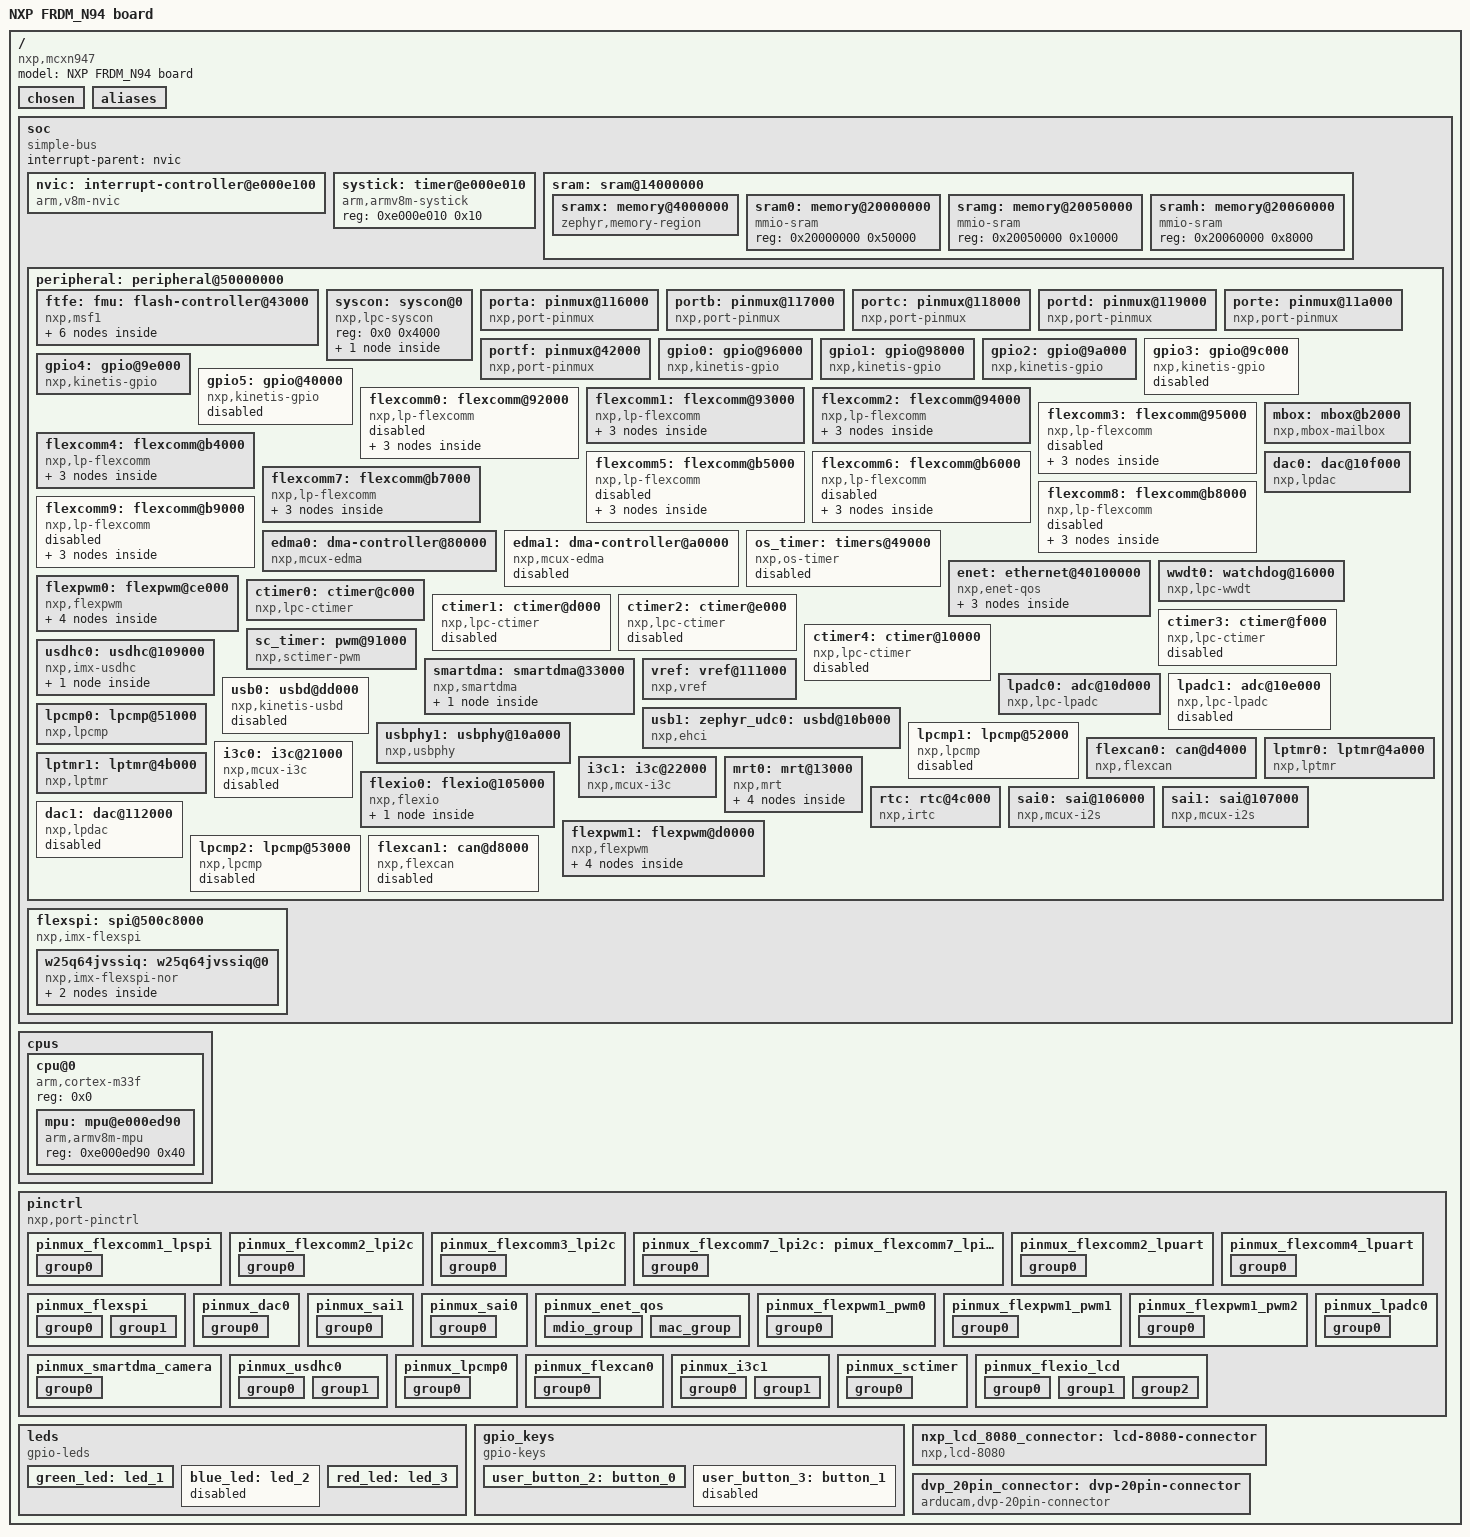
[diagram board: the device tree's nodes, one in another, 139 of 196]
/dts-v1/;

/* node '/' defined in zephyr/dts/common/skeleton.dtsi:9 */
/ {
	#address-cells = < 0x1 >;     /* in zephyr/dts/common/skeleton.dtsi:10 */
	#size-cells = < 0x1 >;        /* in zephyr/dts/common/skeleton.dtsi:11 */
	model = "NXP FRDM_N94 board"; /* in zephyr/boards/nxp/frdm_mcxn947/frdm_mcxn947_mcxn947_cpu0.dts:12 */
	compatible = "nxp,mcxn947",
	             "nxp,mcx";       /* in zephyr/boards/nxp/frdm_mcxn947/frdm_mcxn947_mcxn947_cpu0.dts:13 */

	/* node '/chosen' defined in zephyr/dts/common/skeleton.dtsi:12 */
	chosen {
		zephyr,sram = &sram0;                          /* in zephyr/boards/nxp/frdm_mcxn947/frdm_mcxn947_mcxn947_cpu0.dtsi:22 */
		zephyr,flash = &flash;                         /* in zephyr/boards/nxp/frdm_mcxn947/frdm_mcxn947_mcxn947_cpu0.dtsi:23 */
		zephyr,flash-controller = &fmu;                /* in zephyr/boards/nxp/frdm_mcxn947/frdm_mcxn947_mcxn947_cpu0.dtsi:24 */
		zephyr,code-partition = &slot0_partition;      /* in zephyr/boards/nxp/frdm_mcxn947/frdm_mcxn947_mcxn947_cpu0.dtsi:25 */
		zephyr,uart-mcumgr = &flexcomm4_lpuart4;       /* in zephyr/boards/nxp/frdm_mcxn947/frdm_mcxn947_mcxn947_cpu0.dtsi:26 */
		zephyr,console = &flexcomm4_lpuart4;           /* in zephyr/boards/nxp/frdm_mcxn947/frdm_mcxn947_mcxn947_cpu0.dtsi:27 */
		zephyr,shell-uart = &flexcomm4_lpuart4;        /* in zephyr/boards/nxp/frdm_mcxn947/frdm_mcxn947_mcxn947_cpu0.dtsi:28 */
		zephyr,canbus = &flexcan0;                     /* in zephyr/boards/nxp/frdm_mcxn947/frdm_mcxn947_mcxn947_cpu0.dtsi:29 */
		zephyr,code-cpu1-partition = &slot1_partition; /* in zephyr/boards/nxp/frdm_mcxn947/frdm_mcxn947_mcxn947_cpu0.dtsi:30 */
	};

	/* node '/aliases' defined in zephyr/dts/common/skeleton.dtsi:13 */
	aliases {
		led0 = &red_led;                  /* in zephyr/boards/nxp/frdm_mcxn947/frdm_mcxn947.dtsi:14 */
		led1 = &green_led;                /* in zephyr/boards/nxp/frdm_mcxn947/frdm_mcxn947.dtsi:15 */
		led2 = &blue_led;                 /* in zephyr/boards/nxp/frdm_mcxn947/frdm_mcxn947.dtsi:16 */
		sw0 = &user_button_2;             /* in zephyr/boards/nxp/frdm_mcxn947/frdm_mcxn947.dtsi:17 */
		sw1 = &user_button_3;             /* in zephyr/boards/nxp/frdm_mcxn947/frdm_mcxn947.dtsi:18 */
		sdhc0 = &usdhc0;                  /* in zephyr/boards/nxp/frdm_mcxn947/frdm_mcxn947.dtsi:19 */
		mcuboot-button0 = &user_button_2; /* in zephyr/boards/nxp/frdm_mcxn947/frdm_mcxn947.dtsi:20 */
		watchdog0 = &wwdt0;               /* in zephyr/boards/nxp/frdm_mcxn947/frdm_mcxn947_mcxn947_cpu0.dtsi:34 */
		pwm-0 = &flexpwm1_pwm0;           /* in zephyr/boards/nxp/frdm_mcxn947/frdm_mcxn947_mcxn947_cpu0.dtsi:35 */
		pwm-1 = &sc_timer;                /* in zephyr/boards/nxp/frdm_mcxn947/frdm_mcxn947_mcxn947_cpu0.dtsi:36 */
		rtc = &rtc;                       /* in zephyr/boards/nxp/frdm_mcxn947/frdm_mcxn947_mcxn947_cpu0.dtsi:37 */
	};

	/* node '/soc' defined in zephyr/dts/arm/armv8-m.dtsi:6 */
	soc {
		#address-cells = < 0x1 >;     /* in zephyr/dts/arm/armv8-m.dtsi:7 */
		#size-cells = < 0x1 >;        /* in zephyr/dts/arm/armv8-m.dtsi:8 */
		compatible = "simple-bus";    /* in zephyr/dts/arm/armv8-m.dtsi:9 */
		interrupt-parent = < &nvic >; /* in zephyr/dts/arm/armv8-m.dtsi:10 */
		ranges;                       /* in zephyr/dts/arm/armv8-m.dtsi:11 */

		/* node '/soc/interrupt-controller@e000e100' defined in zephyr/dts/arm/armv8-m.dtsi:13 */
		nvic: interrupt-controller@e000e100 {
			#address-cells = < 0x1 >;            /* in zephyr/dts/arm/armv8-m.dtsi:14 */
			compatible = "arm,v8m-nvic";         /* in zephyr/dts/arm/armv8-m.dtsi:15 */
			reg = < 0xe000e100 0xc00 >;          /* in zephyr/dts/arm/armv8-m.dtsi:16 */
			interrupt-controller;                /* in zephyr/dts/arm/armv8-m.dtsi:17 */
			#interrupt-cells = < 0x2 >;          /* in zephyr/dts/arm/armv8-m.dtsi:18 */
			arm,num-irq-priority-bits = < 0x3 >; /* in zephyr/dts/arm/nxp/nxp_mcxnx4x_common.dtsi:1074 */
			phandle = < 0x1 >;                   /* in zephyr/dts/arm/armv8-m.dtsi:10 */
		};

		/* node '/soc/timer@e000e010' defined in zephyr/dts/arm/armv8-m.dtsi:21 */
		systick: timer@e000e010 {
			compatible = "arm,armv8m-systick"; /* in zephyr/dts/arm/armv8-m.dtsi:22 */
			reg = < 0xe000e010 0x10 >;         /* in zephyr/dts/arm/armv8-m.dtsi:23 */
			status = "okay";                   /* in zephyr/boards/nxp/frdm_mcxn947/frdm_mcxn947.dtsi:128 */
		};

		/* node '/soc/sram@14000000' defined in zephyr/dts/arm/nxp/nxp_mcxn94x.dtsi:12 */
		sram: sram@14000000 {
			ranges = < 0x4000000 0x14000000 0x20000000 >; /* in zephyr/dts/arm/nxp/nxp_mcxn94x.dtsi:13 */
			#address-cells = < 0x1 >;                     /* in zephyr/dts/arm/nxp/nxp_mcxnx4x_common.dtsi:45 */
			#size-cells = < 0x1 >;                        /* in zephyr/dts/arm/nxp/nxp_mcxnx4x_common.dtsi:46 */

			/* node '/soc/sram@14000000/memory@4000000' defined in zephyr/dts/arm/nxp/nxp_mcxnx4x_common.dtsi:48 */
			sramx: memory@4000000 {
				compatible = "zephyr,memory-region",
				             "mmio-sram";            /* in zephyr/dts/arm/nxp/nxp_mcxnx4x_common.dtsi:49 */
				reg = < 0x4000000 0x18000 >;         /* in zephyr/dts/arm/nxp/nxp_mcxnx4x_common.dtsi:50 */
				zephyr,memory-region = "SRAMX";      /* in zephyr/dts/arm/nxp/nxp_mcxnx4x_common.dtsi:51 */
				zephyr,memory-attr = < 0x100000 >;   /* in zephyr/dts/arm/nxp/nxp_mcxnx4x_common.dtsi:52 */
			};

			/* node '/soc/sram@14000000/memory@20000000' defined in zephyr/dts/arm/nxp/nxp_mcxnx4x_common.dtsi:63 */
			sram0: memory@20000000 {
				compatible = "mmio-sram";     /* in zephyr/boards/nxp/frdm_mcxn947/frdm_mcxn947_mcxn947_cpu0.dtsi:51 */
				reg = < 0x20000000 0x50000 >; /* in zephyr/boards/nxp/frdm_mcxn947/frdm_mcxn947_mcxn947_cpu0.dtsi:52 */
			};

			/* node '/soc/sram@14000000/memory@20050000' defined in zephyr/boards/nxp/frdm_mcxn947/frdm_mcxn947.dtsi:132 */
			sramg: memory@20050000 {
				compatible = "mmio-sram";     /* in zephyr/boards/nxp/frdm_mcxn947/frdm_mcxn947.dtsi:133 */
				reg = < 0x20050000 0x10000 >; /* in zephyr/boards/nxp/frdm_mcxn947/frdm_mcxn947.dtsi:134 */
			};

			/* node '/soc/sram@14000000/memory@20060000' defined in zephyr/boards/nxp/frdm_mcxn947/frdm_mcxn947.dtsi:136 */
			sramh: memory@20060000 {
				compatible = "mmio-sram";    /* in zephyr/boards/nxp/frdm_mcxn947/frdm_mcxn947.dtsi:137 */
				reg = < 0x20060000 0x8000 >; /* in zephyr/boards/nxp/frdm_mcxn947/frdm_mcxn947.dtsi:138 */
			};
		};

		/* node '/soc/peripheral@50000000' defined in zephyr/dts/arm/nxp/nxp_mcxn94x.dtsi:16 */
		peripheral: peripheral@50000000 {
			ranges = < 0x0 0x50000000 0x10000000 >; /* in zephyr/dts/arm/nxp/nxp_mcxn94x.dtsi:17 */
			#address-cells = < 0x1 >;               /* in zephyr/dts/arm/nxp/nxp_mcxnx4x_common.dtsi:70 */
			#size-cells = < 0x1 >;                  /* in zephyr/dts/arm/nxp/nxp_mcxnx4x_common.dtsi:71 */

			/* node '/soc/peripheral@50000000/flash-controller@43000' defined in zephyr/dts/arm/nxp/nxp_mcxn94x.dtsi:19 */
			ftfe: fmu: flash-controller@43000 {
				ranges = < 0x0 0x10000000 0x4000000 >; /* in zephyr/dts/arm/nxp/nxp_mcxn94x.dtsi:20 */
				compatible = "nxp,msf1";               /* in zephyr/dts/arm/nxp/nxp_mcxnx4x_common.dtsi:620 */
				reg = < 0x43000 0x1000 >;              /* in zephyr/dts/arm/nxp/nxp_mcxnx4x_common.dtsi:621 */
				interrupts = < 0x8a 0x0 >;             /* in zephyr/dts/arm/nxp/nxp_mcxnx4x_common.dtsi:622 */
				#address-cells = < 0x1 >;              /* in zephyr/dts/arm/nxp/nxp_mcxnx4x_common.dtsi:625 */
				#size-cells = < 0x1 >;                 /* in zephyr/dts/arm/nxp/nxp_mcxnx4x_common.dtsi:626 */
				status = "okay";                       /* in zephyr/dts/arm/nxp/nxp_mcxn94x.dtsi:37 */

				/* node '/soc/peripheral@50000000/flash-controller@43000/flash@0' defined in zephyr/dts/arm/nxp/nxp_mcxnx4x_common.dtsi:628 */
				flash: flash@0 {
					compatible = "soc-nv-flash";   /* in zephyr/dts/arm/nxp/nxp_mcxnx4x_common.dtsi:629 */
					reg = < 0x0 0x200000 >;        /* in zephyr/dts/arm/nxp/nxp_mcxnx4x_common.dtsi:630 */
					erase-block-size = < 0x2000 >; /* in zephyr/dts/arm/nxp/nxp_mcxnx4x_common.dtsi:631 */
					write-block-size = < 0x10 >;   /* in zephyr/dts/arm/nxp/nxp_mcxnx4x_common.dtsi:632 */

					/* node '/soc/peripheral@50000000/flash-controller@43000/flash@0/partitions' defined in zephyr/boards/nxp/frdm_mcxn947/frdm_mcxn947.dtsi:143 */
					partitions {
						compatible = "fixed-partitions"; /* in zephyr/boards/nxp/frdm_mcxn947/frdm_mcxn947.dtsi:144 */
						#address-cells = < 0x1 >;        /* in zephyr/boards/nxp/frdm_mcxn947/frdm_mcxn947.dtsi:145 */
						#size-cells = < 0x1 >;           /* in zephyr/boards/nxp/frdm_mcxn947/frdm_mcxn947.dtsi:146 */

						/* node '/soc/peripheral@50000000/flash-controller@43000/flash@0/partitions/partition@0' defined in zephyr/boards/nxp/frdm_mcxn947/frdm_mcxn947.dtsi:152 */
						boot_partition: partition@0 {
							label = "mcuboot";     /* in zephyr/boards/nxp/frdm_mcxn947/frdm_mcxn947.dtsi:153 */
							reg = < 0x0 0x14000 >; /* in zephyr/boards/nxp/frdm_mcxn947/frdm_mcxn947.dtsi:154 */
						};

						/* node '/soc/peripheral@50000000/flash-controller@43000/flash@0/partitions/partition@14000' defined in zephyr/boards/nxp/frdm_mcxn947/frdm_mcxn947.dtsi:156 */
						slot0_partition: partition@14000 {
							label = "image-0";         /* in zephyr/boards/nxp/frdm_mcxn947/frdm_mcxn947.dtsi:157 */
							reg = < 0x14000 0xf6000 >; /* in zephyr/boards/nxp/frdm_mcxn947/frdm_mcxn947.dtsi:158 */
						};

						/* node '/soc/peripheral@50000000/flash-controller@43000/flash@0/partitions/partition@10A000' defined in zephyr/boards/nxp/frdm_mcxn947/frdm_mcxn947.dtsi:160 */
						slot1_partition: partition@10A000 {
							label = "image-1";          /* in zephyr/boards/nxp/frdm_mcxn947/frdm_mcxn947.dtsi:161 */
							reg = < 0x10a000 0xf6000 >; /* in zephyr/boards/nxp/frdm_mcxn947/frdm_mcxn947.dtsi:162 */
						};
					};
				};

				/* node '/soc/peripheral@50000000/flash-controller@43000/uuid@1100000' defined in zephyr/dts/arm/nxp/nxp_mcxnx4x_common.dtsi:635 */
				uuid: uuid@1100000 {
					compatible = "nxp,lpc-uid"; /* in zephyr/dts/arm/nxp/nxp_mcxnx4x_common.dtsi:636 */
					reg = < 0x1100000 0x10 >;   /* in zephyr/dts/arm/nxp/nxp_mcxnx4x_common.dtsi:637 */
				};
			};

			/* node '/soc/peripheral@50000000/syscon@0' defined in zephyr/dts/arm/nxp/nxp_mcxnx4x_common.dtsi:73 */
			syscon: syscon@0 {
				compatible = "nxp,lpc-syscon"; /* in zephyr/dts/arm/nxp/nxp_mcxnx4x_common.dtsi:74 */
				reg = < 0x0 0x4000 >;          /* in zephyr/dts/arm/nxp/nxp_mcxnx4x_common.dtsi:75 */
				#clock-cells = < 0x1 >;        /* in zephyr/dts/arm/nxp/nxp_mcxnx4x_common.dtsi:76 */
				phandle = < 0x2 >;             /* in zephyr/dts/arm/nxp/nxp_mcxnx4x_common.dtsi:86 */

				/* node '/soc/peripheral@50000000/syscon@0/reset' defined in zephyr/dts/arm/nxp/nxp_mcxnx4x_common.dtsi:77 */
				reset: reset {
					compatible = "nxp,lpc-syscon-reset"; /* in zephyr/dts/arm/nxp/nxp_mcxnx4x_common.dtsi:78 */
					#reset-cells = < 0x1 >;              /* in zephyr/dts/arm/nxp/nxp_mcxnx4x_common.dtsi:79 */
					phandle = < 0x1f >;                  /* in zephyr/dts/arm/nxp/nxp_mcxnx4x_common.dtsi:981 */
				};
			};

			/* node '/soc/peripheral@50000000/pinmux@116000' defined in zephyr/dts/arm/nxp/nxp_mcxnx4x_common.dtsi:83 */
			porta: pinmux@116000 {
				compatible = "nxp,port-pinmux"; /* in zephyr/dts/arm/nxp/nxp_mcxnx4x_common.dtsi:84 */
				reg = < 0x116000 0x1000 >;      /* in zephyr/dts/arm/nxp/nxp_mcxnx4x_common.dtsi:85 */
				clocks = < &syscon 0xc00 >;     /* in zephyr/dts/arm/nxp/nxp_mcxnx4x_common.dtsi:86 */
				phandle = < 0x3 >;              /* in zephyr/dts/arm/nxp/nxp_mcxnx4x_common.dtsi:126 */
			};

			/* node '/soc/peripheral@50000000/pinmux@117000' defined in zephyr/dts/arm/nxp/nxp_mcxnx4x_common.dtsi:89 */
			portb: pinmux@117000 {
				compatible = "nxp,port-pinmux"; /* in zephyr/dts/arm/nxp/nxp_mcxnx4x_common.dtsi:90 */
				reg = < 0x117000 0x1000 >;      /* in zephyr/dts/arm/nxp/nxp_mcxnx4x_common.dtsi:91 */
				clocks = < &syscon 0xc01 >;     /* in zephyr/dts/arm/nxp/nxp_mcxnx4x_common.dtsi:92 */
				phandle = < 0x4 >;              /* in zephyr/dts/arm/nxp/nxp_mcxnx4x_common.dtsi:136 */
			};

			/* node '/soc/peripheral@50000000/pinmux@118000' defined in zephyr/dts/arm/nxp/nxp_mcxnx4x_common.dtsi:95 */
			portc: pinmux@118000 {
				compatible = "nxp,port-pinmux"; /* in zephyr/dts/arm/nxp/nxp_mcxnx4x_common.dtsi:96 */
				reg = < 0x118000 0x1000 >;      /* in zephyr/dts/arm/nxp/nxp_mcxnx4x_common.dtsi:97 */
				clocks = < &syscon 0xc02 >;     /* in zephyr/dts/arm/nxp/nxp_mcxnx4x_common.dtsi:98 */
				phandle = < 0x5 >;              /* in zephyr/dts/arm/nxp/nxp_mcxnx4x_common.dtsi:146 */
			};

			/* node '/soc/peripheral@50000000/pinmux@119000' defined in zephyr/dts/arm/nxp/nxp_mcxnx4x_common.dtsi:101 */
			portd: pinmux@119000 {
				compatible = "nxp,port-pinmux"; /* in zephyr/dts/arm/nxp/nxp_mcxnx4x_common.dtsi:102 */
				reg = < 0x119000 0x1000 >;      /* in zephyr/dts/arm/nxp/nxp_mcxnx4x_common.dtsi:103 */
				clocks = < &syscon 0xc03 >;     /* in zephyr/dts/arm/nxp/nxp_mcxnx4x_common.dtsi:104 */
				phandle = < 0x6 >;              /* in zephyr/dts/arm/nxp/nxp_mcxnx4x_common.dtsi:156 */
			};

			/* node '/soc/peripheral@50000000/pinmux@11a000' defined in zephyr/dts/arm/nxp/nxp_mcxnx4x_common.dtsi:107 */
			porte: pinmux@11a000 {
				compatible = "nxp,port-pinmux"; /* in zephyr/dts/arm/nxp/nxp_mcxnx4x_common.dtsi:108 */
				reg = < 0x11a000 0x1000 >;      /* in zephyr/dts/arm/nxp/nxp_mcxnx4x_common.dtsi:109 */
				clocks = < &syscon 0xc04 >;     /* in zephyr/dts/arm/nxp/nxp_mcxnx4x_common.dtsi:110 */
				phandle = < 0x7 >;              /* in zephyr/dts/arm/nxp/nxp_mcxnx4x_common.dtsi:166 */
			};

			/* node '/soc/peripheral@50000000/pinmux@42000' defined in zephyr/dts/arm/nxp/nxp_mcxnx4x_common.dtsi:113 */
			portf: pinmux@42000 {
				compatible = "nxp,port-pinmux"; /* in zephyr/dts/arm/nxp/nxp_mcxnx4x_common.dtsi:114 */
				reg = < 0x42000 0x1000 >;       /* in zephyr/dts/arm/nxp/nxp_mcxnx4x_common.dtsi:115 */
				clocks = < &syscon 0xc05 >;     /* in zephyr/dts/arm/nxp/nxp_mcxnx4x_common.dtsi:116 */
				phandle = < 0x8 >;              /* in zephyr/dts/arm/nxp/nxp_mcxnx4x_common.dtsi:176 */
			};

			/* node '/soc/peripheral@50000000/gpio@96000' defined in zephyr/dts/arm/nxp/nxp_mcxnx4x_common.dtsi:119 */
			gpio0: gpio@96000 {
				compatible = "nxp,kinetis-gpio"; /* in zephyr/dts/arm/nxp/nxp_mcxnx4x_common.dtsi:120 */
				reg = < 0x96000 0x1000 >;        /* in zephyr/dts/arm/nxp/nxp_mcxnx4x_common.dtsi:122 */
				interrupts = < 0x11 0x0 >,
				             < 0x12 0x0 >;       /* in zephyr/dts/arm/nxp/nxp_mcxnx4x_common.dtsi:123 */
				gpio-controller;                 /* in zephyr/dts/arm/nxp/nxp_mcxnx4x_common.dtsi:124 */
				#gpio-cells = < 0x2 >;           /* in zephyr/dts/arm/nxp/nxp_mcxnx4x_common.dtsi:125 */
				nxp,kinetis-port = < &porta >;   /* in zephyr/dts/arm/nxp/nxp_mcxnx4x_common.dtsi:126 */
				status = "okay";                 /* in zephyr/boards/nxp/frdm_mcxn947/frdm_mcxn947_mcxn947_cpu0.dtsi:68 */
				phandle = < 0x1d >;              /* in zephyr/boards/nxp/frdm_mcxn947/frdm_mcxn947.dtsi:260 */
			};

			/* node '/soc/peripheral@50000000/gpio@98000' defined in zephyr/dts/arm/nxp/nxp_mcxnx4x_common.dtsi:129 */
			gpio1: gpio@98000 {
				compatible = "nxp,kinetis-gpio"; /* in zephyr/dts/arm/nxp/nxp_mcxnx4x_common.dtsi:130 */
				reg = < 0x98000 0x1000 >;        /* in zephyr/dts/arm/nxp/nxp_mcxnx4x_common.dtsi:132 */
				interrupts = < 0x13 0x0 >,
				             < 0x14 0x0 >;       /* in zephyr/dts/arm/nxp/nxp_mcxnx4x_common.dtsi:133 */
				gpio-controller;                 /* in zephyr/dts/arm/nxp/nxp_mcxnx4x_common.dtsi:134 */
				#gpio-cells = < 0x2 >;           /* in zephyr/dts/arm/nxp/nxp_mcxnx4x_common.dtsi:135 */
				nxp,kinetis-port = < &portb >;   /* in zephyr/dts/arm/nxp/nxp_mcxnx4x_common.dtsi:136 */
				status = "okay";                 /* in zephyr/boards/nxp/frdm_mcxn947/frdm_mcxn947_mcxn947_cpu0.dtsi:64 */
				phandle = < 0x26 >;              /* in zephyr/boards/nxp/frdm_mcxn947/frdm_mcxn947.dtsi:31 */
			};

			/* node '/soc/peripheral@50000000/gpio@9a000' defined in zephyr/dts/arm/nxp/nxp_mcxnx4x_common.dtsi:139 */
			gpio2: gpio@9a000 {
				compatible = "nxp,kinetis-gpio"; /* in zephyr/dts/arm/nxp/nxp_mcxnx4x_common.dtsi:140 */
				reg = < 0x9a000 0x1000 >;        /* in zephyr/dts/arm/nxp/nxp_mcxnx4x_common.dtsi:142 */
				interrupts = < 0x15 0x0 >,
				             < 0x16 0x0 >;       /* in zephyr/dts/arm/nxp/nxp_mcxnx4x_common.dtsi:143 */
				gpio-controller;                 /* in zephyr/dts/arm/nxp/nxp_mcxnx4x_common.dtsi:144 */
				#gpio-cells = < 0x2 >;           /* in zephyr/dts/arm/nxp/nxp_mcxnx4x_common.dtsi:145 */
				nxp,kinetis-port = < &portc >;   /* in zephyr/dts/arm/nxp/nxp_mcxnx4x_common.dtsi:146 */
				status = "okay";                 /* in zephyr/boards/nxp/frdm_mcxn947/frdm_mcxn947_mcxn947_cpu0.dtsi:72 */
				phandle = < 0x15 >;              /* in zephyr/boards/nxp/frdm_mcxn947/frdm_mcxn947.dtsi:240 */
			};

			/* node '/soc/peripheral@50000000/gpio@9c000' defined in zephyr/dts/arm/nxp/nxp_mcxnx4x_common.dtsi:149 */
			gpio3: gpio@9c000 {
				compatible = "nxp,kinetis-gpio"; /* in zephyr/dts/arm/nxp/nxp_mcxnx4x_common.dtsi:150 */
				status = "disabled";             /* in zephyr/dts/arm/nxp/nxp_mcxnx4x_common.dtsi:151 */
				reg = < 0x9c000 0x1000 >;        /* in zephyr/dts/arm/nxp/nxp_mcxnx4x_common.dtsi:152 */
				interrupts = < 0x17 0x0 >,
				             < 0x18 0x0 >;       /* in zephyr/dts/arm/nxp/nxp_mcxnx4x_common.dtsi:153 */
				gpio-controller;                 /* in zephyr/dts/arm/nxp/nxp_mcxnx4x_common.dtsi:154 */
				#gpio-cells = < 0x2 >;           /* in zephyr/dts/arm/nxp/nxp_mcxnx4x_common.dtsi:155 */
				nxp,kinetis-port = < &portd >;   /* in zephyr/dts/arm/nxp/nxp_mcxnx4x_common.dtsi:156 */
			};

			/* node '/soc/peripheral@50000000/gpio@9e000' defined in zephyr/dts/arm/nxp/nxp_mcxnx4x_common.dtsi:159 */
			gpio4: gpio@9e000 {
				compatible = "nxp,kinetis-gpio"; /* in zephyr/dts/arm/nxp/nxp_mcxnx4x_common.dtsi:160 */
				reg = < 0x9e000 0x1000 >;        /* in zephyr/dts/arm/nxp/nxp_mcxnx4x_common.dtsi:162 */
				interrupts = < 0x19 0x0 >,
				             < 0x1a 0x0 >;       /* in zephyr/dts/arm/nxp/nxp_mcxnx4x_common.dtsi:163 */
				gpio-controller;                 /* in zephyr/dts/arm/nxp/nxp_mcxnx4x_common.dtsi:164 */
				#gpio-cells = < 0x2 >;           /* in zephyr/dts/arm/nxp/nxp_mcxnx4x_common.dtsi:165 */
				nxp,kinetis-port = < &porte >;   /* in zephyr/dts/arm/nxp/nxp_mcxnx4x_common.dtsi:166 */
				status = "okay";                 /* in zephyr/boards/nxp/frdm_mcxn947/frdm_mcxn947_mcxn947_cpu0.dtsi:60 */
				phandle = < 0x1c >;              /* in zephyr/boards/nxp/frdm_mcxn947/frdm_mcxn947.dtsi:259 */
			};

			/* node '/soc/peripheral@50000000/gpio@40000' defined in zephyr/dts/arm/nxp/nxp_mcxnx4x_common.dtsi:169 */
			gpio5: gpio@40000 {
				compatible = "nxp,kinetis-gpio"; /* in zephyr/dts/arm/nxp/nxp_mcxnx4x_common.dtsi:170 */
				status = "disabled";             /* in zephyr/dts/arm/nxp/nxp_mcxnx4x_common.dtsi:171 */
				reg = < 0x40000 0x1000 >;        /* in zephyr/dts/arm/nxp/nxp_mcxnx4x_common.dtsi:172 */
				interrupts = < 0x1b 0x0 >,
				             < 0x1c 0x0 >;       /* in zephyr/dts/arm/nxp/nxp_mcxnx4x_common.dtsi:173 */
				gpio-controller;                 /* in zephyr/dts/arm/nxp/nxp_mcxnx4x_common.dtsi:174 */
				#gpio-cells = < 0x2 >;           /* in zephyr/dts/arm/nxp/nxp_mcxnx4x_common.dtsi:175 */
				nxp,kinetis-port = < &portf >;   /* in zephyr/dts/arm/nxp/nxp_mcxnx4x_common.dtsi:176 */
			};

			/* node '/soc/peripheral@50000000/flexcomm@92000' defined in zephyr/dts/arm/nxp/nxp_mcxnx4x_common.dtsi:179 */
			flexcomm0: flexcomm@92000 {
				compatible = "nxp,lp-flexcomm"; /* in zephyr/dts/arm/nxp/nxp_mcxnx4x_common.dtsi:180 */
				reg = < 0x92000 0x1000 >;       /* in zephyr/dts/arm/nxp/nxp_mcxnx4x_common.dtsi:181 */
				interrupts = < 0x23 0x0 >;      /* in zephyr/dts/arm/nxp/nxp_mcxnx4x_common.dtsi:182 */
				status = "disabled";            /* in zephyr/dts/arm/nxp/nxp_mcxnx4x_common.dtsi:183 */
				ranges;                         /* in zephyr/dts/arm/nxp/nxp_mcxnx4x_common.dtsi:186 */
				#address-cells = < 0x1 >;       /* in zephyr/dts/arm/nxp/nxp_mcxnx4x_common.dtsi:187 */
				#size-cells = < 0x1 >;          /* in zephyr/dts/arm/nxp/nxp_mcxnx4x_common.dtsi:188 */

				/* node '/soc/peripheral@50000000/flexcomm@92000/lpuart@92000' defined in zephyr/dts/arm/nxp/nxp_mcxnx4x_common.dtsi:190 */
				flexcomm0_lpuart0: lpuart@92000 {
					compatible = "nxp,lpuart";  /* in zephyr/dts/arm/nxp/nxp_mcxnx4x_common.dtsi:191 */
					reg = < 0x92000 0x1000 >;   /* in zephyr/dts/arm/nxp/nxp_mcxnx4x_common.dtsi:192 */
					clocks = < &syscon 0x100 >; /* in zephyr/dts/arm/nxp/nxp_mcxnx4x_common.dtsi:193 */
					status = "disabled";        /* in zephyr/dts/arm/nxp/nxp_mcxnx4x_common.dtsi:194 */
				};

				/* node '/soc/peripheral@50000000/flexcomm@92000/spi@92000' defined in zephyr/dts/arm/nxp/nxp_mcxnx4x_common.dtsi:197 */
				flexcomm0_lpspi0: spi@92000 {
					compatible = "nxp,lpspi";   /* in zephyr/dts/arm/nxp/nxp_mcxnx4x_common.dtsi:198 */
					reg = < 0x92000 0x1000 >;   /* in zephyr/dts/arm/nxp/nxp_mcxnx4x_common.dtsi:199 */
					clocks = < &syscon 0x100 >; /* in zephyr/dts/arm/nxp/nxp_mcxnx4x_common.dtsi:200 */
					#address-cells = < 0x1 >;   /* in zephyr/dts/arm/nxp/nxp_mcxnx4x_common.dtsi:201 */
					#size-cells = < 0x0 >;      /* in zephyr/dts/arm/nxp/nxp_mcxnx4x_common.dtsi:202 */
					tx-fifo-size = < 0x8 >;     /* in zephyr/dts/arm/nxp/nxp_mcxnx4x_common.dtsi:203 */
					rx-fifo-size = < 0x8 >;     /* in zephyr/dts/arm/nxp/nxp_mcxnx4x_common.dtsi:204 */
					status = "disabled";        /* in zephyr/dts/arm/nxp/nxp_mcxnx4x_common.dtsi:205 */
				};

				/* node '/soc/peripheral@50000000/flexcomm@92000/lpi2c@92800' defined in zephyr/dts/arm/nxp/nxp_mcxnx4x_common.dtsi:208 */
				flexcomm0_lpi2c0: lpi2c@92800 {
					compatible = "nxp,lpi2c";   /* in zephyr/dts/arm/nxp/nxp_mcxnx4x_common.dtsi:209 */
					reg = < 0x92800 0x1000 >;   /* in zephyr/dts/arm/nxp/nxp_mcxnx4x_common.dtsi:210 */
					clocks = < &syscon 0x100 >; /* in zephyr/dts/arm/nxp/nxp_mcxnx4x_common.dtsi:211 */
					#address-cells = < 0x1 >;   /* in zephyr/dts/arm/nxp/nxp_mcxnx4x_common.dtsi:212 */
					#size-cells = < 0x0 >;      /* in zephyr/dts/arm/nxp/nxp_mcxnx4x_common.dtsi:213 */
					status = "disabled";        /* in zephyr/dts/arm/nxp/nxp_mcxnx4x_common.dtsi:214 */
				};
			};

			/* node '/soc/peripheral@50000000/flexcomm@93000' defined in zephyr/dts/arm/nxp/nxp_mcxnx4x_common.dtsi:218 */
			flexcomm1: flexcomm@93000 {
				compatible = "nxp,lp-flexcomm"; /* in zephyr/dts/arm/nxp/nxp_mcxnx4x_common.dtsi:219 */
				reg = < 0x93000 0x1000 >;       /* in zephyr/dts/arm/nxp/nxp_mcxnx4x_common.dtsi:220 */
				interrupts = < 0x24 0x0 >;      /* in zephyr/dts/arm/nxp/nxp_mcxnx4x_common.dtsi:221 */
				ranges;                         /* in zephyr/dts/arm/nxp/nxp_mcxnx4x_common.dtsi:224 */
				#address-cells = < 0x1 >;       /* in zephyr/dts/arm/nxp/nxp_mcxnx4x_common.dtsi:225 */
				#size-cells = < 0x1 >;          /* in zephyr/dts/arm/nxp/nxp_mcxnx4x_common.dtsi:226 */
				status = "okay";                /* in zephyr/boards/nxp/frdm_mcxn947/frdm_mcxn947_mcxn947_cpu0.dtsi:92 */

				/* node '/soc/peripheral@50000000/flexcomm@93000/lpuart@93000' defined in zephyr/dts/arm/nxp/nxp_mcxnx4x_common.dtsi:228 */
				flexcomm1_lpuart1: lpuart@93000 {
					compatible = "nxp,lpuart";  /* in zephyr/dts/arm/nxp/nxp_mcxnx4x_common.dtsi:229 */
					reg = < 0x93000 0x1000 >;   /* in zephyr/dts/arm/nxp/nxp_mcxnx4x_common.dtsi:230 */
					clocks = < &syscon 0x101 >; /* in zephyr/dts/arm/nxp/nxp_mcxnx4x_common.dtsi:231 */
					dmas = < &edma0 0x0 0x47 >,
					       < &edma0 0x1 0x48 >; /* in zephyr/dts/arm/nxp/nxp_mcxnx4x_common.dtsi:233 */
					dma-names = "rx",
					            "tx";           /* in zephyr/dts/arm/nxp/nxp_mcxnx4x_common.dtsi:234 */
					status = "disabled";        /* in zephyr/dts/arm/nxp/nxp_mcxnx4x_common.dtsi:235 */
				};

				/* node '/soc/peripheral@50000000/flexcomm@93000/spi@93000' defined in zephyr/dts/arm/nxp/nxp_mcxnx4x_common.dtsi:238 */
				flexcomm1_lpspi1: spi@93000 {
					compatible = "nxp,lpspi";                /* in zephyr/dts/arm/nxp/nxp_mcxnx4x_common.dtsi:239 */
					reg = < 0x93000 0x1000 >;                /* in zephyr/dts/arm/nxp/nxp_mcxnx4x_common.dtsi:240 */
					clocks = < &syscon 0x101 >;              /* in zephyr/dts/arm/nxp/nxp_mcxnx4x_common.dtsi:241 */
					#address-cells = < 0x1 >;                /* in zephyr/dts/arm/nxp/nxp_mcxnx4x_common.dtsi:242 */
					#size-cells = < 0x0 >;                   /* in zephyr/dts/arm/nxp/nxp_mcxnx4x_common.dtsi:243 */
					dmas = < &edma0 0x0 0x47 >,
					       < &edma0 0x1 0x48 >;              /* in zephyr/dts/arm/nxp/nxp_mcxnx4x_common.dtsi:245 */
					dma-names = "rx",
					            "tx";                        /* in zephyr/dts/arm/nxp/nxp_mcxnx4x_common.dtsi:246 */
					tx-fifo-size = < 0x8 >;                  /* in zephyr/dts/arm/nxp/nxp_mcxnx4x_common.dtsi:247 */
					rx-fifo-size = < 0x8 >;                  /* in zephyr/dts/arm/nxp/nxp_mcxnx4x_common.dtsi:248 */
					pinctrl-0 = < &pinmux_flexcomm1_lpspi >; /* in zephyr/boards/nxp/frdm_mcxn947/frdm_mcxn947.dtsi:73 */
					pinctrl-names = "default";               /* in zephyr/boards/nxp/frdm_mcxn947/frdm_mcxn947.dtsi:74 */
					status = "okay";                         /* in zephyr/boards/nxp/frdm_mcxn947/frdm_mcxn947_mcxn947_cpu0.dtsi:96 */
				};

				/* node '/soc/peripheral@50000000/flexcomm@93000/lpi2c@93800' defined in zephyr/dts/arm/nxp/nxp_mcxnx4x_common.dtsi:252 */
				flexcomm1_lpi2c1: lpi2c@93800 {
					compatible = "nxp,lpi2c";   /* in zephyr/dts/arm/nxp/nxp_mcxnx4x_common.dtsi:253 */
					reg = < 0x93800 0x1000 >;   /* in zephyr/dts/arm/nxp/nxp_mcxnx4x_common.dtsi:254 */
					clocks = < &syscon 0x101 >; /* in zephyr/dts/arm/nxp/nxp_mcxnx4x_common.dtsi:255 */
					#address-cells = < 0x1 >;   /* in zephyr/dts/arm/nxp/nxp_mcxnx4x_common.dtsi:256 */
					#size-cells = < 0x0 >;      /* in zephyr/dts/arm/nxp/nxp_mcxnx4x_common.dtsi:257 */
					status = "disabled";        /* in zephyr/dts/arm/nxp/nxp_mcxnx4x_common.dtsi:258 */
				};
			};

			/* node '/soc/peripheral@50000000/flexcomm@94000' defined in zephyr/dts/arm/nxp/nxp_mcxnx4x_common.dtsi:262 */
			flexcomm2: flexcomm@94000 {
				compatible = "nxp,lp-flexcomm"; /* in zephyr/dts/arm/nxp/nxp_mcxnx4x_common.dtsi:263 */
				reg = < 0x94000 0x1000 >;       /* in zephyr/dts/arm/nxp/nxp_mcxnx4x_common.dtsi:264 */
				interrupts = < 0x25 0x0 >;      /* in zephyr/dts/arm/nxp/nxp_mcxnx4x_common.dtsi:265 */
				ranges;                         /* in zephyr/dts/arm/nxp/nxp_mcxnx4x_common.dtsi:268 */
				#address-cells = < 0x1 >;       /* in zephyr/dts/arm/nxp/nxp_mcxnx4x_common.dtsi:269 */
				#size-cells = < 0x1 >;          /* in zephyr/dts/arm/nxp/nxp_mcxnx4x_common.dtsi:270 */
				status = "okay";                /* in zephyr/boards/nxp/frdm_mcxn947/frdm_mcxn947_mcxn947_cpu0.dtsi:100 */

				/* node '/soc/peripheral@50000000/flexcomm@94000/lpuart@94000' defined in zephyr/dts/arm/nxp/nxp_mcxnx4x_common.dtsi:272 */
				flexcomm2_lpuart2: lpuart@94000 {
					compatible = "nxp,lpuart";                /* in zephyr/dts/arm/nxp/nxp_mcxnx4x_common.dtsi:273 */
					reg = < 0x94000 0x1000 >;                 /* in zephyr/dts/arm/nxp/nxp_mcxnx4x_common.dtsi:274 */
					clocks = < &syscon 0x102 >;               /* in zephyr/dts/arm/nxp/nxp_mcxnx4x_common.dtsi:275 */
					dmas = < &edma0 0x4 0x49 >,
					       < &edma0 0x5 0x4a >;               /* in zephyr/dts/arm/nxp/nxp_mcxnx4x_common.dtsi:277 */
					dma-names = "rx",
					            "tx";                         /* in zephyr/dts/arm/nxp/nxp_mcxnx4x_common.dtsi:278 */
					current-speed = < 0x1c200 >;              /* in zephyr/boards/nxp/frdm_mcxn947/frdm_mcxn947.dtsi:84 */
					pinctrl-0 = < &pinmux_flexcomm2_lpuart >; /* in zephyr/boards/nxp/frdm_mcxn947/frdm_mcxn947.dtsi:85 */
					pinctrl-names = "default";                /* in zephyr/boards/nxp/frdm_mcxn947/frdm_mcxn947.dtsi:86 */
					status = "okay";                          /* in zephyr/boards/nxp/frdm_mcxn947/frdm_mcxn947_mcxn947_cpu0.dtsi:112 */
				};

				/* node '/soc/peripheral@50000000/flexcomm@94000/spi@94000' defined in zephyr/dts/arm/nxp/nxp_mcxnx4x_common.dtsi:282 */
				flexcomm2_lpspi2: spi@94000 {
					compatible = "nxp,lpspi";   /* in zephyr/dts/arm/nxp/nxp_mcxnx4x_common.dtsi:283 */
					reg = < 0x94000 0x1000 >;   /* in zephyr/dts/arm/nxp/nxp_mcxnx4x_common.dtsi:284 */
					clocks = < &syscon 0x102 >; /* in zephyr/dts/arm/nxp/nxp_mcxnx4x_common.dtsi:285 */
					#address-cells = < 0x1 >;   /* in zephyr/dts/arm/nxp/nxp_mcxnx4x_common.dtsi:286 */
					#size-cells = < 0x0 >;      /* in zephyr/dts/arm/nxp/nxp_mcxnx4x_common.dtsi:287 */
					dmas = < &edma0 0x4 0x49 >,
					       < &edma0 0x5 0x4a >; /* in zephyr/dts/arm/nxp/nxp_mcxnx4x_common.dtsi:289 */
					dma-names = "rx",
					            "tx";           /* in zephyr/dts/arm/nxp/nxp_mcxnx4x_common.dtsi:290 */
					tx-fifo-size = < 0x8 >;     /* in zephyr/dts/arm/nxp/nxp_mcxnx4x_common.dtsi:291 */
					rx-fifo-size = < 0x8 >;     /* in zephyr/dts/arm/nxp/nxp_mcxnx4x_common.dtsi:292 */
					status = "disabled";        /* in zephyr/dts/arm/nxp/nxp_mcxnx4x_common.dtsi:293 */
				};

				/* node '/soc/peripheral@50000000/flexcomm@94000/lpi2c@94800' defined in zephyr/dts/arm/nxp/nxp_mcxnx4x_common.dtsi:296 */
				flexcomm2_lpi2c2: nxp_8080_touch_panel_i2c: lpi2c@94800 {
					compatible = "nxp,lpi2c";                /* in zephyr/dts/arm/nxp/nxp_mcxnx4x_common.dtsi:297 */
					reg = < 0x94800 0x1000 >;                /* in zephyr/dts/arm/nxp/nxp_mcxnx4x_common.dtsi:298 */
					clocks = < &syscon 0x102 >;              /* in zephyr/dts/arm/nxp/nxp_mcxnx4x_common.dtsi:299 */
					#address-cells = < 0x1 >;                /* in zephyr/dts/arm/nxp/nxp_mcxnx4x_common.dtsi:300 */
					#size-cells = < 0x0 >;                   /* in zephyr/dts/arm/nxp/nxp_mcxnx4x_common.dtsi:301 */
					pinctrl-0 = < &pinmux_flexcomm2_lpi2c >; /* in zephyr/boards/nxp/frdm_mcxn947/frdm_mcxn947.dtsi:78 */
					pinctrl-names = "default";               /* in zephyr/boards/nxp/frdm_mcxn947/frdm_mcxn947.dtsi:79 */
					clock-frequency = < 0x186a0 >;           /* in zephyr/boards/nxp/frdm_mcxn947/frdm_mcxn947.dtsi:80 */
					status = "okay";                         /* in zephyr/boards/nxp/frdm_mcxn947/frdm_mcxn947_mcxn947_cpu0.dtsi:104 */
				};
			};

			/* node '/soc/peripheral@50000000/flexcomm@95000' defined in zephyr/dts/arm/nxp/nxp_mcxnx4x_common.dtsi:306 */
			flexcomm3: flexcomm@95000 {
				compatible = "nxp,lp-flexcomm"; /* in zephyr/dts/arm/nxp/nxp_mcxnx4x_common.dtsi:307 */
				reg = < 0x95000 0x1000 >;       /* in zephyr/dts/arm/nxp/nxp_mcxnx4x_common.dtsi:308 */
				interrupts = < 0x26 0x0 >;      /* in zephyr/dts/arm/nxp/nxp_mcxnx4x_common.dtsi:309 */
				status = "disabled";            /* in zephyr/dts/arm/nxp/nxp_mcxnx4x_common.dtsi:310 */
				ranges;                         /* in zephyr/dts/arm/nxp/nxp_mcxnx4x_common.dtsi:312 */
				#address-cells = < 0x1 >;       /* in zephyr/dts/arm/nxp/nxp_mcxnx4x_common.dtsi:313 */
				#size-cells = < 0x1 >;          /* in zephyr/dts/arm/nxp/nxp_mcxnx4x_common.dtsi:314 */

				/* node '/soc/peripheral@50000000/flexcomm@95000/lpuart@95000' defined in zephyr/dts/arm/nxp/nxp_mcxnx4x_common.dtsi:316 */
				flexcomm3_lpuart3: lpuart@95000 {
					compatible = "nxp,lpuart";  /* in zephyr/dts/arm/nxp/nxp_mcxnx4x_common.dtsi:317 */
					reg = < 0x95000 0x1000 >;   /* in zephyr/dts/arm/nxp/nxp_mcxnx4x_common.dtsi:318 */
					clocks = < &syscon 0x103 >; /* in zephyr/dts/arm/nxp/nxp_mcxnx4x_common.dtsi:319 */
					status = "disabled";        /* in zephyr/dts/arm/nxp/nxp_mcxnx4x_common.dtsi:320 */
				};

				/* node '/soc/peripheral@50000000/flexcomm@95000/spi@95000' defined in zephyr/dts/arm/nxp/nxp_mcxnx4x_common.dtsi:323 */
				flexcomm3_lpspi3: spi@95000 {
					compatible = "nxp,lpspi";   /* in zephyr/dts/arm/nxp/nxp_mcxnx4x_common.dtsi:324 */
					reg = < 0x95000 0x1000 >;   /* in zephyr/dts/arm/nxp/nxp_mcxnx4x_common.dtsi:325 */
					clocks = < &syscon 0x103 >; /* in zephyr/dts/arm/nxp/nxp_mcxnx4x_common.dtsi:326 */
					#address-cells = < 0x1 >;   /* in zephyr/dts/arm/nxp/nxp_mcxnx4x_common.dtsi:327 */
					#size-cells = < 0x0 >;      /* in zephyr/dts/arm/nxp/nxp_mcxnx4x_common.dtsi:328 */
					tx-fifo-size = < 0x8 >;     /* in zephyr/dts/arm/nxp/nxp_mcxnx4x_common.dtsi:329 */
					rx-fifo-size = < 0x8 >;     /* in zephyr/dts/arm/nxp/nxp_mcxnx4x_common.dtsi:330 */
					status = "disabled";        /* in zephyr/dts/arm/nxp/nxp_mcxnx4x_common.dtsi:331 */
				};

				/* node '/soc/peripheral@50000000/flexcomm@95000/lpi2c@95800' defined in zephyr/dts/arm/nxp/nxp_mcxnx4x_common.dtsi:334 */
				flexcomm3_lpi2c3: lpi2c@95800 {
					compatible = "nxp,lpi2c";   /* in zephyr/dts/arm/nxp/nxp_mcxnx4x_common.dtsi:335 */
					reg = < 0x95800 0x1000 >;   /* in zephyr/dts/arm/nxp/nxp_mcxnx4x_common.dtsi:336 */
					clocks = < &syscon 0x103 >; /* in zephyr/dts/arm/nxp/nxp_mcxnx4x_common.dtsi:337 */
					#address-cells = < 0x1 >;   /* in zephyr/dts/arm/nxp/nxp_mcxnx4x_common.dtsi:338 */
					#size-cells = < 0x0 >;      /* in zephyr/dts/arm/nxp/nxp_mcxnx4x_common.dtsi:339 */
					status = "disabled";        /* in zephyr/dts/arm/nxp/nxp_mcxnx4x_common.dtsi:340 */
				};
			};

			/* node '/soc/peripheral@50000000/flexcomm@b4000' defined in zephyr/dts/arm/nxp/nxp_mcxnx4x_common.dtsi:344 */
			flexcomm4: flexcomm@b4000 {
				compatible = "nxp,lp-flexcomm"; /* in zephyr/dts/arm/nxp/nxp_mcxnx4x_common.dtsi:345 */
				reg = < 0xb4000 0x1000 >;       /* in zephyr/dts/arm/nxp/nxp_mcxnx4x_common.dtsi:346 */
				interrupts = < 0x27 0x0 >;      /* in zephyr/dts/arm/nxp/nxp_mcxnx4x_common.dtsi:347 */
				ranges;                         /* in zephyr/dts/arm/nxp/nxp_mcxnx4x_common.dtsi:350 */
				#address-cells = < 0x1 >;       /* in zephyr/dts/arm/nxp/nxp_mcxnx4x_common.dtsi:351 */
				#size-cells = < 0x1 >;          /* in zephyr/dts/arm/nxp/nxp_mcxnx4x_common.dtsi:352 */
				status = "okay";                /* in zephyr/boards/nxp/frdm_mcxn947/frdm_mcxn947_mcxn947_cpu0.dtsi:116 */

				/* node '/soc/peripheral@50000000/flexcomm@b4000/lpuart@b4000' defined in zephyr/dts/arm/nxp/nxp_mcxnx4x_common.dtsi:354 */
				flexcomm4_lpuart4: lpuart@b4000 {
					compatible = "nxp,lpuart";                /* in zephyr/dts/arm/nxp/nxp_mcxnx4x_common.dtsi:355 */
					reg = < 0xb4000 0x1000 >;                 /* in zephyr/dts/arm/nxp/nxp_mcxnx4x_common.dtsi:356 */
					clocks = < &syscon 0x104 >;               /* in zephyr/dts/arm/nxp/nxp_mcxnx4x_common.dtsi:357 */
					dmas = < &edma0 0x2 0x4d >,
					       < &edma0 0x3 0x4e >;               /* in zephyr/dts/arm/nxp/nxp_mcxnx4x_common.dtsi:359 */
					dma-names = "rx",
					            "tx";                         /* in zephyr/dts/arm/nxp/nxp_mcxnx4x_common.dtsi:360 */
					current-speed = < 0x1c200 >;              /* in zephyr/boards/nxp/frdm_mcxn947/frdm_mcxn947.dtsi:90 */
					pinctrl-0 = < &pinmux_flexcomm4_lpuart >; /* in zephyr/boards/nxp/frdm_mcxn947/frdm_mcxn947.dtsi:91 */
					pinctrl-names = "default";                /* in zephyr/boards/nxp/frdm_mcxn947/frdm_mcxn947.dtsi:92 */
					status = "okay";                          /* in zephyr/boards/nxp/frdm_mcxn947/frdm_mcxn947_mcxn947_cpu0.dtsi:120 */
				};

				/* node '/soc/peripheral@50000000/flexcomm@b4000/spi@b4000' defined in zephyr/dts/arm/nxp/nxp_mcxnx4x_common.dtsi:364 */
				flexcomm4_lpspi4: spi@b4000 {
					compatible = "nxp,lpspi";   /* in zephyr/dts/arm/nxp/nxp_mcxnx4x_common.dtsi:365 */
					reg = < 0xb4000 0x1000 >;   /* in zephyr/dts/arm/nxp/nxp_mcxnx4x_common.dtsi:366 */
					clocks = < &syscon 0x104 >; /* in zephyr/dts/arm/nxp/nxp_mcxnx4x_common.dtsi:367 */
					#address-cells = < 0x1 >;   /* in zephyr/dts/arm/nxp/nxp_mcxnx4x_common.dtsi:368 */
					#size-cells = < 0x0 >;      /* in zephyr/dts/arm/nxp/nxp_mcxnx4x_common.dtsi:369 */
					dmas = < &edma0 0x2 0x4d >,
					       < &edma0 0x3 0x4e >; /* in zephyr/dts/arm/nxp/nxp_mcxnx4x_common.dtsi:371 */
					dma-names = "rx",
					            "tx";           /* in zephyr/dts/arm/nxp/nxp_mcxnx4x_common.dtsi:372 */
					tx-fifo-size = < 0x8 >;     /* in zephyr/dts/arm/nxp/nxp_mcxnx4x_common.dtsi:373 */
					rx-fifo-size = < 0x8 >;     /* in zephyr/dts/arm/nxp/nxp_mcxnx4x_common.dtsi:374 */
					status = "disabled";        /* in zephyr/dts/arm/nxp/nxp_mcxnx4x_common.dtsi:375 */
				};

				/* node '/soc/peripheral@50000000/flexcomm@b4000/lpi2c@b4800' defined in zephyr/dts/arm/nxp/nxp_mcxnx4x_common.dtsi:378 */
				flexcomm4_lpi2c4: lpi2c@b4800 {
					compatible = "nxp,lpi2c";   /* in zephyr/dts/arm/nxp/nxp_mcxnx4x_common.dtsi:379 */
					reg = < 0xb4800 0x1000 >;   /* in zephyr/dts/arm/nxp/nxp_mcxnx4x_common.dtsi:380 */
					clocks = < &syscon 0x104 >; /* in zephyr/dts/arm/nxp/nxp_mcxnx4x_common.dtsi:381 */
					#address-cells = < 0x1 >;   /* in zephyr/dts/arm/nxp/nxp_mcxnx4x_common.dtsi:382 */
					#size-cells = < 0x0 >;      /* in zephyr/dts/arm/nxp/nxp_mcxnx4x_common.dtsi:383 */
					status = "disabled";        /* in zephyr/dts/arm/nxp/nxp_mcxnx4x_common.dtsi:384 */
				};
			};

			/* node '/soc/peripheral@50000000/flexcomm@b5000' defined in zephyr/dts/arm/nxp/nxp_mcxnx4x_common.dtsi:388 */
			flexcomm5: flexcomm@b5000 {
				compatible = "nxp,lp-flexcomm"; /* in zephyr/dts/arm/nxp/nxp_mcxnx4x_common.dtsi:389 */
				reg = < 0xb5000 0x1000 >;       /* in zephyr/dts/arm/nxp/nxp_mcxnx4x_common.dtsi:390 */
				interrupts = < 0x28 0x0 >;      /* in zephyr/dts/arm/nxp/nxp_mcxnx4x_common.dtsi:391 */
				status = "disabled";            /* in zephyr/dts/arm/nxp/nxp_mcxnx4x_common.dtsi:392 */
				ranges;                         /* in zephyr/dts/arm/nxp/nxp_mcxnx4x_common.dtsi:394 */
				#address-cells = < 0x1 >;       /* in zephyr/dts/arm/nxp/nxp_mcxnx4x_common.dtsi:395 */
				#size-cells = < 0x1 >;          /* in zephyr/dts/arm/nxp/nxp_mcxnx4x_common.dtsi:396 */

				/* node '/soc/peripheral@50000000/flexcomm@b5000/lpuart@b5000' defined in zephyr/dts/arm/nxp/nxp_mcxnx4x_common.dtsi:398 */
				flexcomm5_lpuart5: lpuart@b5000 {
					compatible = "nxp,lpuart";  /* in zephyr/dts/arm/nxp/nxp_mcxnx4x_common.dtsi:399 */
					reg = < 0xb5000 0x1000 >;   /* in zephyr/dts/arm/nxp/nxp_mcxnx4x_common.dtsi:400 */
					clocks = < &syscon 0x105 >; /* in zephyr/dts/arm/nxp/nxp_mcxnx4x_common.dtsi:401 */
					status = "disabled";        /* in zephyr/dts/arm/nxp/nxp_mcxnx4x_common.dtsi:402 */
				};

				/* node '/soc/peripheral@50000000/flexcomm@b5000/spi@b5000' defined in zephyr/dts/arm/nxp/nxp_mcxnx4x_common.dtsi:405 */
				flexcomm5_lpspi5: spi@b5000 {
					compatible = "nxp,lpspi";   /* in zephyr/dts/arm/nxp/nxp_mcxnx4x_common.dtsi:406 */
					reg = < 0xb5000 0x1000 >;   /* in zephyr/dts/arm/nxp/nxp_mcxnx4x_common.dtsi:407 */
					clocks = < &syscon 0x105 >; /* in zephyr/dts/arm/nxp/nxp_mcxnx4x_common.dtsi:408 */
					#address-cells = < 0x1 >;   /* in zephyr/dts/arm/nxp/nxp_mcxnx4x_common.dtsi:409 */
					#size-cells = < 0x0 >;      /* in zephyr/dts/arm/nxp/nxp_mcxnx4x_common.dtsi:410 */
					tx-fifo-size = < 0x8 >;     /* in zephyr/dts/arm/nxp/nxp_mcxnx4x_common.dtsi:411 */
					rx-fifo-size = < 0x8 >;     /* in zephyr/dts/arm/nxp/nxp_mcxnx4x_common.dtsi:412 */
					status = "disabled";        /* in zephyr/dts/arm/nxp/nxp_mcxnx4x_common.dtsi:413 */
				};

				/* node '/soc/peripheral@50000000/flexcomm@b5000/lpi2c@b5800' defined in zephyr/dts/arm/nxp/nxp_mcxnx4x_common.dtsi:416 */
				flexcomm5_lpi2c5: lpi2c@b5800 {
					compatible = "nxp,lpi2c";   /* in zephyr/dts/arm/nxp/nxp_mcxnx4x_common.dtsi:417 */
					reg = < 0xb5800 0x1000 >;   /* in zephyr/dts/arm/nxp/nxp_mcxnx4x_common.dtsi:418 */
					clocks = < &syscon 0x105 >; /* in zephyr/dts/arm/nxp/nxp_mcxnx4x_common.dtsi:419 */
					#address-cells = < 0x1 >;   /* in zephyr/dts/arm/nxp/nxp_mcxnx4x_common.dtsi:420 */
					#size-cells = < 0x0 >;      /* in zephyr/dts/arm/nxp/nxp_mcxnx4x_common.dtsi:421 */
					status = "disabled";        /* in zephyr/dts/arm/nxp/nxp_mcxnx4x_common.dtsi:422 */
				};
			};

			/* node '/soc/peripheral@50000000/flexcomm@b6000' defined in zephyr/dts/arm/nxp/nxp_mcxnx4x_common.dtsi:426 */
			flexcomm6: flexcomm@b6000 {
				compatible = "nxp,lp-flexcomm"; /* in zephyr/dts/arm/nxp/nxp_mcxnx4x_common.dtsi:427 */
				reg = < 0xb6000 0x1000 >;       /* in zephyr/dts/arm/nxp/nxp_mcxnx4x_common.dtsi:428 */
				interrupts = < 0x29 0x0 >;      /* in zephyr/dts/arm/nxp/nxp_mcxnx4x_common.dtsi:429 */
				status = "disabled";            /* in zephyr/dts/arm/nxp/nxp_mcxnx4x_common.dtsi:430 */
				ranges;                         /* in zephyr/dts/arm/nxp/nxp_mcxnx4x_common.dtsi:432 */
				#address-cells = < 0x1 >;       /* in zephyr/dts/arm/nxp/nxp_mcxnx4x_common.dtsi:433 */
				#size-cells = < 0x1 >;          /* in zephyr/dts/arm/nxp/nxp_mcxnx4x_common.dtsi:434 */

				/* node '/soc/peripheral@50000000/flexcomm@b6000/lpuart@b6000' defined in zephyr/dts/arm/nxp/nxp_mcxnx4x_common.dtsi:436 */
				flexcomm6_lpuart6: lpuart@b6000 {
					compatible = "nxp,lpuart";  /* in zephyr/dts/arm/nxp/nxp_mcxnx4x_common.dtsi:437 */
					reg = < 0xb6000 0x1000 >;   /* in zephyr/dts/arm/nxp/nxp_mcxnx4x_common.dtsi:438 */
					clocks = < &syscon 0x106 >; /* in zephyr/dts/arm/nxp/nxp_mcxnx4x_common.dtsi:439 */
					status = "disabled";        /* in zephyr/dts/arm/nxp/nxp_mcxnx4x_common.dtsi:440 */
				};

				/* node '/soc/peripheral@50000000/flexcomm@b6000/spi@b6000' defined in zephyr/dts/arm/nxp/nxp_mcxnx4x_common.dtsi:443 */
				flexcomm6_lpspi6: spi@b6000 {
					compatible = "nxp,lpspi";   /* in zephyr/dts/arm/nxp/nxp_mcxnx4x_common.dtsi:444 */
					reg = < 0xb6000 0x1000 >;   /* in zephyr/dts/arm/nxp/nxp_mcxnx4x_common.dtsi:445 */
					clocks = < &syscon 0x106 >; /* in zephyr/dts/arm/nxp/nxp_mcxnx4x_common.dtsi:446 */
					#address-cells = < 0x1 >;   /* in zephyr/dts/arm/nxp/nxp_mcxnx4x_common.dtsi:447 */
					#size-cells = < 0x0 >;      /* in zephyr/dts/arm/nxp/nxp_mcxnx4x_common.dtsi:448 */
					tx-fifo-size = < 0x8 >;     /* in zephyr/dts/arm/nxp/nxp_mcxnx4x_common.dtsi:449 */
					rx-fifo-size = < 0x8 >;     /* in zephyr/dts/arm/nxp/nxp_mcxnx4x_common.dtsi:450 */
					status = "disabled";        /* in zephyr/dts/arm/nxp/nxp_mcxnx4x_common.dtsi:451 */
				};

				/* node '/soc/peripheral@50000000/flexcomm@b6000/lpi2c@b6800' defined in zephyr/dts/arm/nxp/nxp_mcxnx4x_common.dtsi:454 */
				flexcomm6_lpi2c6: lpi2c@b6800 {
					compatible = "nxp,lpi2c";   /* in zephyr/dts/arm/nxp/nxp_mcxnx4x_common.dtsi:455 */
					reg = < 0xb6800 0x1000 >;   /* in zephyr/dts/arm/nxp/nxp_mcxnx4x_common.dtsi:456 */
					clocks = < &syscon 0x106 >; /* in zephyr/dts/arm/nxp/nxp_mcxnx4x_common.dtsi:457 */
					#address-cells = < 0x1 >;   /* in zephyr/dts/arm/nxp/nxp_mcxnx4x_common.dtsi:458 */
					#size-cells = < 0x0 >;      /* in zephyr/dts/arm/nxp/nxp_mcxnx4x_common.dtsi:459 */
					status = "disabled";        /* in zephyr/dts/arm/nxp/nxp_mcxnx4x_common.dtsi:460 */
				};
			};

			/* node '/soc/peripheral@50000000/flexcomm@b7000' defined in zephyr/dts/arm/nxp/nxp_mcxnx4x_common.dtsi:464 */
			flexcomm7: flexcomm@b7000 {
				compatible = "nxp,lp-flexcomm"; /* in zephyr/dts/arm/nxp/nxp_mcxnx4x_common.dtsi:465 */
				reg = < 0xb7000 0x1000 >;       /* in zephyr/dts/arm/nxp/nxp_mcxnx4x_common.dtsi:466 */
				interrupts = < 0x2a 0x0 >;      /* in zephyr/dts/arm/nxp/nxp_mcxnx4x_common.dtsi:467 */
				ranges;                         /* in zephyr/dts/arm/nxp/nxp_mcxnx4x_common.dtsi:470 */
				#address-cells = < 0x1 >;       /* in zephyr/dts/arm/nxp/nxp_mcxnx4x_common.dtsi:471 */
				#size-cells = < 0x1 >;          /* in zephyr/dts/arm/nxp/nxp_mcxnx4x_common.dtsi:472 */
				status = "okay";                /* in zephyr/boards/nxp/frdm_mcxn947/frdm_mcxn947_mcxn947_cpu0.dtsi:124 */

				/* node '/soc/peripheral@50000000/flexcomm@b7000/lpuart@b7000' defined in zephyr/dts/arm/nxp/nxp_mcxnx4x_common.dtsi:474 */
				flexcomm7_lpuart7: lpuart@b7000 {
					compatible = "nxp,lpuart";  /* in zephyr/dts/arm/nxp/nxp_mcxnx4x_common.dtsi:475 */
					reg = < 0xb7000 0x1000 >;   /* in zephyr/dts/arm/nxp/nxp_mcxnx4x_common.dtsi:476 */
					clocks = < &syscon 0x107 >; /* in zephyr/dts/arm/nxp/nxp_mcxnx4x_common.dtsi:477 */
					status = "disabled";        /* in zephyr/dts/arm/nxp/nxp_mcxnx4x_common.dtsi:478 */
				};

				/* node '/soc/peripheral@50000000/flexcomm@b7000/spi@b7000' defined in zephyr/dts/arm/nxp/nxp_mcxnx4x_common.dtsi:481 */
				flexcomm7_lpspi7: spi@b7000 {
					compatible = "nxp,lpspi";   /* in zephyr/dts/arm/nxp/nxp_mcxnx4x_common.dtsi:482 */
					reg = < 0xb7000 0x1000 >;   /* in zephyr/dts/arm/nxp/nxp_mcxnx4x_common.dtsi:483 */
					clocks = < &syscon 0x107 >; /* in zephyr/dts/arm/nxp/nxp_mcxnx4x_common.dtsi:484 */
					#address-cells = < 0x1 >;   /* in zephyr/dts/arm/nxp/nxp_mcxnx4x_common.dtsi:485 */
					#size-cells = < 0x0 >;      /* in zephyr/dts/arm/nxp/nxp_mcxnx4x_common.dtsi:486 */
					tx-fifo-size = < 0x8 >;     /* in zephyr/dts/arm/nxp/nxp_mcxnx4x_common.dtsi:487 */
					rx-fifo-size = < 0x8 >;     /* in zephyr/dts/arm/nxp/nxp_mcxnx4x_common.dtsi:488 */
					status = "disabled";        /* in zephyr/dts/arm/nxp/nxp_mcxnx4x_common.dtsi:489 */
				};

				/* node '/soc/peripheral@50000000/flexcomm@b7000/lpi2c@b7800' defined in zephyr/dts/arm/nxp/nxp_mcxnx4x_common.dtsi:492 */
				flexcomm7_lpi2c7: dvp_20pin_i2c: lpi2c@b7800 {
					compatible = "nxp,lpi2c";                /* in zephyr/dts/arm/nxp/nxp_mcxnx4x_common.dtsi:493 */
					reg = < 0xb7800 0x1000 >;                /* in zephyr/dts/arm/nxp/nxp_mcxnx4x_common.dtsi:494 */
					clocks = < &syscon 0x107 >;              /* in zephyr/dts/arm/nxp/nxp_mcxnx4x_common.dtsi:495 */
					#address-cells = < 0x1 >;                /* in zephyr/dts/arm/nxp/nxp_mcxnx4x_common.dtsi:496 */
					#size-cells = < 0x0 >;                   /* in zephyr/dts/arm/nxp/nxp_mcxnx4x_common.dtsi:497 */
					pinctrl-0 = < &pinmux_flexcomm7_lpi2c >; /* in zephyr/boards/nxp/frdm_mcxn947/frdm_mcxn947.dtsi:96 */
					pinctrl-names = "default";               /* in zephyr/boards/nxp/frdm_mcxn947/frdm_mcxn947.dtsi:97 */
					clock-frequency = < 0x186a0 >;           /* in zephyr/boards/nxp/frdm_mcxn947/frdm_mcxn947.dtsi:98 */
					status = "okay";                         /* in zephyr/boards/nxp/frdm_mcxn947/frdm_mcxn947_mcxn947_cpu0.dtsi:128 */
				};
			};

			/* node '/soc/peripheral@50000000/flexcomm@b8000' defined in zephyr/dts/arm/nxp/nxp_mcxnx4x_common.dtsi:502 */
			flexcomm8: flexcomm@b8000 {
				compatible = "nxp,lp-flexcomm"; /* in zephyr/dts/arm/nxp/nxp_mcxnx4x_common.dtsi:503 */
				reg = < 0xb8000 0x1000 >;       /* in zephyr/dts/arm/nxp/nxp_mcxnx4x_common.dtsi:504 */
				interrupts = < 0x2b 0x0 >;      /* in zephyr/dts/arm/nxp/nxp_mcxnx4x_common.dtsi:505 */
				status = "disabled";            /* in zephyr/dts/arm/nxp/nxp_mcxnx4x_common.dtsi:506 */
				ranges;                         /* in zephyr/dts/arm/nxp/nxp_mcxnx4x_common.dtsi:508 */
				#address-cells = < 0x1 >;       /* in zephyr/dts/arm/nxp/nxp_mcxnx4x_common.dtsi:509 */
				#size-cells = < 0x1 >;          /* in zephyr/dts/arm/nxp/nxp_mcxnx4x_common.dtsi:510 */

				/* node '/soc/peripheral@50000000/flexcomm@b8000/lpuart@b8000' defined in zephyr/dts/arm/nxp/nxp_mcxnx4x_common.dtsi:512 */
				flexcomm8_lpuart8: lpuart@b8000 {
					compatible = "nxp,lpuart";  /* in zephyr/dts/arm/nxp/nxp_mcxnx4x_common.dtsi:513 */
					reg = < 0xb8000 0x1000 >;   /* in zephyr/dts/arm/nxp/nxp_mcxnx4x_common.dtsi:514 */
					clocks = < &syscon 0x108 >; /* in zephyr/dts/arm/nxp/nxp_mcxnx4x_common.dtsi:515 */
					status = "disabled";        /* in zephyr/dts/arm/nxp/nxp_mcxnx4x_common.dtsi:516 */
				};

				/* node '/soc/peripheral@50000000/flexcomm@b8000/spi@b8000' defined in zephyr/dts/arm/nxp/nxp_mcxnx4x_common.dtsi:519 */
				flexcomm8_lpspi8: spi@b8000 {
					compatible = "nxp,lpspi";   /* in zephyr/dts/arm/nxp/nxp_mcxnx4x_common.dtsi:520 */
					reg = < 0xb8000 0x1000 >;   /* in zephyr/dts/arm/nxp/nxp_mcxnx4x_common.dtsi:521 */
					clocks = < &syscon 0x108 >; /* in zephyr/dts/arm/nxp/nxp_mcxnx4x_common.dtsi:522 */
					#address-cells = < 0x1 >;   /* in zephyr/dts/arm/nxp/nxp_mcxnx4x_common.dtsi:523 */
					#size-cells = < 0x0 >;      /* in zephyr/dts/arm/nxp/nxp_mcxnx4x_common.dtsi:524 */
					tx-fifo-size = < 0x8 >;     /* in zephyr/dts/arm/nxp/nxp_mcxnx4x_common.dtsi:525 */
					rx-fifo-size = < 0x8 >;     /* in zephyr/dts/arm/nxp/nxp_mcxnx4x_common.dtsi:526 */
					status = "disabled";        /* in zephyr/dts/arm/nxp/nxp_mcxnx4x_common.dtsi:527 */
				};

				/* node '/soc/peripheral@50000000/flexcomm@b8000/lpi2c@b8800' defined in zephyr/dts/arm/nxp/nxp_mcxnx4x_common.dtsi:530 */
				flexcomm8_lpi2c8: lpi2c@b8800 {
					compatible = "nxp,lpi2c";   /* in zephyr/dts/arm/nxp/nxp_mcxnx4x_common.dtsi:531 */
					reg = < 0xb8800 0x1000 >;   /* in zephyr/dts/arm/nxp/nxp_mcxnx4x_common.dtsi:532 */
					clocks = < &syscon 0x108 >; /* in zephyr/dts/arm/nxp/nxp_mcxnx4x_common.dtsi:533 */
					#address-cells = < 0x1 >;   /* in zephyr/dts/arm/nxp/nxp_mcxnx4x_common.dtsi:534 */
					#size-cells = < 0x0 >;      /* in zephyr/dts/arm/nxp/nxp_mcxnx4x_common.dtsi:535 */
					status = "disabled";        /* in zephyr/dts/arm/nxp/nxp_mcxnx4x_common.dtsi:536 */
				};
			};

			/* node '/soc/peripheral@50000000/flexcomm@b9000' defined in zephyr/dts/arm/nxp/nxp_mcxnx4x_common.dtsi:540 */
			flexcomm9: flexcomm@b9000 {
				compatible = "nxp,lp-flexcomm"; /* in zephyr/dts/arm/nxp/nxp_mcxnx4x_common.dtsi:541 */
				reg = < 0xb9000 0x1000 >;       /* in zephyr/dts/arm/nxp/nxp_mcxnx4x_common.dtsi:542 */
				interrupts = < 0x2c 0x0 >;      /* in zephyr/dts/arm/nxp/nxp_mcxnx4x_common.dtsi:543 */
				status = "disabled";            /* in zephyr/dts/arm/nxp/nxp_mcxnx4x_common.dtsi:544 */
				ranges;                         /* in zephyr/dts/arm/nxp/nxp_mcxnx4x_common.dtsi:546 */
				#address-cells = < 0x1 >;       /* in zephyr/dts/arm/nxp/nxp_mcxnx4x_common.dtsi:547 */
				#size-cells = < 0x1 >;          /* in zephyr/dts/arm/nxp/nxp_mcxnx4x_common.dtsi:548 */

				/* node '/soc/peripheral@50000000/flexcomm@b9000/lpuart@b9000' defined in zephyr/dts/arm/nxp/nxp_mcxnx4x_common.dtsi:550 */
				flexcomm9_lpuart9: lpuart@b9000 {
					compatible = "nxp,lpuart";  /* in zephyr/dts/arm/nxp/nxp_mcxnx4x_common.dtsi:551 */
					reg = < 0xb9000 0x1000 >;   /* in zephyr/dts/arm/nxp/nxp_mcxnx4x_common.dtsi:552 */
					clocks = < &syscon 0x109 >; /* in zephyr/dts/arm/nxp/nxp_mcxnx4x_common.dtsi:553 */
					status = "disabled";        /* in zephyr/dts/arm/nxp/nxp_mcxnx4x_common.dtsi:554 */
				};

				/* node '/soc/peripheral@50000000/flexcomm@b9000/spi@b9000' defined in zephyr/dts/arm/nxp/nxp_mcxnx4x_common.dtsi:557 */
				flexcomm9_lpspi9: spi@b9000 {
					compatible = "nxp,lpspi";   /* in zephyr/dts/arm/nxp/nxp_mcxnx4x_common.dtsi:558 */
					reg = < 0xb9000 0x1000 >;   /* in zephyr/dts/arm/nxp/nxp_mcxnx4x_common.dtsi:559 */
					clocks = < &syscon 0x109 >; /* in zephyr/dts/arm/nxp/nxp_mcxnx4x_common.dtsi:560 */
					#address-cells = < 0x1 >;   /* in zephyr/dts/arm/nxp/nxp_mcxnx4x_common.dtsi:561 */
					#size-cells = < 0x0 >;      /* in zephyr/dts/arm/nxp/nxp_mcxnx4x_common.dtsi:562 */
					tx-fifo-size = < 0x8 >;     /* in zephyr/dts/arm/nxp/nxp_mcxnx4x_common.dtsi:563 */
					rx-fifo-size = < 0x8 >;     /* in zephyr/dts/arm/nxp/nxp_mcxnx4x_common.dtsi:564 */
					status = "disabled";        /* in zephyr/dts/arm/nxp/nxp_mcxnx4x_common.dtsi:565 */
				};

				/* node '/soc/peripheral@50000000/flexcomm@b9000/lpi2c@b9800' defined in zephyr/dts/arm/nxp/nxp_mcxnx4x_common.dtsi:568 */
				flexcomm9_lpi2c9: lpi2c@b9800 {
					compatible = "nxp,lpi2c";   /* in zephyr/dts/arm/nxp/nxp_mcxnx4x_common.dtsi:569 */
					reg = < 0xb9800 0x1000 >;   /* in zephyr/dts/arm/nxp/nxp_mcxnx4x_common.dtsi:570 */
					clocks = < &syscon 0x109 >; /* in zephyr/dts/arm/nxp/nxp_mcxnx4x_common.dtsi:571 */
					#address-cells = < 0x1 >;   /* in zephyr/dts/arm/nxp/nxp_mcxnx4x_common.dtsi:572 */
					#size-cells = < 0x0 >;      /* in zephyr/dts/arm/nxp/nxp_mcxnx4x_common.dtsi:573 */
					status = "disabled";        /* in zephyr/dts/arm/nxp/nxp_mcxnx4x_common.dtsi:574 */
				};
			};

			/* node '/soc/peripheral@50000000/mbox@b2000' defined in zephyr/dts/arm/nxp/nxp_mcxnx4x_common.dtsi:578 */
			mbox: mbox@b2000 {
				compatible = "nxp,mbox-mailbox"; /* in zephyr/dts/arm/nxp/nxp_mcxnx4x_common.dtsi:579 */
				reg = < 0xb2000 0xec >;          /* in zephyr/dts/arm/nxp/nxp_mcxnx4x_common.dtsi:580 */
				interrupts = < 0x36 0x0 >;       /* in zephyr/dts/arm/nxp/nxp_mcxnx4x_common.dtsi:581 */
				rx-channels = < 0x4 >;           /* in zephyr/dts/arm/nxp/nxp_mcxnx4x_common.dtsi:582 */
				#mbox-cells = < 0x1 >;           /* in zephyr/dts/arm/nxp/nxp_mcxnx4x_common.dtsi:583 */
				status = "okay";                 /* in zephyr/boards/nxp/frdm_mcxn947/frdm_mcxn947_mcxn947_cpu0.dtsi:56 */
			};

			/* node '/soc/peripheral@50000000/dma-controller@80000' defined in zephyr/dts/arm/nxp/nxp_mcxnx4x_common.dtsi:587 */
			edma0: dma-controller@80000 {
				#dma-cells = < 0x2 >;         /* in zephyr/dts/arm/nxp/nxp_mcxnx4x_common.dtsi:588 */
				compatible = "nxp,mcux-edma"; /* in zephyr/dts/arm/nxp/nxp_mcxnx4x_common.dtsi:589 */
				nxp,version = < 0x4 >;        /* in zephyr/dts/arm/nxp/nxp_mcxnx4x_common.dtsi:590 */
				dma-channels = < 0x10 >;      /* in zephyr/dts/arm/nxp/nxp_mcxnx4x_common.dtsi:591 */
				dma-requests = < 0x78 >;      /* in zephyr/dts/arm/nxp/nxp_mcxnx4x_common.dtsi:592 */
				reg = < 0x80000 0x1000 >;     /* in zephyr/dts/arm/nxp/nxp_mcxnx4x_common.dtsi:594 */
				interrupts = < 0x1 0x0 >,
				             < 0x2 0x0 >,
				             < 0x3 0x0 >,
				             < 0x4 0x0 >,
				             < 0x5 0x0 >,
				             < 0x6 0x0 >,
				             < 0x7 0x0 >,
				             < 0x8 0x0 >,
				             < 0x9 0x0 >,
				             < 0xa 0x0 >,
				             < 0xb 0x0 >,
				             < 0xc 0x0 >,
				             < 0xd 0x0 >,
				             < 0xe 0x0 >,
				             < 0xf 0x0 >,
				             < 0x10 0x0 >;    /* in zephyr/dts/arm/nxp/nxp_mcxnx4x_common.dtsi:595 */
				no-error-irq;                 /* in zephyr/dts/arm/nxp/nxp_mcxnx4x_common.dtsi:599 */
				status = "okay";              /* in zephyr/boards/nxp/frdm_mcxn947/frdm_mcxn947_mcxn947_cpu0.dtsi:88 */
				phandle = < 0x9 >;            /* in zephyr/dts/arm/nxp/nxp_mcxnx4x_common.dtsi:233 */
			};

			/* node '/soc/peripheral@50000000/dma-controller@a0000' defined in zephyr/dts/arm/nxp/nxp_mcxnx4x_common.dtsi:603 */
			edma1: dma-controller@a0000 {
				#dma-cells = < 0x2 >;         /* in zephyr/dts/arm/nxp/nxp_mcxnx4x_common.dtsi:604 */
				compatible = "nxp,mcux-edma"; /* in zephyr/dts/arm/nxp/nxp_mcxnx4x_common.dtsi:605 */
				nxp,version = < 0x4 >;        /* in zephyr/dts/arm/nxp/nxp_mcxnx4x_common.dtsi:606 */
				dma-channels = < 0x10 >;      /* in zephyr/dts/arm/nxp/nxp_mcxnx4x_common.dtsi:607 */
				dma-requests = < 0x78 >;      /* in zephyr/dts/arm/nxp/nxp_mcxnx4x_common.dtsi:608 */
				reg = < 0xa0000 0x1000 >;     /* in zephyr/dts/arm/nxp/nxp_mcxnx4x_common.dtsi:610 */
				interrupts = < 0x4d 0x0 >,
				             < 0x4e 0x0 >,
				             < 0x4f 0x0 >,
				             < 0x50 0x0 >,
				             < 0x51 0x0 >,
				             < 0x52 0x0 >,
				             < 0x53 0x0 >,
				             < 0x54 0x0 >,
				             < 0x55 0x0 >,
				             < 0x56 0x0 >,
				             < 0x57 0x0 >,
				             < 0x58 0x0 >,
				             < 0x59 0x0 >,
				             < 0x5a 0x0 >,
				             < 0x5b 0x0 >,
				             < 0x5c 0x0 >;    /* in zephyr/dts/arm/nxp/nxp_mcxnx4x_common.dtsi:611 */
				no-error-irq;                 /* in zephyr/dts/arm/nxp/nxp_mcxnx4x_common.dtsi:615 */
				status = "disabled";          /* in zephyr/dts/arm/nxp/nxp_mcxnx4x_common.dtsi:616 */
			};

			/* node '/soc/peripheral@50000000/timers@49000' defined in zephyr/dts/arm/nxp/nxp_mcxnx4x_common.dtsi:641 */
			os_timer: timers@49000 {
				compatible = "nxp,os-timer"; /* in zephyr/dts/arm/nxp/nxp_mcxnx4x_common.dtsi:642 */
				reg = < 0x49000 0x1000 >;    /* in zephyr/dts/arm/nxp/nxp_mcxnx4x_common.dtsi:643 */
				interrupts = < 0x39 0x0 >;   /* in zephyr/dts/arm/nxp/nxp_mcxnx4x_common.dtsi:644 */
				status = "disabled";         /* in zephyr/boards/nxp/frdm_mcxn947/frdm_mcxn947.dtsi:124 */
			};

			/* node '/soc/peripheral@50000000/dac@10f000' defined in zephyr/dts/arm/nxp/nxp_mcxnx4x_common.dtsi:648 */
			dac0: dac@10f000 {
				compatible = "nxp,lpdac";     /* in zephyr/dts/arm/nxp/nxp_mcxnx4x_common.dtsi:649 */
				reg = < 0x10f000 0x1000 >;    /* in zephyr/dts/arm/nxp/nxp_mcxnx4x_common.dtsi:650 */
				interrupts = < 0x6a 0x0 >;    /* in zephyr/dts/arm/nxp/nxp_mcxnx4x_common.dtsi:651 */
				voltage-reference = < 0x0 >;  /* in zephyr/dts/arm/nxp/nxp_mcxnx4x_common.dtsi:653 */
				#io-channel-cells = < 0x1 >;  /* in zephyr/dts/arm/nxp/nxp_mcxnx4x_common.dtsi:654 */
				pinctrl-0 = < &pinmux_dac0 >; /* in zephyr/boards/nxp/frdm_mcxn947/frdm_mcxn947.dtsi:198 */
				pinctrl-names = "default";    /* in zephyr/boards/nxp/frdm_mcxn947/frdm_mcxn947.dtsi:199 */
				status = "okay";              /* in zephyr/boards/nxp/frdm_mcxn947/frdm_mcxn947_mcxn947_cpu0.dtsi:149 */
			};

			/* node '/soc/peripheral@50000000/ethernet@40100000' defined in zephyr/dts/arm/nxp/nxp_mcxnx4x_common.dtsi:657 */
			enet: ethernet@40100000 {
				compatible = "nxp,enet-qos";      /* in zephyr/dts/arm/nxp/nxp_mcxnx4x_common.dtsi:658 */
				reg = < 0x40100000 0x1200 >;      /* in zephyr/dts/arm/nxp/nxp_mcxnx4x_common.dtsi:659 */
				clocks = < &syscon 0xd00 >;       /* in zephyr/dts/arm/nxp/nxp_mcxnx4x_common.dtsi:660 */
				pinctrl-0 = < &pinmux_enet_qos >; /* in zephyr/boards/nxp/frdm_mcxn947/frdm_mcxn947.dtsi:213 */
				pinctrl-names = "default";        /* in zephyr/boards/nxp/frdm_mcxn947/frdm_mcxn947.dtsi:214 */
				status = "okay";                  /* in zephyr/boards/nxp/frdm_mcxn947/frdm_mcxn947_mcxn947_cpu0.dtsi:153 */

				/* node '/soc/peripheral@50000000/ethernet@40100000/ethernet' defined in zephyr/dts/arm/nxp/nxp_mcxnx4x_common.dtsi:661 */
				enet_mac: ethernet {
					compatible = "nxp,enet-qos-mac"; /* in zephyr/dts/arm/nxp/nxp_mcxnx4x_common.dtsi:662 */
					interrupts = < 0x8b 0x0 >,
					             < 0x8c 0x0 >,
					             < 0x8d 0x0 >;       /* in zephyr/dts/arm/nxp/nxp_mcxnx4x_common.dtsi:664 */
					interrupt-names = "mac",
					                  "power",
					                  "lpi";         /* in zephyr/dts/arm/nxp/nxp_mcxnx4x_common.dtsi:665 */
					phy-connection-type = "rmii";    /* in zephyr/boards/nxp/frdm_mcxn947/frdm_mcxn947.dtsi:218 */
					zephyr,random-mac-address;       /* in zephyr/boards/nxp/frdm_mcxn947/frdm_mcxn947.dtsi:219 */
					phy-handle = < &phy >;           /* in zephyr/boards/nxp/frdm_mcxn947/frdm_mcxn947.dtsi:220 */
					status = "okay";                 /* in zephyr/boards/nxp/frdm_mcxn947/frdm_mcxn947_mcxn947_cpu0.dtsi:157 */
				};

				/* node '/soc/peripheral@50000000/ethernet@40100000/mdio' defined in zephyr/dts/arm/nxp/nxp_mcxnx4x_common.dtsi:668 */
				enet_mdio: mdio {
					#address-cells = < 0x1 >;         /* in zephyr/dts/arm/nxp/nxp_mcxnx4x_common.dtsi:669 */
					#size-cells = < 0x0 >;            /* in zephyr/dts/arm/nxp/nxp_mcxnx4x_common.dtsi:670 */
					compatible = "nxp,enet-qos-mdio"; /* in zephyr/dts/arm/nxp/nxp_mcxnx4x_common.dtsi:671 */
					status = "okay";                  /* in zephyr/boards/nxp/frdm_mcxn947/frdm_mcxn947_mcxn947_cpu0.dtsi:161 */

					/* node '/soc/peripheral@50000000/ethernet@40100000/mdio/ethernet-phy@0' defined in zephyr/boards/nxp/frdm_mcxn947/frdm_mcxn947.dtsi:224 */
					phy: ethernet-phy@0 {
						compatible = "ethernet-phy"; /* in zephyr/boards/nxp/frdm_mcxn947/frdm_mcxn947.dtsi:225 */
						reg = < 0x0 >;               /* in zephyr/boards/nxp/frdm_mcxn947/frdm_mcxn947.dtsi:226 */
						status = "okay";             /* in zephyr/boards/nxp/frdm_mcxn947/frdm_mcxn947.dtsi:227 */
						phandle = < 0x11 >;          /* in zephyr/boards/nxp/frdm_mcxn947/frdm_mcxn947.dtsi:220 */
					};
				};
			};

			/* node '/soc/peripheral@50000000/watchdog@16000' defined in zephyr/dts/arm/nxp/nxp_mcxnx4x_common.dtsi:676 */
			wwdt0: watchdog@16000 {
				compatible = "nxp,lpc-wwdt"; /* in zephyr/dts/arm/nxp/nxp_mcxnx4x_common.dtsi:677 */
				reg = < 0x16000 0x1000 >;    /* in zephyr/dts/arm/nxp/nxp_mcxnx4x_common.dtsi:678 */
				interrupts = < 0x98 0x0 >;   /* in zephyr/dts/arm/nxp/nxp_mcxnx4x_common.dtsi:679 */
				clk-divider = < 0x1 >;       /* in zephyr/dts/arm/nxp/nxp_mcxnx4x_common.dtsi:681 */
				status = "okay";             /* in zephyr/boards/nxp/frdm_mcxn947/frdm_mcxn947_mcxn947_cpu0.dtsi:165 */
			};

			/* node '/soc/peripheral@50000000/flexpwm@ce000' defined in zephyr/dts/arm/nxp/nxp_mcxnx4x_common.dtsi:684 */
			flexpwm0: flexpwm@ce000 {
				compatible = "nxp,flexpwm";       /* in zephyr/dts/arm/nxp/nxp_mcxnx4x_common.dtsi:685 */
				reg = < 0xce000 0x1000 >;         /* in zephyr/dts/arm/nxp/nxp_mcxnx4x_common.dtsi:686 */
				interrupt-names = "RELOAD-ERROR",
				                  "FAULT";        /* in zephyr/dts/arm/nxp/nxp_mcxnx4x_common.dtsi:687 */
				interrupts = < 0x70 0x0 >,
				             < 0x71 0x0 >;        /* in zephyr/dts/arm/nxp/nxp_mcxnx4x_common.dtsi:688 */

				/* node '/soc/peripheral@50000000/flexpwm@ce000/pwm0' defined in zephyr/dts/arm/nxp/nxp_mcxnx4x_common.dtsi:689 */
				flexpwm0_pwm0: pwm0 {
					compatible = "nxp,imx-pwm"; /* in zephyr/dts/arm/nxp/nxp_mcxnx4x_common.dtsi:690 */
					index = < 0x0 >;            /* in zephyr/dts/arm/nxp/nxp_mcxnx4x_common.dtsi:691 */
					interrupts = < 0x72 0x0 >;  /* in zephyr/dts/arm/nxp/nxp_mcxnx4x_common.dtsi:692 */
					#pwm-cells = < 0x3 >;       /* in zephyr/dts/arm/nxp/nxp_mcxnx4x_common.dtsi:693 */
					clocks = < &syscon 0x400 >; /* in zephyr/dts/arm/nxp/nxp_mcxnx4x_common.dtsi:694 */
					nxp,prescaler = < 0x80 >;   /* in zephyr/dts/arm/nxp/nxp_mcxnx4x_common.dtsi:695 */
					status = "disabled";        /* in zephyr/dts/arm/nxp/nxp_mcxnx4x_common.dtsi:696 */
					run-in-wait;                /* in zephyr/dts/arm/nxp/nxp_mcxnx4x_common.dtsi:697 */
				};

				/* node '/soc/peripheral@50000000/flexpwm@ce000/pwm1' defined in zephyr/dts/arm/nxp/nxp_mcxnx4x_common.dtsi:700 */
				flexpwm0_pwm1: pwm1 {
					compatible = "nxp,imx-pwm"; /* in zephyr/dts/arm/nxp/nxp_mcxnx4x_common.dtsi:701 */
					index = < 0x1 >;            /* in zephyr/dts/arm/nxp/nxp_mcxnx4x_common.dtsi:702 */
					interrupts = < 0x73 0x0 >;  /* in zephyr/dts/arm/nxp/nxp_mcxnx4x_common.dtsi:703 */
					#pwm-cells = < 0x3 >;       /* in zephyr/dts/arm/nxp/nxp_mcxnx4x_common.dtsi:704 */
					clocks = < &syscon 0x400 >; /* in zephyr/dts/arm/nxp/nxp_mcxnx4x_common.dtsi:705 */
					nxp,prescaler = < 0x80 >;   /* in zephyr/dts/arm/nxp/nxp_mcxnx4x_common.dtsi:706 */
					status = "disabled";        /* in zephyr/dts/arm/nxp/nxp_mcxnx4x_common.dtsi:707 */
					run-in-wait;                /* in zephyr/dts/arm/nxp/nxp_mcxnx4x_common.dtsi:708 */
				};

				/* node '/soc/peripheral@50000000/flexpwm@ce000/pwm2' defined in zephyr/dts/arm/nxp/nxp_mcxnx4x_common.dtsi:711 */
				flexpwm0_pwm2: pwm2 {
					compatible = "nxp,imx-pwm"; /* in zephyr/dts/arm/nxp/nxp_mcxnx4x_common.dtsi:712 */
					index = < 0x2 >;            /* in zephyr/dts/arm/nxp/nxp_mcxnx4x_common.dtsi:713 */
					interrupts = < 0x74 0x0 >;  /* in zephyr/dts/arm/nxp/nxp_mcxnx4x_common.dtsi:714 */
					#pwm-cells = < 0x3 >;       /* in zephyr/dts/arm/nxp/nxp_mcxnx4x_common.dtsi:715 */
					clocks = < &syscon 0x400 >; /* in zephyr/dts/arm/nxp/nxp_mcxnx4x_common.dtsi:716 */
					nxp,prescaler = < 0x80 >;   /* in zephyr/dts/arm/nxp/nxp_mcxnx4x_common.dtsi:717 */
					status = "disabled";        /* in zephyr/dts/arm/nxp/nxp_mcxnx4x_common.dtsi:718 */
					run-in-wait;                /* in zephyr/dts/arm/nxp/nxp_mcxnx4x_common.dtsi:719 */
				};

				/* node '/soc/peripheral@50000000/flexpwm@ce000/pwm3' defined in zephyr/dts/arm/nxp/nxp_mcxnx4x_common.dtsi:722 */
				flexpwm0_pwm3: pwm3 {
					compatible = "nxp,imx-pwm"; /* in zephyr/dts/arm/nxp/nxp_mcxnx4x_common.dtsi:723 */
					index = < 0x3 >;            /* in zephyr/dts/arm/nxp/nxp_mcxnx4x_common.dtsi:724 */
					interrupts = < 0x75 0x0 >;  /* in zephyr/dts/arm/nxp/nxp_mcxnx4x_common.dtsi:725 */
					#pwm-cells = < 0x3 >;       /* in zephyr/dts/arm/nxp/nxp_mcxnx4x_common.dtsi:726 */
					clocks = < &syscon 0x400 >; /* in zephyr/dts/arm/nxp/nxp_mcxnx4x_common.dtsi:727 */
					nxp,prescaler = < 0x80 >;   /* in zephyr/dts/arm/nxp/nxp_mcxnx4x_common.dtsi:728 */
					status = "disabled";        /* in zephyr/dts/arm/nxp/nxp_mcxnx4x_common.dtsi:729 */
					run-in-wait;                /* in zephyr/dts/arm/nxp/nxp_mcxnx4x_common.dtsi:730 */
				};
			};

			/* node '/soc/peripheral@50000000/ctimer@c000' defined in zephyr/dts/arm/nxp/nxp_mcxnx4x_common.dtsi:734 */
			ctimer0: ctimer@c000 {
				compatible = "nxp,lpc-ctimer"; /* in zephyr/dts/arm/nxp/nxp_mcxnx4x_common.dtsi:735 */
				reg = < 0xc000 0x1000 >;       /* in zephyr/dts/arm/nxp/nxp_mcxnx4x_common.dtsi:736 */
				interrupts = < 0x1f 0x0 >;     /* in zephyr/dts/arm/nxp/nxp_mcxnx4x_common.dtsi:737 */
				clk-source = < 0x1 >;          /* in zephyr/dts/arm/nxp/nxp_mcxnx4x_common.dtsi:739 */
				clocks = < &syscon 0x0 >;      /* in zephyr/dts/arm/nxp/nxp_mcxnx4x_common.dtsi:740 */
				mode = < 0x0 >;                /* in zephyr/dts/arm/nxp/nxp_mcxnx4x_common.dtsi:741 */
				input = < 0x0 >;               /* in zephyr/dts/arm/nxp/nxp_mcxnx4x_common.dtsi:742 */
				prescale = < 0x0 >;            /* in zephyr/dts/arm/nxp/nxp_mcxnx4x_common.dtsi:743 */
				status = "okay";               /* in zephyr/boards/nxp/frdm_mcxn947/frdm_mcxn947_mcxn947_cpu0.dtsi:177 */
			};

			/* node '/soc/peripheral@50000000/ctimer@d000' defined in zephyr/dts/arm/nxp/nxp_mcxnx4x_common.dtsi:746 */
			ctimer1: ctimer@d000 {
				compatible = "nxp,lpc-ctimer"; /* in zephyr/dts/arm/nxp/nxp_mcxnx4x_common.dtsi:747 */
				reg = < 0xd000 0x1000 >;       /* in zephyr/dts/arm/nxp/nxp_mcxnx4x_common.dtsi:748 */
				interrupts = < 0x20 0x0 >;     /* in zephyr/dts/arm/nxp/nxp_mcxnx4x_common.dtsi:749 */
				status = "disabled";           /* in zephyr/dts/arm/nxp/nxp_mcxnx4x_common.dtsi:750 */
				clk-source = < 0x1 >;          /* in zephyr/dts/arm/nxp/nxp_mcxnx4x_common.dtsi:751 */
				clocks = < &syscon 0x1 >;      /* in zephyr/dts/arm/nxp/nxp_mcxnx4x_common.dtsi:752 */
				mode = < 0x0 >;                /* in zephyr/dts/arm/nxp/nxp_mcxnx4x_common.dtsi:753 */
				input = < 0x0 >;               /* in zephyr/dts/arm/nxp/nxp_mcxnx4x_common.dtsi:754 */
				prescale = < 0x0 >;            /* in zephyr/dts/arm/nxp/nxp_mcxnx4x_common.dtsi:755 */
			};

			/* node '/soc/peripheral@50000000/ctimer@e000' defined in zephyr/dts/arm/nxp/nxp_mcxnx4x_common.dtsi:758 */
			ctimer2: ctimer@e000 {
				compatible = "nxp,lpc-ctimer"; /* in zephyr/dts/arm/nxp/nxp_mcxnx4x_common.dtsi:759 */
				reg = < 0xe000 0x1000 >;       /* in zephyr/dts/arm/nxp/nxp_mcxnx4x_common.dtsi:760 */
				interrupts = < 0x22 0x0 >;     /* in zephyr/dts/arm/nxp/nxp_mcxnx4x_common.dtsi:761 */
				status = "disabled";           /* in zephyr/dts/arm/nxp/nxp_mcxnx4x_common.dtsi:762 */
				clk-source = < 0x1 >;          /* in zephyr/dts/arm/nxp/nxp_mcxnx4x_common.dtsi:763 */
				clocks = < &syscon 0x2 >;      /* in zephyr/dts/arm/nxp/nxp_mcxnx4x_common.dtsi:764 */
				mode = < 0x0 >;                /* in zephyr/dts/arm/nxp/nxp_mcxnx4x_common.dtsi:765 */
				input = < 0x0 >;               /* in zephyr/dts/arm/nxp/nxp_mcxnx4x_common.dtsi:766 */
				prescale = < 0x0 >;            /* in zephyr/dts/arm/nxp/nxp_mcxnx4x_common.dtsi:767 */
			};

			/* node '/soc/peripheral@50000000/ctimer@f000' defined in zephyr/dts/arm/nxp/nxp_mcxnx4x_common.dtsi:770 */
			ctimer3: ctimer@f000 {
				compatible = "nxp,lpc-ctimer"; /* in zephyr/dts/arm/nxp/nxp_mcxnx4x_common.dtsi:771 */
				reg = < 0xf000 0x1000 >;       /* in zephyr/dts/arm/nxp/nxp_mcxnx4x_common.dtsi:772 */
				interrupts = < 0x37 0x0 >;     /* in zephyr/dts/arm/nxp/nxp_mcxnx4x_common.dtsi:773 */
				status = "disabled";           /* in zephyr/dts/arm/nxp/nxp_mcxnx4x_common.dtsi:774 */
				clk-source = < 0x1 >;          /* in zephyr/dts/arm/nxp/nxp_mcxnx4x_common.dtsi:775 */
				clocks = < &syscon 0x3 >;      /* in zephyr/dts/arm/nxp/nxp_mcxnx4x_common.dtsi:776 */
				mode = < 0x0 >;                /* in zephyr/dts/arm/nxp/nxp_mcxnx4x_common.dtsi:777 */
				input = < 0x0 >;               /* in zephyr/dts/arm/nxp/nxp_mcxnx4x_common.dtsi:778 */
				prescale = < 0x0 >;            /* in zephyr/dts/arm/nxp/nxp_mcxnx4x_common.dtsi:779 */
			};

			/* node '/soc/peripheral@50000000/ctimer@10000' defined in zephyr/dts/arm/nxp/nxp_mcxnx4x_common.dtsi:782 */
			ctimer4: ctimer@10000 {
				compatible = "nxp,lpc-ctimer"; /* in zephyr/dts/arm/nxp/nxp_mcxnx4x_common.dtsi:783 */
				reg = < 0x10000 0x1000 >;      /* in zephyr/dts/arm/nxp/nxp_mcxnx4x_common.dtsi:784 */
				interrupts = < 0x38 0x0 >;     /* in zephyr/dts/arm/nxp/nxp_mcxnx4x_common.dtsi:785 */
				status = "disabled";           /* in zephyr/dts/arm/nxp/nxp_mcxnx4x_common.dtsi:786 */
				clk-source = < 0x1 >;          /* in zephyr/dts/arm/nxp/nxp_mcxnx4x_common.dtsi:787 */
				clocks = < &syscon 0x4 >;      /* in zephyr/dts/arm/nxp/nxp_mcxnx4x_common.dtsi:788 */
				mode = < 0x0 >;                /* in zephyr/dts/arm/nxp/nxp_mcxnx4x_common.dtsi:789 */
				input = < 0x0 >;               /* in zephyr/dts/arm/nxp/nxp_mcxnx4x_common.dtsi:790 */
				prescale = < 0x0 >;            /* in zephyr/dts/arm/nxp/nxp_mcxnx4x_common.dtsi:791 */
			};

			/* node '/soc/peripheral@50000000/pwm@91000' defined in zephyr/dts/arm/nxp/nxp_mcxnx4x_common.dtsi:794 */
			sc_timer: pwm@91000 {
				compatible = "nxp,sctimer-pwm";  /* in zephyr/dts/arm/nxp/nxp_mcxnx4x_common.dtsi:795 */
				reg = < 0x91000 0x1000 >;        /* in zephyr/dts/arm/nxp/nxp_mcxnx4x_common.dtsi:796 */
				interrupts = < 0x21 0x0 >;       /* in zephyr/dts/arm/nxp/nxp_mcxnx4x_common.dtsi:797 */
				clocks = < &syscon 0x900 >;      /* in zephyr/dts/arm/nxp/nxp_mcxnx4x_common.dtsi:798 */
				prescaler = < 0x1 >;             /* in zephyr/dts/arm/nxp/nxp_mcxnx4x_common.dtsi:800 */
				#pwm-cells = < 0x3 >;            /* in zephyr/dts/arm/nxp/nxp_mcxnx4x_common.dtsi:801 */
				pinctrl-0 = < &pinmux_sctimer >; /* in zephyr/boards/nxp/frdm_mcxn947/frdm_mcxn947.dtsi:282 */
				pinctrl-names = "default";       /* in zephyr/boards/nxp/frdm_mcxn947/frdm_mcxn947.dtsi:283 */
				status = "okay";                 /* in zephyr/boards/nxp/frdm_mcxn947/frdm_mcxn947_mcxn947_cpu0.dtsi:234 */
			};

			/* node '/soc/peripheral@50000000/smartdma@33000' defined in zephyr/dts/arm/nxp/nxp_mcxnx4x_common.dtsi:804 */
			smartdma: smartdma@33000 {
				compatible = "nxp,smartdma"; /* in zephyr/dts/arm/nxp/nxp_mcxnx4x_common.dtsi:805 */
				reg = < 0x33000 0x1000 >;    /* in zephyr/dts/arm/nxp/nxp_mcxnx4x_common.dtsi:806 */
				interrupts = < 0x35 0x0 >;   /* in zephyr/dts/arm/nxp/nxp_mcxnx4x_common.dtsi:808 */
				#dma-cells = < 0x0 >;        /* in zephyr/dts/arm/nxp/nxp_mcxnx4x_common.dtsi:810 */
				status = "okay";             /* in zephyr/boards/nxp/frdm_mcxn947/frdm_mcxn947.dtsi:104 */
				program-mem = < 0x4000000 >; /* in zephyr/boards/nxp/frdm_mcxn947/frdm_mcxn947.dtsi:105 */

				/* node '/soc/peripheral@50000000/smartdma@33000/video-sdma' defined in zephyr/boards/nxp/frdm_mcxn947/frdm_mcxn947.dtsi:107 */
				video_sdma: dvp_20pin_interface: video-sdma {
					status = "disabled";                     /* in zephyr/boards/nxp/frdm_mcxn947/frdm_mcxn947.dtsi:108 */
					compatible = "nxp,video-smartdma";       /* in zephyr/boards/nxp/frdm_mcxn947/frdm_mcxn947.dtsi:109 */
					pinctrl-0 = < &pinmux_smartdma_camera >; /* in zephyr/boards/nxp/frdm_mcxn947/frdm_mcxn947.dtsi:110 */
					pinctrl-names = "default";               /* in zephyr/boards/nxp/frdm_mcxn947/frdm_mcxn947.dtsi:111 */
					vsync-pin = < 0x4 >;                     /* in zephyr/boards/nxp/frdm_mcxn947/frdm_mcxn947.dtsi:112 */
					hsync-pin = < 0xb >;                     /* in zephyr/boards/nxp/frdm_mcxn947/frdm_mcxn947.dtsi:113 */
					pclk-pin = < 0x5 >;                      /* in zephyr/boards/nxp/frdm_mcxn947/frdm_mcxn947.dtsi:114 */
				};
			};

			/* node '/soc/peripheral@50000000/usdhc@109000' defined in zephyr/dts/arm/nxp/nxp_mcxnx4x_common.dtsi:813 */
			usdhc0: usdhc@109000 {
				compatible = "nxp,imx-usdhc";   /* in zephyr/dts/arm/nxp/nxp_mcxnx4x_common.dtsi:814 */
				reg = < 0x109000 0x1000 >;      /* in zephyr/dts/arm/nxp/nxp_mcxnx4x_common.dtsi:815 */
				interrupts = < 0x3d 0x0 >;      /* in zephyr/dts/arm/nxp/nxp_mcxnx4x_common.dtsi:816 */
				clocks = < &syscon 0x200 >;     /* in zephyr/dts/arm/nxp/nxp_mcxnx4x_common.dtsi:818 */
				max-bus-freq = < 0x3197500 >;   /* in zephyr/dts/arm/nxp/nxp_mcxnx4x_common.dtsi:819 */
				min-bus-freq = < 0x61a80 >;     /* in zephyr/dts/arm/nxp/nxp_mcxnx4x_common.dtsi:820 */
				pinctrl-0 = < &pinmux_usdhc0 >; /* in zephyr/boards/nxp/frdm_mcxn947/frdm_mcxn947.dtsi:237 */
				pinctrl-1 = < &pinmux_usdhc0 >; /* in zephyr/boards/nxp/frdm_mcxn947/frdm_mcxn947.dtsi:238 */
				pinctrl-2 = < &pinmux_usdhc0 >; /* in zephyr/boards/nxp/frdm_mcxn947/frdm_mcxn947.dtsi:239 */
				cd-gpios = < &gpio2 0x1 0x1 >;  /* in zephyr/boards/nxp/frdm_mcxn947/frdm_mcxn947.dtsi:240 */
				pinctrl-names = "default",
				                "slow",
				                "med";          /* in zephyr/boards/nxp/frdm_mcxn947/frdm_mcxn947.dtsi:241 */
				no-1-8-v;                       /* in zephyr/boards/nxp/frdm_mcxn947/frdm_mcxn947.dtsi:242 */
				status = "okay";                /* in zephyr/boards/nxp/frdm_mcxn947/frdm_mcxn947_mcxn947_cpu0.dtsi:181 */

				/* node '/soc/peripheral@50000000/usdhc@109000/sdmmc' defined in zephyr/boards/nxp/frdm_mcxn947/frdm_mcxn947_mcxn947_cpu0.dtsi:182 */
				sdmmc {
					compatible = "zephyr,sdmmc-disk"; /* in zephyr/boards/nxp/frdm_mcxn947/frdm_mcxn947_mcxn947_cpu0.dtsi:183 */
					disk-name = "SD";                 /* in zephyr/boards/nxp/frdm_mcxn947/frdm_mcxn947_mcxn947_cpu0.dtsi:184 */
					status = "okay";                  /* in zephyr/boards/nxp/frdm_mcxn947/frdm_mcxn947_mcxn947_cpu0.dtsi:185 */
				};
			};

			/* node '/soc/peripheral@50000000/vref@111000' defined in zephyr/dts/arm/nxp/nxp_mcxnx4x_common.dtsi:823 */
			vref: vref@111000 {
				compatible = "nxp,vref";                 /* in zephyr/dts/arm/nxp/nxp_mcxnx4x_common.dtsi:824 */
				regulator-name = "mcxn54x-vref";         /* in zephyr/dts/arm/nxp/nxp_mcxnx4x_common.dtsi:825 */
				reg = < 0x111000 0x14 >;                 /* in zephyr/dts/arm/nxp/nxp_mcxnx4x_common.dtsi:826 */
				#nxp,reference-cells = < 0x1 >;          /* in zephyr/dts/arm/nxp/nxp_mcxnx4x_common.dtsi:828 */
				nxp,buffer-startup-delay-us = < 0x190 >; /* in zephyr/dts/arm/nxp/nxp_mcxnx4x_common.dtsi:829 */
				nxp,bandgap-startup-time-us = < 0x14 >;  /* in zephyr/dts/arm/nxp/nxp_mcxnx4x_common.dtsi:830 */
				regulator-min-microvolt = < 0xf4240 >;   /* in zephyr/dts/arm/nxp/nxp_mcxnx4x_common.dtsi:831 */
				regulator-max-microvolt = < 0x200b20 >;  /* in zephyr/dts/arm/nxp/nxp_mcxnx4x_common.dtsi:832 */
				status = "okay";                         /* in zephyr/boards/nxp/frdm_mcxn947/frdm_mcxn947_mcxn947_cpu0.dtsi:190 */
				phandle = < 0x16 >;                      /* in zephyr/dts/arm/nxp/nxp_mcxnx4x_common.dtsi:848 */
			};

			/* node '/soc/peripheral@50000000/adc@10d000' defined in zephyr/dts/arm/nxp/nxp_mcxnx4x_common.dtsi:836 */
			lpadc0: adc@10d000 {
				compatible = "nxp,lpc-lpadc";     /* in zephyr/dts/arm/nxp/nxp_mcxnx4x_common.dtsi:837 */
				reg = < 0x10d000 0x1000 >;        /* in zephyr/dts/arm/nxp/nxp_mcxnx4x_common.dtsi:838 */
				interrupts = < 0x2d 0x0 >;        /* in zephyr/dts/arm/nxp/nxp_mcxnx4x_common.dtsi:839 */
				voltage-ref = < 0x1 >;            /* in zephyr/dts/arm/nxp/nxp_mcxnx4x_common.dtsi:841 */
				calibration-average = < 0x80 >;   /* in zephyr/dts/arm/nxp/nxp_mcxnx4x_common.dtsi:842 */
				power-level = < 0x0 >;            /* in zephyr/dts/arm/nxp/nxp_mcxnx4x_common.dtsi:843 */
				offset-value-a = < 0x0 >;         /* in zephyr/dts/arm/nxp/nxp_mcxnx4x_common.dtsi:844 */
				offset-value-b = < 0x0 >;         /* in zephyr/dts/arm/nxp/nxp_mcxnx4x_common.dtsi:845 */
				#io-channel-cells = < 0x1 >;      /* in zephyr/dts/arm/nxp/nxp_mcxnx4x_common.dtsi:846 */
				clocks = < &syscon 0xf00 >;       /* in zephyr/dts/arm/nxp/nxp_mcxnx4x_common.dtsi:847 */
				nxp,references = < &vref 0x708 >; /* in zephyr/dts/arm/nxp/nxp_mcxnx4x_common.dtsi:848 */
				pinctrl-0 = < &pinmux_lpadc0 >;   /* in zephyr/boards/nxp/frdm_mcxn947/frdm_mcxn947.dtsi:246 */
				pinctrl-names = "default";        /* in zephyr/boards/nxp/frdm_mcxn947/frdm_mcxn947.dtsi:247 */
				status = "okay";                  /* in zephyr/boards/nxp/frdm_mcxn947/frdm_mcxn947_mcxn947_cpu0.dtsi:194 */
			};

			/* node '/soc/peripheral@50000000/adc@10e000' defined in zephyr/dts/arm/nxp/nxp_mcxnx4x_common.dtsi:851 */
			lpadc1: adc@10e000 {
				compatible = "nxp,lpc-lpadc";   /* in zephyr/dts/arm/nxp/nxp_mcxnx4x_common.dtsi:852 */
				reg = < 0x10e000 0x1000 >;      /* in zephyr/dts/arm/nxp/nxp_mcxnx4x_common.dtsi:853 */
				interrupts = < 0x2e 0x0 >;      /* in zephyr/dts/arm/nxp/nxp_mcxnx4x_common.dtsi:854 */
				status = "disabled";            /* in zephyr/dts/arm/nxp/nxp_mcxnx4x_common.dtsi:855 */
				voltage-ref = < 0x0 >;          /* in zephyr/dts/arm/nxp/nxp_mcxnx4x_common.dtsi:856 */
				calibration-average = < 0x80 >; /* in zephyr/dts/arm/nxp/nxp_mcxnx4x_common.dtsi:857 */
				power-level = < 0x1 >;          /* in zephyr/dts/arm/nxp/nxp_mcxnx4x_common.dtsi:858 */
				offset-value-a = < 0x0 >;       /* in zephyr/dts/arm/nxp/nxp_mcxnx4x_common.dtsi:859 */
				offset-value-b = < 0x0 >;       /* in zephyr/dts/arm/nxp/nxp_mcxnx4x_common.dtsi:860 */
				#io-channel-cells = < 0x1 >;    /* in zephyr/dts/arm/nxp/nxp_mcxnx4x_common.dtsi:861 */
				clocks = < &syscon 0xf01 >;     /* in zephyr/dts/arm/nxp/nxp_mcxnx4x_common.dtsi:862 */
			};

			/* node '/soc/peripheral@50000000/usbd@dd000' defined in zephyr/dts/arm/nxp/nxp_mcxnx4x_common.dtsi:865 */
			usb0: usbd@dd000 {
				compatible = "nxp,kinetis-usbd"; /* in zephyr/dts/arm/nxp/nxp_mcxnx4x_common.dtsi:866 */
				reg = < 0xdd000 0x1000 >;        /* in zephyr/dts/arm/nxp/nxp_mcxnx4x_common.dtsi:867 */
				interrupts = < 0x32 0x1 >;       /* in zephyr/dts/arm/nxp/nxp_mcxnx4x_common.dtsi:868 */
				interrupt-names = "usbfs0";      /* in zephyr/dts/arm/nxp/nxp_mcxnx4x_common.dtsi:869 */
				num-bidir-endpoints = < 0x10 >;  /* in zephyr/dts/arm/nxp/nxp_mcxnx4x_common.dtsi:870 */
				no-voltage-regulator;            /* in zephyr/dts/arm/nxp/nxp_mcxnx4x_common.dtsi:871 */
				status = "disabled";             /* in zephyr/dts/arm/nxp/nxp_mcxnx4x_common.dtsi:872 */
			};

			/* node '/soc/peripheral@50000000/usbd@10b000' defined in zephyr/dts/arm/nxp/nxp_mcxnx4x_common.dtsi:875 */
			usb1: zephyr_udc0: usbd@10b000 {
				compatible = "nxp,ehci";       /* in zephyr/dts/arm/nxp/nxp_mcxnx4x_common.dtsi:876 */
				reg = < 0x10b000 0x1000 >;     /* in zephyr/dts/arm/nxp/nxp_mcxnx4x_common.dtsi:877 */
				interrupts = < 0x43 0x0 >;     /* in zephyr/dts/arm/nxp/nxp_mcxnx4x_common.dtsi:878 */
				interrupt-names = "usb_otg";   /* in zephyr/dts/arm/nxp/nxp_mcxnx4x_common.dtsi:879 */
				num-bidir-endpoints = < 0x8 >; /* in zephyr/dts/arm/nxp/nxp_mcxnx4x_common.dtsi:880 */
				status = "okay";               /* in zephyr/boards/nxp/frdm_mcxn947/frdm_mcxn947_mcxn947_cpu0.dtsi:198 */
				phy-handle = < &usbphy1 >;     /* in zephyr/boards/nxp/frdm_mcxn947/frdm_mcxn947_mcxn947_cpu0.dtsi:199 */
			};

			/* node '/soc/peripheral@50000000/usbphy@10a000' defined in zephyr/dts/arm/nxp/nxp_mcxnx4x_common.dtsi:884 */
			usbphy1: usbphy@10a000 {
				compatible = "nxp,usbphy";   /* in zephyr/dts/arm/nxp/nxp_mcxnx4x_common.dtsi:885 */
				reg = < 0x10a000 0x1000 >;   /* in zephyr/dts/arm/nxp/nxp_mcxnx4x_common.dtsi:886 */
				status = "okay";             /* in zephyr/boards/nxp/frdm_mcxn947/frdm_mcxn947_mcxn947_cpu0.dtsi:203 */
				tx-d-cal = < 0x4 >;          /* in zephyr/boards/nxp/frdm_mcxn947/frdm_mcxn947_mcxn947_cpu0.dtsi:204 */
				tx-cal-45-dp-ohms = < 0x7 >; /* in zephyr/boards/nxp/frdm_mcxn947/frdm_mcxn947_mcxn947_cpu0.dtsi:205 */
				tx-cal-45-dm-ohms = < 0x7 >; /* in zephyr/boards/nxp/frdm_mcxn947/frdm_mcxn947_mcxn947_cpu0.dtsi:206 */
				phandle = < 0x18 >;          /* in zephyr/boards/nxp/frdm_mcxn947/frdm_mcxn947_mcxn947_cpu0.dtsi:199 */
			};

			/* node '/soc/peripheral@50000000/lpcmp@51000' defined in zephyr/dts/arm/nxp/nxp_mcxnx4x_common.dtsi:890 */
			lpcmp0: lpcmp@51000 {
				compatible = "nxp,lpcmp";       /* in zephyr/dts/arm/nxp/nxp_mcxnx4x_common.dtsi:891 */
				reg = < 0x51000 0x1000 >;       /* in zephyr/dts/arm/nxp/nxp_mcxnx4x_common.dtsi:892 */
				interrupts = < 0x6d 0x0 >;      /* in zephyr/dts/arm/nxp/nxp_mcxnx4x_common.dtsi:893 */
				#io-channel-cells = < 0x2 >;    /* in zephyr/dts/arm/nxp/nxp_mcxnx4x_common.dtsi:895 */
				pinctrl-0 = < &pinmux_lpcmp0 >; /* in zephyr/boards/nxp/frdm_mcxn947/frdm_mcxn947.dtsi:267 */
				pinctrl-names = "default";      /* in zephyr/boards/nxp/frdm_mcxn947/frdm_mcxn947.dtsi:268 */
				status = "okay";                /* in zephyr/boards/nxp/frdm_mcxn947/frdm_mcxn947_mcxn947_cpu0.dtsi:210 */
			};

			/* node '/soc/peripheral@50000000/lpcmp@52000' defined in zephyr/dts/arm/nxp/nxp_mcxnx4x_common.dtsi:898 */
			lpcmp1: lpcmp@52000 {
				compatible = "nxp,lpcmp";    /* in zephyr/dts/arm/nxp/nxp_mcxnx4x_common.dtsi:899 */
				reg = < 0x52000 0x1000 >;    /* in zephyr/dts/arm/nxp/nxp_mcxnx4x_common.dtsi:900 */
				interrupts = < 0x6e 0x0 >;   /* in zephyr/dts/arm/nxp/nxp_mcxnx4x_common.dtsi:901 */
				status = "disabled";         /* in zephyr/dts/arm/nxp/nxp_mcxnx4x_common.dtsi:902 */
				#io-channel-cells = < 0x2 >; /* in zephyr/dts/arm/nxp/nxp_mcxnx4x_common.dtsi:903 */
			};

			/* node '/soc/peripheral@50000000/can@d4000' defined in zephyr/dts/arm/nxp/nxp_mcxnx4x_common.dtsi:906 */
			flexcan0: can@d4000 {
				compatible = "nxp,flexcan";       /* in zephyr/dts/arm/nxp/nxp_mcxnx4x_common.dtsi:907 */
				reg = < 0xd4000 0x4000 >;         /* in zephyr/dts/arm/nxp/nxp_mcxnx4x_common.dtsi:908 */
				interrupts = < 0x3e 0x0 >;        /* in zephyr/dts/arm/nxp/nxp_mcxnx4x_common.dtsi:909 */
				interrupt-names = "common";       /* in zephyr/dts/arm/nxp/nxp_mcxnx4x_common.dtsi:910 */
				clocks = < &syscon 0x1000 >;      /* in zephyr/dts/arm/nxp/nxp_mcxnx4x_common.dtsi:911 */
				clk-source = < 0x0 >;             /* in zephyr/dts/arm/nxp/nxp_mcxnx4x_common.dtsi:912 */
				pinctrl-0 = < &pinmux_flexcan0 >; /* in zephyr/boards/nxp/frdm_mcxn947/frdm_mcxn947.dtsi:277 */
				pinctrl-names = "default";        /* in zephyr/boards/nxp/frdm_mcxn947/frdm_mcxn947.dtsi:278 */
				status = "okay";                  /* in zephyr/boards/nxp/frdm_mcxn947/frdm_mcxn947_mcxn947_cpu0.dtsi:173 */
			};

			/* node '/soc/peripheral@50000000/lptmr@4a000' defined in zephyr/dts/arm/nxp/nxp_mcxnx4x_common.dtsi:916 */
			lptmr0: lptmr@4a000 {
				compatible = "nxp,lptmr";     /* in zephyr/dts/arm/nxp/nxp_mcxnx4x_common.dtsi:917 */
				reg = < 0x4a000 0x1000 >;     /* in zephyr/dts/arm/nxp/nxp_mcxnx4x_common.dtsi:918 */
				interrupts = < 0x8f 0x0 >;    /* in zephyr/dts/arm/nxp/nxp_mcxnx4x_common.dtsi:919 */
				clock-frequency = < 0x3e80 >; /* in zephyr/dts/arm/nxp/nxp_mcxnx4x_common.dtsi:920 */
				prescaler = < 0x1 >;          /* in zephyr/dts/arm/nxp/nxp_mcxnx4x_common.dtsi:921 */
				clk-source = < 0x1 >;         /* in zephyr/dts/arm/nxp/nxp_mcxnx4x_common.dtsi:922 */
				resolution = < 0x20 >;        /* in zephyr/dts/arm/nxp/nxp_mcxnx4x_common.dtsi:923 */
				status = "okay";              /* in zephyr/boards/nxp/frdm_mcxn947/frdm_mcxn947_mcxn947_cpu0.dtsi:214 */
			};

			/* node '/soc/peripheral@50000000/lptmr@4b000' defined in zephyr/dts/arm/nxp/nxp_mcxnx4x_common.dtsi:926 */
			lptmr1: lptmr@4b000 {
				compatible = "nxp,lptmr";     /* in zephyr/dts/arm/nxp/nxp_mcxnx4x_common.dtsi:927 */
				reg = < 0x4b000 0x1000 >;     /* in zephyr/dts/arm/nxp/nxp_mcxnx4x_common.dtsi:928 */
				interrupts = < 0x90 0x0 >;    /* in zephyr/dts/arm/nxp/nxp_mcxnx4x_common.dtsi:929 */
				clock-frequency = < 0x3e80 >; /* in zephyr/dts/arm/nxp/nxp_mcxnx4x_common.dtsi:930 */
				prescaler = < 0x1 >;          /* in zephyr/dts/arm/nxp/nxp_mcxnx4x_common.dtsi:931 */
				clk-source = < 0x1 >;         /* in zephyr/dts/arm/nxp/nxp_mcxnx4x_common.dtsi:932 */
				resolution = < 0x20 >;        /* in zephyr/dts/arm/nxp/nxp_mcxnx4x_common.dtsi:933 */
			};

			/* node '/soc/peripheral@50000000/i3c@21000' defined in zephyr/dts/arm/nxp/nxp_mcxnx4x_common.dtsi:936 */
			i3c0: i3c@21000 {
				compatible = "nxp,mcux-i3c"; /* in zephyr/dts/arm/nxp/nxp_mcxnx4x_common.dtsi:937 */
				reg = < 0x21000 0x1000 >;    /* in zephyr/dts/arm/nxp/nxp_mcxnx4x_common.dtsi:938 */
				interrupts = < 0x5f 0x0 >;   /* in zephyr/dts/arm/nxp/nxp_mcxnx4x_common.dtsi:939 */
				clocks = < &syscon 0x600 >;  /* in zephyr/dts/arm/nxp/nxp_mcxnx4x_common.dtsi:940 */
				clk-divider = < 0x6 >;       /* in zephyr/dts/arm/nxp/nxp_mcxnx4x_common.dtsi:941 */
				clk-divider-slow = < 0x1 >;  /* in zephyr/dts/arm/nxp/nxp_mcxnx4x_common.dtsi:942 */
				clk-divider-tc = < 0x1 >;    /* in zephyr/dts/arm/nxp/nxp_mcxnx4x_common.dtsi:943 */
				status = "disabled";         /* in zephyr/dts/arm/nxp/nxp_mcxnx4x_common.dtsi:944 */
				#address-cells = < 0x3 >;    /* in zephyr/dts/arm/nxp/nxp_mcxnx4x_common.dtsi:945 */
				#size-cells = < 0x0 >;       /* in zephyr/dts/arm/nxp/nxp_mcxnx4x_common.dtsi:946 */
			};

			/* node '/soc/peripheral@50000000/i3c@22000' defined in zephyr/dts/arm/nxp/nxp_mcxnx4x_common.dtsi:949 */
			i3c1: i3c@22000 {
				compatible = "nxp,mcux-i3c";  /* in zephyr/dts/arm/nxp/nxp_mcxnx4x_common.dtsi:950 */
				reg = < 0x22000 0x1000 >;     /* in zephyr/dts/arm/nxp/nxp_mcxnx4x_common.dtsi:951 */
				interrupts = < 0x60 0x0 >;    /* in zephyr/dts/arm/nxp/nxp_mcxnx4x_common.dtsi:952 */
				clocks = < &syscon 0x601 >;   /* in zephyr/dts/arm/nxp/nxp_mcxnx4x_common.dtsi:953 */
				clk-divider = < 0x6 >;        /* in zephyr/dts/arm/nxp/nxp_mcxnx4x_common.dtsi:954 */
				clk-divider-slow = < 0x1 >;   /* in zephyr/dts/arm/nxp/nxp_mcxnx4x_common.dtsi:955 */
				clk-divider-tc = < 0x1 >;     /* in zephyr/dts/arm/nxp/nxp_mcxnx4x_common.dtsi:956 */
				#address-cells = < 0x3 >;     /* in zephyr/dts/arm/nxp/nxp_mcxnx4x_common.dtsi:958 */
				#size-cells = < 0x0 >;        /* in zephyr/dts/arm/nxp/nxp_mcxnx4x_common.dtsi:959 */
				pinctrl-0 = < &pinmux_i3c1 >; /* in zephyr/boards/nxp/frdm_mcxn947/frdm_mcxn947.dtsi:272 */
				pinctrl-names = "default";    /* in zephyr/boards/nxp/frdm_mcxn947/frdm_mcxn947.dtsi:273 */
				status = "okay";              /* in zephyr/boards/nxp/frdm_mcxn947/frdm_mcxn947_mcxn947_cpu0.dtsi:218 */
			};

			/* node '/soc/peripheral@50000000/flexio@105000' defined in zephyr/dts/arm/nxp/nxp_mcxnx4x_common.dtsi:962 */
			flexio0: flexio@105000 {
				compatible = "nxp,flexio";   /* in zephyr/dts/arm/nxp/nxp_mcxnx4x_common.dtsi:963 */
				reg = < 0x105000 0x1000 >;   /* in zephyr/dts/arm/nxp/nxp_mcxnx4x_common.dtsi:964 */
				interrupts = < 0x69 0x0 >;   /* in zephyr/dts/arm/nxp/nxp_mcxnx4x_common.dtsi:966 */
				clocks = < &syscon 0x1100 >; /* in zephyr/dts/arm/nxp/nxp_mcxnx4x_common.dtsi:967 */
				status = "okay";             /* in zephyr/boards/nxp/frdm_mcxn947/frdm_mcxn947_mcxn947_cpu0.dtsi:222 */

				/* node '/soc/peripheral@50000000/flexio@105000/flexio0-lcd' defined in zephyr/dts/arm/nxp/nxp_mcxnx4x_common.dtsi:968 */
				flexio0_lcd: zephyr_mipi_dbi_parallel: flexio0-lcd {
					compatible = "nxp,mipi-dbi-flexio-lcdif"; /* in zephyr/dts/arm/nxp/nxp_mcxnx4x_common.dtsi:969 */
					status = "disabled";                      /* in zephyr/dts/arm/nxp/nxp_mcxnx4x_common.dtsi:970 */
					dmas = < &edma0 0x0 0x3d >;               /* in zephyr/boards/nxp/frdm_mcxn947/frdm_mcxn947.dtsi:252 */
					dma-names = "tx";                         /* in zephyr/boards/nxp/frdm_mcxn947/frdm_mcxn947.dtsi:253 */
					shifters-count = < 0x8 >;                 /* in zephyr/boards/nxp/frdm_mcxn947/frdm_mcxn947.dtsi:254 */
					timers-count = < 0x1 >;                   /* in zephyr/boards/nxp/frdm_mcxn947/frdm_mcxn947.dtsi:255 */
					enwr-pin = < 0x1 >;                       /* in zephyr/boards/nxp/frdm_mcxn947/frdm_mcxn947.dtsi:256 */
					rd-pin = < 0x0 >;                         /* in zephyr/boards/nxp/frdm_mcxn947/frdm_mcxn947.dtsi:257 */
					data-pin-start = < 0x10 >;                /* in zephyr/boards/nxp/frdm_mcxn947/frdm_mcxn947.dtsi:258 */
					reset-gpios = < &gpio4 0x7 0x0 >;         /* in zephyr/boards/nxp/frdm_mcxn947/frdm_mcxn947.dtsi:259 */
					cs-gpios = < &gpio0 0xc 0x0 >;            /* in zephyr/boards/nxp/frdm_mcxn947/frdm_mcxn947.dtsi:260 */
					rs-gpios = < &gpio0 0x7 0x0 >;            /* in zephyr/boards/nxp/frdm_mcxn947/frdm_mcxn947.dtsi:261 */
					pinctrl-0 = < &pinmux_flexio_lcd >;       /* in zephyr/boards/nxp/frdm_mcxn947/frdm_mcxn947.dtsi:262 */
					pinctrl-names = "default";                /* in zephyr/boards/nxp/frdm_mcxn947/frdm_mcxn947.dtsi:263 */
				};
			};

			/* node '/soc/peripheral@50000000/mrt@13000' defined in zephyr/dts/arm/nxp/nxp_mcxnx4x_common.dtsi:974 */
			mrt0: mrt@13000 {
				compatible = "nxp,mrt";      /* in zephyr/dts/arm/nxp/nxp_mcxnx4x_common.dtsi:975 */
				reg = < 0x13000 0x1000 >;    /* in zephyr/dts/arm/nxp/nxp_mcxnx4x_common.dtsi:976 */
				interrupts = < 0x1e 0x0 >;   /* in zephyr/dts/arm/nxp/nxp_mcxnx4x_common.dtsi:977 */
				num-channels = < 0x4 >;      /* in zephyr/dts/arm/nxp/nxp_mcxnx4x_common.dtsi:978 */
				num-bits = < 0x18 >;         /* in zephyr/dts/arm/nxp/nxp_mcxnx4x_common.dtsi:979 */
				clocks = < &syscon 0xb00 >;  /* in zephyr/dts/arm/nxp/nxp_mcxnx4x_common.dtsi:980 */
				resets = < &reset 0x10000 >; /* in zephyr/dts/arm/nxp/nxp_mcxnx4x_common.dtsi:981 */
				#address-cells = < 0x1 >;    /* in zephyr/dts/arm/nxp/nxp_mcxnx4x_common.dtsi:982 */
				#size-cells = < 0x0 >;       /* in zephyr/dts/arm/nxp/nxp_mcxnx4x_common.dtsi:983 */

				/* node '/soc/peripheral@50000000/mrt@13000/mrt0_channel@0' defined in zephyr/dts/arm/nxp/nxp_mcxnx4x_common.dtsi:985 */
				mrt0_channel0: mrt0_channel@0 {
					compatible = "nxp,mrt-channel"; /* in zephyr/dts/arm/nxp/nxp_mcxnx4x_common.dtsi:986 */
					reg = < 0x0 >;                  /* in zephyr/dts/arm/nxp/nxp_mcxnx4x_common.dtsi:987 */
					status = "okay";                /* in zephyr/boards/nxp/frdm_mcxn947/frdm_mcxn947_mcxn947_cpu0.dtsi:226 */
				};

				/* node '/soc/peripheral@50000000/mrt@13000/mrt0_channel@1' defined in zephyr/dts/arm/nxp/nxp_mcxnx4x_common.dtsi:991 */
				mrt0_channel1: mrt0_channel@1 {
					compatible = "nxp,mrt-channel"; /* in zephyr/dts/arm/nxp/nxp_mcxnx4x_common.dtsi:992 */
					reg = < 0x1 >;                  /* in zephyr/dts/arm/nxp/nxp_mcxnx4x_common.dtsi:993 */
					status = "disabled";            /* in zephyr/dts/arm/nxp/nxp_mcxnx4x_common.dtsi:994 */
				};

				/* node '/soc/peripheral@50000000/mrt@13000/mrt0_channel@2' defined in zephyr/dts/arm/nxp/nxp_mcxnx4x_common.dtsi:997 */
				mrt0_channel2: mrt0_channel@2 {
					compatible = "nxp,mrt-channel"; /* in zephyr/dts/arm/nxp/nxp_mcxnx4x_common.dtsi:998 */
					reg = < 0x2 >;                  /* in zephyr/dts/arm/nxp/nxp_mcxnx4x_common.dtsi:999 */
					status = "disabled";            /* in zephyr/dts/arm/nxp/nxp_mcxnx4x_common.dtsi:1000 */
				};

				/* node '/soc/peripheral@50000000/mrt@13000/mrt0_channel@3' defined in zephyr/dts/arm/nxp/nxp_mcxnx4x_common.dtsi:1003 */
				mrt0_channel3: mrt0_channel@3 {
					compatible = "nxp,mrt-channel"; /* in zephyr/dts/arm/nxp/nxp_mcxnx4x_common.dtsi:1004 */
					reg = < 0x3 >;                  /* in zephyr/dts/arm/nxp/nxp_mcxnx4x_common.dtsi:1005 */
					status = "disabled";            /* in zephyr/dts/arm/nxp/nxp_mcxnx4x_common.dtsi:1006 */
				};
			};

			/* node '/soc/peripheral@50000000/rtc@4c000' defined in zephyr/dts/arm/nxp/nxp_mcxnx4x_common.dtsi:1010 */
			rtc: rtc@4c000 {
				compatible = "nxp,irtc";      /* in zephyr/dts/arm/nxp/nxp_mcxnx4x_common.dtsi:1011 */
				reg = < 0x4c000 0x1000 >;     /* in zephyr/dts/arm/nxp/nxp_mcxnx4x_common.dtsi:1012 */
				interrupts = < 0x34 0x0 >;    /* in zephyr/dts/arm/nxp/nxp_mcxnx4x_common.dtsi:1014 */
				prescaler = < 0x1 >;          /* in zephyr/dts/arm/nxp/nxp_mcxnx4x_common.dtsi:1015 */
				clock-frequency = < 0x4000 >; /* in zephyr/dts/arm/nxp/nxp_mcxnx4x_common.dtsi:1016 */
				clock-src = < 0x0 >;          /* in zephyr/dts/arm/nxp/nxp_mcxnx4x_common.dtsi:1017 */
				alarms-count = < 0x1 >;       /* in zephyr/dts/arm/nxp/nxp_mcxnx4x_common.dtsi:1018 */
				status = "okay";              /* in zephyr/boards/nxp/frdm_mcxn947/frdm_mcxn947_mcxn947_cpu0.dtsi:230 */
			};

			/* node '/soc/peripheral@50000000/sai@106000' defined in zephyr/dts/arm/nxp/nxp_mcxnx4x_common.dtsi:1021 */
			sai0: sai@106000 {
				compatible = "nxp,mcux-i2s";           /* in zephyr/dts/arm/nxp/nxp_mcxnx4x_common.dtsi:1022 */
				#address-cells = < 0x1 >;              /* in zephyr/dts/arm/nxp/nxp_mcxnx4x_common.dtsi:1023 */
				#size-cells = < 0x0 >;                 /* in zephyr/dts/arm/nxp/nxp_mcxnx4x_common.dtsi:1024 */
				#pinmux-cells = < 0x2 >;               /* in zephyr/dts/arm/nxp/nxp_mcxnx4x_common.dtsi:1025 */
				reg = < 0x106000 0x1000 >;             /* in zephyr/dts/arm/nxp/nxp_mcxnx4x_common.dtsi:1026 */
				clocks = < &syscon 0x1600 >;           /* in zephyr/dts/arm/nxp/nxp_mcxnx4x_common.dtsi:1027 */
				pinmuxes = < &sai0 0x100 0x40000000 >; /* in zephyr/dts/arm/nxp/nxp_mcxnx4x_common.dtsi:1028 */
				interrupts = < 0x3b 0x0 >;             /* in zephyr/dts/arm/nxp/nxp_mcxnx4x_common.dtsi:1029 */
				dmas = < &edma0 0x0 0x63 >,
				       < &edma0 0x0 0x64 >;            /* in zephyr/dts/arm/nxp/nxp_mcxnx4x_common.dtsi:1030 */
				dma-names = "rx",
				            "tx";                      /* in zephyr/dts/arm/nxp/nxp_mcxnx4x_common.dtsi:1031 */
				nxp,tx-channel = < 0x1 >;              /* in zephyr/dts/arm/nxp/nxp_mcxnx4x_common.dtsi:1032 */
				nxp,tx-dma-channel = < 0x0 >;          /* in zephyr/dts/arm/nxp/nxp_mcxnx4x_common.dtsi:1033 */
				nxp,rx-dma-channel = < 0x1 >;          /* in zephyr/dts/arm/nxp/nxp_mcxnx4x_common.dtsi:1034 */
				pinctrl-0 = < &pinmux_sai0 >;          /* in zephyr/boards/nxp/frdm_mcxn947/frdm_mcxn947.dtsi:208 */
				pinctrl-names = "default";             /* in zephyr/boards/nxp/frdm_mcxn947/frdm_mcxn947.dtsi:209 */
				status = "okay";                       /* in zephyr/boards/nxp/frdm_mcxn947/frdm_mcxn947_mcxn947_cpu0.dtsi:241 */
				phandle = < 0x20 >;                    /* in zephyr/dts/arm/nxp/nxp_mcxnx4x_common.dtsi:1028 */
			};

			/* node '/soc/peripheral@50000000/sai@107000' defined in zephyr/dts/arm/nxp/nxp_mcxnx4x_common.dtsi:1038 */
			sai1: sai@107000 {
				compatible = "nxp,mcux-i2s";           /* in zephyr/dts/arm/nxp/nxp_mcxnx4x_common.dtsi:1039 */
				#address-cells = < 0x1 >;              /* in zephyr/dts/arm/nxp/nxp_mcxnx4x_common.dtsi:1040 */
				#size-cells = < 0x0 >;                 /* in zephyr/dts/arm/nxp/nxp_mcxnx4x_common.dtsi:1041 */
				#pinmux-cells = < 0x2 >;               /* in zephyr/dts/arm/nxp/nxp_mcxnx4x_common.dtsi:1042 */
				reg = < 0x107000 0x1000 >;             /* in zephyr/dts/arm/nxp/nxp_mcxnx4x_common.dtsi:1043 */
				clocks = < &syscon 0x1601 >;           /* in zephyr/dts/arm/nxp/nxp_mcxnx4x_common.dtsi:1044 */
				pinmuxes = < &sai1 0x100 0x40000000 >; /* in zephyr/dts/arm/nxp/nxp_mcxnx4x_common.dtsi:1045 */
				interrupts = < 0x3c 0x0 >;             /* in zephyr/dts/arm/nxp/nxp_mcxnx4x_common.dtsi:1046 */
				dmas = < &edma0 0x0 0x65 >,
				       < &edma0 0x0 0x66 >;            /* in zephyr/dts/arm/nxp/nxp_mcxnx4x_common.dtsi:1047 */
				dma-names = "rx",
				            "tx";                      /* in zephyr/dts/arm/nxp/nxp_mcxnx4x_common.dtsi:1048 */
				nxp,tx-channel = < 0x1 >;              /* in zephyr/dts/arm/nxp/nxp_mcxnx4x_common.dtsi:1049 */
				nxp,tx-dma-channel = < 0x2 >;          /* in zephyr/dts/arm/nxp/nxp_mcxnx4x_common.dtsi:1050 */
				nxp,rx-dma-channel = < 0x3 >;          /* in zephyr/dts/arm/nxp/nxp_mcxnx4x_common.dtsi:1051 */
				pinctrl-0 = < &pinmux_sai1 >;          /* in zephyr/boards/nxp/frdm_mcxn947/frdm_mcxn947.dtsi:203 */
				pinctrl-names = "default";             /* in zephyr/boards/nxp/frdm_mcxn947/frdm_mcxn947.dtsi:204 */
				status = "okay";                       /* in zephyr/boards/nxp/frdm_mcxn947/frdm_mcxn947_mcxn947_cpu0.dtsi:238 */
				phandle = < 0x22 >;                    /* in zephyr/dts/arm/nxp/nxp_mcxnx4x_common.dtsi:1045 */
			};

			/* node '/soc/peripheral@50000000/dac@112000' defined in zephyr/dts/arm/nxp/nxp_mcxn94x_common.dtsi:10 */
			dac1: dac@112000 {
				compatible = "nxp,lpdac";    /* in zephyr/dts/arm/nxp/nxp_mcxn94x_common.dtsi:11 */
				reg = < 0x112000 0x1000 >;   /* in zephyr/dts/arm/nxp/nxp_mcxn94x_common.dtsi:12 */
				interrupts = < 0x6b 0x0 >;   /* in zephyr/dts/arm/nxp/nxp_mcxn94x_common.dtsi:13 */
				status = "disabled";         /* in zephyr/dts/arm/nxp/nxp_mcxn94x_common.dtsi:14 */
				voltage-reference = < 0x0 >; /* in zephyr/dts/arm/nxp/nxp_mcxn94x_common.dtsi:15 */
				#io-channel-cells = < 0x1 >; /* in zephyr/dts/arm/nxp/nxp_mcxn94x_common.dtsi:16 */
			};

			/* node '/soc/peripheral@50000000/flexpwm@d0000' defined in zephyr/dts/arm/nxp/nxp_mcxn94x_common.dtsi:19 */
			flexpwm1: flexpwm@d0000 {
				compatible = "nxp,flexpwm";       /* in zephyr/dts/arm/nxp/nxp_mcxn94x_common.dtsi:20 */
				reg = < 0xd0000 0x1000 >;         /* in zephyr/dts/arm/nxp/nxp_mcxn94x_common.dtsi:21 */
				interrupt-names = "RELOAD-ERROR",
				                  "FAULT";        /* in zephyr/dts/arm/nxp/nxp_mcxn94x_common.dtsi:22 */
				interrupts = < 0x76 0x0 >,
				             < 0x77 0x0 >;        /* in zephyr/dts/arm/nxp/nxp_mcxn94x_common.dtsi:23 */

				/* node '/soc/peripheral@50000000/flexpwm@d0000/pwm0' defined in zephyr/dts/arm/nxp/nxp_mcxn94x_common.dtsi:24 */
				flexpwm1_pwm0: pwm0 {
					compatible = "nxp,imx-pwm";            /* in zephyr/dts/arm/nxp/nxp_mcxn94x_common.dtsi:25 */
					index = < 0x0 >;                       /* in zephyr/dts/arm/nxp/nxp_mcxn94x_common.dtsi:26 */
					interrupts = < 0x78 0x0 >;             /* in zephyr/dts/arm/nxp/nxp_mcxn94x_common.dtsi:27 */
					#pwm-cells = < 0x3 >;                  /* in zephyr/dts/arm/nxp/nxp_mcxn94x_common.dtsi:28 */
					clocks = < &syscon 0x400 >;            /* in zephyr/dts/arm/nxp/nxp_mcxn94x_common.dtsi:29 */
					nxp,prescaler = < 0x80 >;              /* in zephyr/dts/arm/nxp/nxp_mcxn94x_common.dtsi:30 */
					run-in-wait;                           /* in zephyr/dts/arm/nxp/nxp_mcxn94x_common.dtsi:32 */
					pinctrl-0 = < &pinmux_flexpwm1_pwm0 >; /* in zephyr/boards/nxp/frdm_mcxn947/frdm_mcxn947.dtsi:232 */
					pinctrl-names = "default";             /* in zephyr/boards/nxp/frdm_mcxn947/frdm_mcxn947.dtsi:233 */
					status = "okay";                       /* in zephyr/boards/nxp/frdm_mcxn947/frdm_mcxn947_mcxn947_cpu0.dtsi:169 */
				};

				/* node '/soc/peripheral@50000000/flexpwm@d0000/pwm1' defined in zephyr/dts/arm/nxp/nxp_mcxn94x_common.dtsi:35 */
				flexpwm1_pwm1: pwm1 {
					compatible = "nxp,imx-pwm"; /* in zephyr/dts/arm/nxp/nxp_mcxn94x_common.dtsi:36 */
					index = < 0x1 >;            /* in zephyr/dts/arm/nxp/nxp_mcxn94x_common.dtsi:37 */
					interrupts = < 0x79 0x0 >;  /* in zephyr/dts/arm/nxp/nxp_mcxn94x_common.dtsi:38 */
					#pwm-cells = < 0x3 >;       /* in zephyr/dts/arm/nxp/nxp_mcxn94x_common.dtsi:39 */
					clocks = < &syscon 0x400 >; /* in zephyr/dts/arm/nxp/nxp_mcxn94x_common.dtsi:40 */
					nxp,prescaler = < 0x80 >;   /* in zephyr/dts/arm/nxp/nxp_mcxn94x_common.dtsi:41 */
					status = "disabled";        /* in zephyr/dts/arm/nxp/nxp_mcxn94x_common.dtsi:42 */
					run-in-wait;                /* in zephyr/dts/arm/nxp/nxp_mcxn94x_common.dtsi:43 */
				};

				/* node '/soc/peripheral@50000000/flexpwm@d0000/pwm2' defined in zephyr/dts/arm/nxp/nxp_mcxn94x_common.dtsi:46 */
				flexpwm1_pwm2: pwm2 {
					compatible = "nxp,imx-pwm"; /* in zephyr/dts/arm/nxp/nxp_mcxn94x_common.dtsi:47 */
					index = < 0x2 >;            /* in zephyr/dts/arm/nxp/nxp_mcxn94x_common.dtsi:48 */
					interrupts = < 0x7a 0x0 >;  /* in zephyr/dts/arm/nxp/nxp_mcxn94x_common.dtsi:49 */
					#pwm-cells = < 0x3 >;       /* in zephyr/dts/arm/nxp/nxp_mcxn94x_common.dtsi:50 */
					clocks = < &syscon 0x400 >; /* in zephyr/dts/arm/nxp/nxp_mcxn94x_common.dtsi:51 */
					nxp,prescaler = < 0x80 >;   /* in zephyr/dts/arm/nxp/nxp_mcxn94x_common.dtsi:52 */
					status = "disabled";        /* in zephyr/dts/arm/nxp/nxp_mcxn94x_common.dtsi:53 */
					run-in-wait;                /* in zephyr/dts/arm/nxp/nxp_mcxn94x_common.dtsi:54 */
				};

				/* node '/soc/peripheral@50000000/flexpwm@d0000/pwm3' defined in zephyr/dts/arm/nxp/nxp_mcxn94x_common.dtsi:57 */
				flexpwm1_pwm3: pwm3 {
					compatible = "nxp,imx-pwm"; /* in zephyr/dts/arm/nxp/nxp_mcxn94x_common.dtsi:58 */
					index = < 0x3 >;            /* in zephyr/dts/arm/nxp/nxp_mcxn94x_common.dtsi:59 */
					interrupts = < 0x7b 0x0 >;  /* in zephyr/dts/arm/nxp/nxp_mcxn94x_common.dtsi:60 */
					#pwm-cells = < 0x3 >;       /* in zephyr/dts/arm/nxp/nxp_mcxn94x_common.dtsi:61 */
					clocks = < &syscon 0x400 >; /* in zephyr/dts/arm/nxp/nxp_mcxn94x_common.dtsi:62 */
					nxp,prescaler = < 0x80 >;   /* in zephyr/dts/arm/nxp/nxp_mcxn94x_common.dtsi:63 */
					status = "disabled";        /* in zephyr/dts/arm/nxp/nxp_mcxn94x_common.dtsi:64 */
					run-in-wait;                /* in zephyr/dts/arm/nxp/nxp_mcxn94x_common.dtsi:65 */
				};
			};

			/* node '/soc/peripheral@50000000/lpcmp@53000' defined in zephyr/dts/arm/nxp/nxp_mcxn94x_common.dtsi:69 */
			lpcmp2: lpcmp@53000 {
				compatible = "nxp,lpcmp";    /* in zephyr/dts/arm/nxp/nxp_mcxn94x_common.dtsi:70 */
				reg = < 0x53000 0x1000 >;    /* in zephyr/dts/arm/nxp/nxp_mcxn94x_common.dtsi:71 */
				interrupts = < 0x6f 0x0 >;   /* in zephyr/dts/arm/nxp/nxp_mcxn94x_common.dtsi:72 */
				status = "disabled";         /* in zephyr/dts/arm/nxp/nxp_mcxn94x_common.dtsi:73 */
				#io-channel-cells = < 0x2 >; /* in zephyr/dts/arm/nxp/nxp_mcxn94x_common.dtsi:74 */
			};

			/* node '/soc/peripheral@50000000/can@d8000' defined in zephyr/dts/arm/nxp/nxp_mcxn94x_common.dtsi:77 */
			flexcan1: can@d8000 {
				compatible = "nxp,flexcan";  /* in zephyr/dts/arm/nxp/nxp_mcxn94x_common.dtsi:78 */
				reg = < 0xd8000 0x4000 >;    /* in zephyr/dts/arm/nxp/nxp_mcxn94x_common.dtsi:79 */
				interrupts = < 0x3f 0x0 >;   /* in zephyr/dts/arm/nxp/nxp_mcxn94x_common.dtsi:80 */
				interrupt-names = "common";  /* in zephyr/dts/arm/nxp/nxp_mcxn94x_common.dtsi:81 */
				clocks = < &syscon 0x1001 >; /* in zephyr/dts/arm/nxp/nxp_mcxn94x_common.dtsi:82 */
				clk-source = < 0x0 >;        /* in zephyr/dts/arm/nxp/nxp_mcxn94x_common.dtsi:83 */
				status = "disabled";         /* in zephyr/dts/arm/nxp/nxp_mcxn94x_common.dtsi:84 */
			};
		};

		/* node '/soc/spi@500c8000' defined in zephyr/dts/arm/nxp/nxp_mcxn94x.dtsi:24 */
		flexspi: spi@500c8000 {
			reg = < 0x500c8000 0x1000 >,
			      < 0x90000000 0x800000 >;   /* in zephyr/dts/arm/nxp/nxp_mcxn94x.dtsi:25 */
			compatible = "nxp,imx-flexspi";  /* in zephyr/dts/arm/nxp/nxp_mcxnx4x_common.dtsi:1065 */
			interrupts = < 0x3a 0x0 >;       /* in zephyr/dts/arm/nxp/nxp_mcxnx4x_common.dtsi:1066 */
			#address-cells = < 0x1 >;        /* in zephyr/dts/arm/nxp/nxp_mcxnx4x_common.dtsi:1067 */
			#size-cells = < 0x0 >;           /* in zephyr/dts/arm/nxp/nxp_mcxnx4x_common.dtsi:1068 */
			clocks = < &syscon 0xa00 >;      /* in zephyr/dts/arm/nxp/nxp_mcxnx4x_common.dtsi:1070 */
			pinctrl-0 = < &pinmux_flexspi >; /* in zephyr/boards/nxp/frdm_mcxn947/frdm_mcxn947.dtsi:169 */
			pinctrl-names = "default";       /* in zephyr/boards/nxp/frdm_mcxn947/frdm_mcxn947.dtsi:170 */
			ahb-prefetch;                    /* in zephyr/boards/nxp/frdm_mcxn947/frdm_mcxn947.dtsi:171 */
			ahb-bufferable;                  /* in zephyr/boards/nxp/frdm_mcxn947/frdm_mcxn947.dtsi:172 */
			ahb-cacheable;                   /* in zephyr/boards/nxp/frdm_mcxn947/frdm_mcxn947.dtsi:173 */
			ahb-read-addr-opt;               /* in zephyr/boards/nxp/frdm_mcxn947/frdm_mcxn947.dtsi:174 */
			combination-mode;                /* in zephyr/boards/nxp/frdm_mcxn947/frdm_mcxn947.dtsi:175 */
			rx-clock-source = < 0x1 >;       /* in zephyr/boards/nxp/frdm_mcxn947/frdm_mcxn947.dtsi:176 */
			status = "okay";                 /* in zephyr/boards/nxp/frdm_mcxn947/frdm_mcxn947_mcxn947_cpu0.dtsi:132 */

			/* node '/soc/spi@500c8000/w25q64jvssiq@0' defined in zephyr/boards/nxp/frdm_mcxn947/frdm_mcxn947.dtsi:179 */
			w25q64jvssiq: w25q64jvssiq@0 {
				compatible = "nxp,imx-flexspi-nor"; /* in zephyr/boards/nxp/frdm_mcxn947/frdm_mcxn947.dtsi:180 */
				size = < 0x4000000 >;               /* in zephyr/boards/nxp/frdm_mcxn947/frdm_mcxn947.dtsi:182 */
				reg = < 0x0 >;                      /* in zephyr/boards/nxp/frdm_mcxn947/frdm_mcxn947.dtsi:183 */
				spi-max-frequency = < 0x7ed6b40 >;  /* in zephyr/boards/nxp/frdm_mcxn947/frdm_mcxn947.dtsi:184 */
				jedec-id = [ EF 40 17 ];            /* in zephyr/boards/nxp/frdm_mcxn947/frdm_mcxn947.dtsi:185 */
				erase-block-size = < 0x1000 >;      /* in zephyr/boards/nxp/frdm_mcxn947/frdm_mcxn947.dtsi:186 */
				write-block-size = < 0x1 >;         /* in zephyr/boards/nxp/frdm_mcxn947/frdm_mcxn947.dtsi:187 */
				cs-interval-unit = < 0x1 >;         /* in zephyr/boards/nxp/frdm_mcxn947/frdm_mcxn947.dtsi:188 */
				cs-interval = < 0x2 >;              /* in zephyr/boards/nxp/frdm_mcxn947/frdm_mcxn947.dtsi:189 */
				cs-hold-time = < 0x3 >;             /* in zephyr/boards/nxp/frdm_mcxn947/frdm_mcxn947.dtsi:190 */
				cs-setup-time = < 0x3 >;            /* in zephyr/boards/nxp/frdm_mcxn947/frdm_mcxn947.dtsi:191 */
				data-valid-time = < 0x2 >;          /* in zephyr/boards/nxp/frdm_mcxn947/frdm_mcxn947.dtsi:192 */
				column-space = < 0x0 >;             /* in zephyr/boards/nxp/frdm_mcxn947/frdm_mcxn947.dtsi:193 */
				status = "okay";                    /* in zephyr/boards/nxp/frdm_mcxn947/frdm_mcxn947_mcxn947_cpu0.dtsi:136 */

				/* node '/soc/spi@500c8000/w25q64jvssiq@0/partitions' defined in zephyr/boards/nxp/frdm_mcxn947/frdm_mcxn947_mcxn947_cpu0.dtsi:137 */
				partitions {
					compatible = "fixed-partitions"; /* in zephyr/boards/nxp/frdm_mcxn947/frdm_mcxn947_mcxn947_cpu0.dtsi:138 */
					#address-cells = < 0x1 >;        /* in zephyr/boards/nxp/frdm_mcxn947/frdm_mcxn947_mcxn947_cpu0.dtsi:139 */
					#size-cells = < 0x1 >;           /* in zephyr/boards/nxp/frdm_mcxn947/frdm_mcxn947_mcxn947_cpu0.dtsi:140 */

					/* node '/soc/spi@500c8000/w25q64jvssiq@0/partitions/partition@0' defined in zephyr/boards/nxp/frdm_mcxn947/frdm_mcxn947_mcxn947_cpu0.dtsi:141 */
					storage_partition: partition@0 {
						label = "storage";      /* in zephyr/boards/nxp/frdm_mcxn947/frdm_mcxn947_mcxn947_cpu0.dtsi:142 */
						reg = < 0x0 0x800000 >; /* in zephyr/boards/nxp/frdm_mcxn947/frdm_mcxn947_mcxn947_cpu0.dtsi:143 */
					};
				};
			};
		};
	};

	/* node '/cpus' defined in zephyr/dts/arm/nxp/nxp_mcxnx4x_common.dtsi:15 */
	cpus: cpus {
		#address-cells = < 0x1 >; /* in zephyr/dts/arm/nxp/nxp_mcxnx4x_common.dtsi:16 */
		#size-cells = < 0x0 >;    /* in zephyr/dts/arm/nxp/nxp_mcxnx4x_common.dtsi:17 */

		/* node '/cpus/cpu@0' defined in zephyr/dts/arm/nxp/nxp_mcxnx4x_common.dtsi:19 */
		cpu@0 {
			compatible = "arm,cortex-m33f"; /* in zephyr/dts/arm/nxp/nxp_mcxnx4x_common.dtsi:20 */
			reg = < 0x0 >;                  /* in zephyr/dts/arm/nxp/nxp_mcxnx4x_common.dtsi:21 */
			#address-cells = < 0x1 >;       /* in zephyr/dts/arm/nxp/nxp_mcxnx4x_common.dtsi:22 */
			#size-cells = < 0x1 >;          /* in zephyr/dts/arm/nxp/nxp_mcxnx4x_common.dtsi:23 */

			/* node '/cpus/cpu@0/mpu@e000ed90' defined in zephyr/dts/arm/nxp/nxp_mcxnx4x_common.dtsi:25 */
			mpu: mpu@e000ed90 {
				compatible = "arm,armv8m-mpu"; /* in zephyr/dts/arm/nxp/nxp_mcxnx4x_common.dtsi:26 */
				reg = < 0xe000ed90 0x40 >;     /* in zephyr/dts/arm/nxp/nxp_mcxnx4x_common.dtsi:27 */
			};
		};
	};

	/* node '/pinctrl' defined in zephyr/dts/arm/nxp/nxp_mcxnx4x_common.dtsi:38 */
	pinctrl: pinctrl {
		compatible = "nxp,port-pinctrl"; /* in zephyr/dts/arm/nxp/nxp_mcxnx4x_common.dtsi:39 */
		status = "okay";                 /* in zephyr/dts/arm/nxp/nxp_mcxnx4x_common.dtsi:40 */

		/* node '/pinctrl/pinmux_flexcomm1_lpspi' defined in zephyr/boards/nxp/frdm_mcxn947/frdm_mcxn947-pinctrl.dtsi:10 */
		pinmux_flexcomm1_lpspi: pinmux_flexcomm1_lpspi {
			phandle = < 0xa >; /* in zephyr/boards/nxp/frdm_mcxn947/frdm_mcxn947.dtsi:73 */

			/* node '/pinctrl/pinmux_flexcomm1_lpspi/group0' defined in zephyr/boards/nxp/frdm_mcxn947/frdm_mcxn947-pinctrl.dtsi:11 */
			group0 {
				pinmux = < 0x6000200 >,
				         < 0x6400200 >,
				         < 0x6800200 >,
				         < 0x6c00200 >; /* in zephyr/boards/nxp/frdm_mcxn947/frdm_mcxn947-pinctrl.dtsi:12 */
				slew-rate = "fast";     /* in zephyr/boards/nxp/frdm_mcxn947/frdm_mcxn947-pinctrl.dtsi:16 */
				drive-strength = "low"; /* in zephyr/boards/nxp/frdm_mcxn947/frdm_mcxn947-pinctrl.dtsi:17 */
				input-enable;           /* in zephyr/boards/nxp/frdm_mcxn947/frdm_mcxn947-pinctrl.dtsi:18 */
			};
		};

		/* node '/pinctrl/pinmux_flexcomm2_lpi2c' defined in zephyr/boards/nxp/frdm_mcxn947/frdm_mcxn947-pinctrl.dtsi:22 */
		pinmux_flexcomm2_lpi2c: pinmux_flexcomm2_lpi2c {
			phandle = < 0xc >; /* in zephyr/boards/nxp/frdm_mcxn947/frdm_mcxn947.dtsi:78 */

			/* node '/pinctrl/pinmux_flexcomm2_lpi2c/group0' defined in zephyr/boards/nxp/frdm_mcxn947/frdm_mcxn947-pinctrl.dtsi:23 */
			group0 {
				pinmux = < 0x40000200 >,
				         < 0x40400200 >; /* in zephyr/boards/nxp/frdm_mcxn947/frdm_mcxn947-pinctrl.dtsi:24 */
				slew-rate = "fast";      /* in zephyr/boards/nxp/frdm_mcxn947/frdm_mcxn947-pinctrl.dtsi:26 */
				drive-strength = "low";  /* in zephyr/boards/nxp/frdm_mcxn947/frdm_mcxn947-pinctrl.dtsi:27 */
				input-enable;            /* in zephyr/boards/nxp/frdm_mcxn947/frdm_mcxn947-pinctrl.dtsi:28 */
				bias-pull-up;            /* in zephyr/boards/nxp/frdm_mcxn947/frdm_mcxn947-pinctrl.dtsi:29 */
				drive-open-drain;        /* in zephyr/boards/nxp/frdm_mcxn947/frdm_mcxn947-pinctrl.dtsi:30 */
			};
		};

		/* node '/pinctrl/pinmux_flexcomm3_lpi2c' defined in zephyr/boards/nxp/frdm_mcxn947/frdm_mcxn947-pinctrl.dtsi:34 */
		pinmux_flexcomm3_lpi2c: pinmux_flexcomm3_lpi2c {

			/* node '/pinctrl/pinmux_flexcomm3_lpi2c/group0' defined in zephyr/boards/nxp/frdm_mcxn947/frdm_mcxn947-pinctrl.dtsi:35 */
			group0 {
				pinmux = < 0x10000200 >,
				         < 0x10400200 >; /* in zephyr/boards/nxp/frdm_mcxn947/frdm_mcxn947-pinctrl.dtsi:36 */
				slew-rate = "fast";      /* in zephyr/boards/nxp/frdm_mcxn947/frdm_mcxn947-pinctrl.dtsi:38 */
				drive-strength = "low";  /* in zephyr/boards/nxp/frdm_mcxn947/frdm_mcxn947-pinctrl.dtsi:39 */
				input-enable;            /* in zephyr/boards/nxp/frdm_mcxn947/frdm_mcxn947-pinctrl.dtsi:40 */
				bias-pull-up;            /* in zephyr/boards/nxp/frdm_mcxn947/frdm_mcxn947-pinctrl.dtsi:41 */
				drive-open-drain;        /* in zephyr/boards/nxp/frdm_mcxn947/frdm_mcxn947-pinctrl.dtsi:42 */
			};
		};

		/* node '/pinctrl/pimux_flexcomm7_lpi2c' defined in zephyr/boards/nxp/frdm_mcxn947/frdm_mcxn947-pinctrl.dtsi:46 */
		pinmux_flexcomm7_lpi2c: pimux_flexcomm7_lpi2c {
			phandle = < 0xe >; /* in zephyr/boards/nxp/frdm_mcxn947/frdm_mcxn947.dtsi:96 */

			/* node '/pinctrl/pimux_flexcomm7_lpi2c/group0' defined in zephyr/boards/nxp/frdm_mcxn947/frdm_mcxn947-pinctrl.dtsi:47 */
			group0 {
				pinmux = < 0x30800200 >,
				         < 0x30c00200 >; /* in zephyr/boards/nxp/frdm_mcxn947/frdm_mcxn947-pinctrl.dtsi:48 */
				slew-rate = "fast";      /* in zephyr/boards/nxp/frdm_mcxn947/frdm_mcxn947-pinctrl.dtsi:50 */
				drive-strength = "low";  /* in zephyr/boards/nxp/frdm_mcxn947/frdm_mcxn947-pinctrl.dtsi:51 */
				input-enable;            /* in zephyr/boards/nxp/frdm_mcxn947/frdm_mcxn947-pinctrl.dtsi:52 */
				bias-pull-up;            /* in zephyr/boards/nxp/frdm_mcxn947/frdm_mcxn947-pinctrl.dtsi:53 */
				drive-open-drain;        /* in zephyr/boards/nxp/frdm_mcxn947/frdm_mcxn947-pinctrl.dtsi:54 */
			};
		};

		/* node '/pinctrl/pinmux_flexcomm2_lpuart' defined in zephyr/boards/nxp/frdm_mcxn947/frdm_mcxn947-pinctrl.dtsi:58 */
		pinmux_flexcomm2_lpuart: pinmux_flexcomm2_lpuart {
			phandle = < 0xb >; /* in zephyr/boards/nxp/frdm_mcxn947/frdm_mcxn947.dtsi:85 */

			/* node '/pinctrl/pinmux_flexcomm2_lpuart/group0' defined in zephyr/boards/nxp/frdm_mcxn947/frdm_mcxn947-pinctrl.dtsi:59 */
			group0 {
				pinmux = < 0x40800200 >,
				         < 0x40c00200 >; /* in zephyr/boards/nxp/frdm_mcxn947/frdm_mcxn947-pinctrl.dtsi:60 */
				slew-rate = "fast";      /* in zephyr/boards/nxp/frdm_mcxn947/frdm_mcxn947-pinctrl.dtsi:62 */
				drive-strength = "low";  /* in zephyr/boards/nxp/frdm_mcxn947/frdm_mcxn947-pinctrl.dtsi:63 */
				input-enable;            /* in zephyr/boards/nxp/frdm_mcxn947/frdm_mcxn947-pinctrl.dtsi:64 */
			};
		};

		/* node '/pinctrl/pinmux_flexcomm4_lpuart' defined in zephyr/boards/nxp/frdm_mcxn947/frdm_mcxn947-pinctrl.dtsi:68 */
		pinmux_flexcomm4_lpuart: pinmux_flexcomm4_lpuart {
			phandle = < 0xd >; /* in zephyr/boards/nxp/frdm_mcxn947/frdm_mcxn947.dtsi:91 */

			/* node '/pinctrl/pinmux_flexcomm4_lpuart/group0' defined in zephyr/boards/nxp/frdm_mcxn947/frdm_mcxn947-pinctrl.dtsi:69 */
			group0 {
				pinmux = < 0x12000200 >,
				         < 0x12400200 >; /* in zephyr/boards/nxp/frdm_mcxn947/frdm_mcxn947-pinctrl.dtsi:70 */
				slew-rate = "fast";      /* in zephyr/boards/nxp/frdm_mcxn947/frdm_mcxn947-pinctrl.dtsi:72 */
				drive-strength = "low";  /* in zephyr/boards/nxp/frdm_mcxn947/frdm_mcxn947-pinctrl.dtsi:73 */
				input-enable;            /* in zephyr/boards/nxp/frdm_mcxn947/frdm_mcxn947-pinctrl.dtsi:74 */
			};
		};

		/* node '/pinctrl/pinmux_flexspi' defined in zephyr/boards/nxp/frdm_mcxn947/frdm_mcxn947-pinctrl.dtsi:78 */
		pinmux_flexspi: pinmux_flexspi {
			phandle = < 0x25 >; /* in zephyr/boards/nxp/frdm_mcxn947/frdm_mcxn947.dtsi:169 */

			/* node '/pinctrl/pinmux_flexspi/group0' defined in zephyr/boards/nxp/frdm_mcxn947/frdm_mcxn947-pinctrl.dtsi:79 */
			group0 {
				pinmux = < 0x30000800 >,
				         < 0x31c00800 >,
				         < 0x31800800 >,
				         < 0x32000800 >,
				         < 0x32400800 >; /* in zephyr/boards/nxp/frdm_mcxn947/frdm_mcxn947-pinctrl.dtsi:80 */
				input-enable;            /* in zephyr/boards/nxp/frdm_mcxn947/frdm_mcxn947-pinctrl.dtsi:85 */
				slew-rate = "fast";      /* in zephyr/boards/nxp/frdm_mcxn947/frdm_mcxn947-pinctrl.dtsi:86 */
				drive-strength = "low";  /* in zephyr/boards/nxp/frdm_mcxn947/frdm_mcxn947-pinctrl.dtsi:87 */
			};

			/* node '/pinctrl/pinmux_flexspi/group1' defined in zephyr/boards/nxp/frdm_mcxn947/frdm_mcxn947-pinctrl.dtsi:89 */
			group1 {
				pinmux = < 0x32800800 >,
				         < 0x32c00800 >; /* in zephyr/boards/nxp/frdm_mcxn947/frdm_mcxn947-pinctrl.dtsi:90 */
				input-enable;            /* in zephyr/boards/nxp/frdm_mcxn947/frdm_mcxn947-pinctrl.dtsi:92 */
				slew-rate = "fast";      /* in zephyr/boards/nxp/frdm_mcxn947/frdm_mcxn947-pinctrl.dtsi:93 */
				drive-strength = "low";  /* in zephyr/boards/nxp/frdm_mcxn947/frdm_mcxn947-pinctrl.dtsi:94 */
				bias-pull-up;            /* in zephyr/boards/nxp/frdm_mcxn947/frdm_mcxn947-pinctrl.dtsi:95 */
			};
		};

		/* node '/pinctrl/pinmux_dac0' defined in zephyr/boards/nxp/frdm_mcxn947/frdm_mcxn947-pinctrl.dtsi:99 */
		pinmux_dac0: pinmux_dac0 {
			phandle = < 0xf >; /* in zephyr/boards/nxp/frdm_mcxn947/frdm_mcxn947.dtsi:198 */

			/* node '/pinctrl/pinmux_dac0/group0' defined in zephyr/boards/nxp/frdm_mcxn947/frdm_mcxn947-pinctrl.dtsi:100 */
			group0 {
				pinmux = < 0x40800000 >; /* in zephyr/boards/nxp/frdm_mcxn947/frdm_mcxn947-pinctrl.dtsi:101 */
				drive-strength = "low";  /* in zephyr/boards/nxp/frdm_mcxn947/frdm_mcxn947-pinctrl.dtsi:102 */
				slew-rate = "fast";      /* in zephyr/boards/nxp/frdm_mcxn947/frdm_mcxn947-pinctrl.dtsi:103 */
			};
		};

		/* node '/pinctrl/pinmux_sai1' defined in zephyr/boards/nxp/frdm_mcxn947/frdm_mcxn947-pinctrl.dtsi:107 */
		pinmux_sai1: pinmux_sai1 {
			phandle = < 0x23 >; /* in zephyr/boards/nxp/frdm_mcxn947/frdm_mcxn947.dtsi:203 */

			/* node '/pinctrl/pinmux_sai1/group0' defined in zephyr/boards/nxp/frdm_mcxn947/frdm_mcxn947-pinctrl.dtsi:108 */
			group0 {
				pinmux = < 0x34000a00 >,
				         < 0x34400a00 >,
				         < 0x35000a00 >,
				         < 0x34c00a00 >,
				         < 0x34800a00 >,
				         < 0x35400a00 >; /* in zephyr/boards/nxp/frdm_mcxn947/frdm_mcxn947-pinctrl.dtsi:109 */
				drive-strength = "high"; /* in zephyr/boards/nxp/frdm_mcxn947/frdm_mcxn947-pinctrl.dtsi:115 */
				slew-rate = "fast";      /* in zephyr/boards/nxp/frdm_mcxn947/frdm_mcxn947-pinctrl.dtsi:116 */
				input-enable;            /* in zephyr/boards/nxp/frdm_mcxn947/frdm_mcxn947-pinctrl.dtsi:117 */
			};
		};

		/* node '/pinctrl/pinmux_sai0' defined in zephyr/boards/nxp/frdm_mcxn947/frdm_mcxn947-pinctrl.dtsi:121 */
		pinmux_sai0: pinmux_sai0 {
			phandle = < 0x21 >; /* in zephyr/boards/nxp/frdm_mcxn947/frdm_mcxn947.dtsi:208 */

			/* node '/pinctrl/pinmux_sai0/group0' defined in zephyr/boards/nxp/frdm_mcxn947/frdm_mcxn947-pinctrl.dtsi:122 */
			group0 {
				pinmux = < 0x20800a00 >,
				         < 0x21800a00 >,
				         < 0x21c00a00 >; /* in zephyr/boards/nxp/frdm_mcxn947/frdm_mcxn947-pinctrl.dtsi:123 */
				drive-strength = "high"; /* in zephyr/boards/nxp/frdm_mcxn947/frdm_mcxn947-pinctrl.dtsi:126 */
				slew-rate = "fast";      /* in zephyr/boards/nxp/frdm_mcxn947/frdm_mcxn947-pinctrl.dtsi:127 */
				input-enable;            /* in zephyr/boards/nxp/frdm_mcxn947/frdm_mcxn947-pinctrl.dtsi:128 */
			};
		};

		/* node '/pinctrl/pinmux_enet_qos' defined in zephyr/boards/nxp/frdm_mcxn947/frdm_mcxn947-pinctrl.dtsi:132 */
		pinmux_enet_qos: pinmux_enet_qos {
			phandle = < 0x10 >; /* in zephyr/boards/nxp/frdm_mcxn947/frdm_mcxn947.dtsi:213 */

			/* node '/pinctrl/pinmux_enet_qos/mdio_group' defined in zephyr/boards/nxp/frdm_mcxn947/frdm_mcxn947-pinctrl.dtsi:133 */
			mdio_group {
				pinmux = < 0x15000900 >,
				         < 0x15400900 >; /* in zephyr/boards/nxp/frdm_mcxn947/frdm_mcxn947-pinctrl.dtsi:134 */
				slew-rate = "fast";      /* in zephyr/boards/nxp/frdm_mcxn947/frdm_mcxn947-pinctrl.dtsi:136 */
				drive-strength = "low";  /* in zephyr/boards/nxp/frdm_mcxn947/frdm_mcxn947-pinctrl.dtsi:137 */
				input-enable;            /* in zephyr/boards/nxp/frdm_mcxn947/frdm_mcxn947-pinctrl.dtsi:138 */
			};

			/* node '/pinctrl/pinmux_enet_qos/mac_group' defined in zephyr/boards/nxp/frdm_mcxn947/frdm_mcxn947-pinctrl.dtsi:140 */
			mac_group {
				pinmux = < 0x13400900 >,
				         < 0x13800900 >,
				         < 0x13c00900 >,
				         < 0x11000900 >,
				         < 0x11400900 >,
				         < 0x11800900 >,
				         < 0x11c00900 >; /* in zephyr/boards/nxp/frdm_mcxn947/frdm_mcxn947-pinctrl.dtsi:141 */
				slew-rate = "fast";      /* in zephyr/boards/nxp/frdm_mcxn947/frdm_mcxn947-pinctrl.dtsi:148 */
				drive-strength = "low";  /* in zephyr/boards/nxp/frdm_mcxn947/frdm_mcxn947-pinctrl.dtsi:149 */
				input-enable;            /* in zephyr/boards/nxp/frdm_mcxn947/frdm_mcxn947-pinctrl.dtsi:150 */
			};
		};

		/* node '/pinctrl/pinmux_flexpwm1_pwm0' defined in zephyr/boards/nxp/frdm_mcxn947/frdm_mcxn947-pinctrl.dtsi:154 */
		pinmux_flexpwm1_pwm0: pinmux_flexpwm1_pwm0 {
			phandle = < 0x24 >; /* in zephyr/boards/nxp/frdm_mcxn947/frdm_mcxn947.dtsi:232 */

			/* node '/pinctrl/pinmux_flexpwm1_pwm0/group0' defined in zephyr/boards/nxp/frdm_mcxn947/frdm_mcxn947-pinctrl.dtsi:155 */
			group0 {
				pinmux = < 0x21800500 >,
				         < 0x21c00500 >; /* in zephyr/boards/nxp/frdm_mcxn947/frdm_mcxn947-pinctrl.dtsi:156 */
				slew-rate = "fast";      /* in zephyr/boards/nxp/frdm_mcxn947/frdm_mcxn947-pinctrl.dtsi:158 */
				drive-strength = "low";  /* in zephyr/boards/nxp/frdm_mcxn947/frdm_mcxn947-pinctrl.dtsi:159 */
			};
		};

		/* node '/pinctrl/pinmux_flexpwm1_pwm1' defined in zephyr/boards/nxp/frdm_mcxn947/frdm_mcxn947-pinctrl.dtsi:163 */
		pinmux_flexpwm1_pwm1: pinmux_flexpwm1_pwm1 {

			/* node '/pinctrl/pinmux_flexpwm1_pwm1/group0' defined in zephyr/boards/nxp/frdm_mcxn947/frdm_mcxn947-pinctrl.dtsi:164 */
			group0 {
				pinmux = < 0x21000500 >,
				         < 0x21400500 >; /* in zephyr/boards/nxp/frdm_mcxn947/frdm_mcxn947-pinctrl.dtsi:165 */
				slew-rate = "fast";      /* in zephyr/boards/nxp/frdm_mcxn947/frdm_mcxn947-pinctrl.dtsi:167 */
				drive-strength = "low";  /* in zephyr/boards/nxp/frdm_mcxn947/frdm_mcxn947-pinctrl.dtsi:168 */
			};
		};

		/* node '/pinctrl/pinmux_flexpwm1_pwm2' defined in zephyr/boards/nxp/frdm_mcxn947/frdm_mcxn947-pinctrl.dtsi:172 */
		pinmux_flexpwm1_pwm2: pinmux_flexpwm1_pwm2 {

			/* node '/pinctrl/pinmux_flexpwm1_pwm2/group0' defined in zephyr/boards/nxp/frdm_mcxn947/frdm_mcxn947-pinctrl.dtsi:173 */
			group0 {
				pinmux = < 0x20800500 >,
				         < 0x20c00500 >; /* in zephyr/boards/nxp/frdm_mcxn947/frdm_mcxn947-pinctrl.dtsi:174 */
				slew-rate = "fast";      /* in zephyr/boards/nxp/frdm_mcxn947/frdm_mcxn947-pinctrl.dtsi:176 */
				drive-strength = "low";  /* in zephyr/boards/nxp/frdm_mcxn947/frdm_mcxn947-pinctrl.dtsi:177 */
			};
		};

		/* node '/pinctrl/pinmux_smartdma_camera' defined in zephyr/boards/nxp/frdm_mcxn947/frdm_mcxn947-pinctrl.dtsi:181 */
		pinmux_smartdma_camera: pinmux_smartdma_camera {
			phandle = < 0x13 >; /* in zephyr/boards/nxp/frdm_mcxn947/frdm_mcxn947.dtsi:110 */

			/* node '/pinctrl/pinmux_smartdma_camera/group0' defined in zephyr/boards/nxp/frdm_mcxn947/frdm_mcxn947-pinctrl.dtsi:182 */
			group0 {
				pinmux = < 0x11000700 >,
				         < 0x11400700 >,
				         < 0x11800700 >,
				         < 0x11c00700 >,
				         < 0x31000700 >,
				         < 0x31400700 >,
				         < 0x12800700 >,
				         < 0x12c00700 >,
				         < 0x1000000 >,
				         < 0x1400000 >,
				         < 0x2c00000 >,
				         < 0x20800100 >,
				         < 0x1800c00 >;  /* in zephyr/boards/nxp/frdm_mcxn947/frdm_mcxn947-pinctrl.dtsi:187 */
				drive-strength = "low";  /* in zephyr/boards/nxp/frdm_mcxn947/frdm_mcxn947-pinctrl.dtsi:200 */
				slew-rate = "fast";      /* in zephyr/boards/nxp/frdm_mcxn947/frdm_mcxn947-pinctrl.dtsi:201 */
				input-enable;            /* in zephyr/boards/nxp/frdm_mcxn947/frdm_mcxn947-pinctrl.dtsi:202 */
			};
		};

		/* node '/pinctrl/pinmux_usdhc0' defined in zephyr/boards/nxp/frdm_mcxn947/frdm_mcxn947-pinctrl.dtsi:206 */
		pinmux_usdhc0: pinmux_usdhc0 {
			phandle = < 0x14 >; /* in zephyr/boards/nxp/frdm_mcxn947/frdm_mcxn947.dtsi:237 */

			/* node '/pinctrl/pinmux_usdhc0/group0' defined in zephyr/boards/nxp/frdm_mcxn947/frdm_mcxn947-pinctrl.dtsi:207 */
			group0 {
				pinmux = < 0x21400300 >,
				         < 0x20c00300 >,
				         < 0x20800300 >,
				         < 0x21c00300 >,
				         < 0x21800300 >; /* in zephyr/boards/nxp/frdm_mcxn947/frdm_mcxn947-pinctrl.dtsi:208 */
				slew-rate = "fast";      /* in zephyr/boards/nxp/frdm_mcxn947/frdm_mcxn947-pinctrl.dtsi:213 */
				drive-strength = "low";  /* in zephyr/boards/nxp/frdm_mcxn947/frdm_mcxn947-pinctrl.dtsi:214 */
				bias-pull-up;            /* in zephyr/boards/nxp/frdm_mcxn947/frdm_mcxn947-pinctrl.dtsi:215 */
				input-enable;            /* in zephyr/boards/nxp/frdm_mcxn947/frdm_mcxn947-pinctrl.dtsi:216 */
			};

			/* node '/pinctrl/pinmux_usdhc0/group1' defined in zephyr/boards/nxp/frdm_mcxn947/frdm_mcxn947-pinctrl.dtsi:218 */
			group1 {
				pinmux = < 0x21000300 >; /* in zephyr/boards/nxp/frdm_mcxn947/frdm_mcxn947-pinctrl.dtsi:219 */
				slew-rate = "fast";      /* in zephyr/boards/nxp/frdm_mcxn947/frdm_mcxn947-pinctrl.dtsi:220 */
				drive-strength = "low";  /* in zephyr/boards/nxp/frdm_mcxn947/frdm_mcxn947-pinctrl.dtsi:221 */
				input-enable;            /* in zephyr/boards/nxp/frdm_mcxn947/frdm_mcxn947-pinctrl.dtsi:222 */
			};
		};

		/* node '/pinctrl/pinmux_lpadc0' defined in zephyr/boards/nxp/frdm_mcxn947/frdm_mcxn947-pinctrl.dtsi:226 */
		pinmux_lpadc0: pinmux_lpadc0 {
			phandle = < 0x17 >; /* in zephyr/boards/nxp/frdm_mcxn947/frdm_mcxn947.dtsi:246 */

			/* node '/pinctrl/pinmux_lpadc0/group0' defined in zephyr/boards/nxp/frdm_mcxn947/frdm_mcxn947-pinctrl.dtsi:227 */
			group0 {
				pinmux = < 0x45c00000 >,
				         < 0x43c00000 >,
				         < 0x44c00000 >; /* in zephyr/boards/nxp/frdm_mcxn947/frdm_mcxn947-pinctrl.dtsi:228 */
				slew-rate = "fast";      /* in zephyr/boards/nxp/frdm_mcxn947/frdm_mcxn947-pinctrl.dtsi:231 */
				drive-strength = "low";  /* in zephyr/boards/nxp/frdm_mcxn947/frdm_mcxn947-pinctrl.dtsi:232 */
			};
		};

		/* node '/pinctrl/pinmux_lpcmp0' defined in zephyr/boards/nxp/frdm_mcxn947/frdm_mcxn947-pinctrl.dtsi:236 */
		pinmux_lpcmp0: pinmux_lpcmp0 {
			phandle = < 0x19 >; /* in zephyr/boards/nxp/frdm_mcxn947/frdm_mcxn947.dtsi:267 */

			/* node '/pinctrl/pinmux_lpcmp0/group0' defined in zephyr/boards/nxp/frdm_mcxn947/frdm_mcxn947-pinctrl.dtsi:237 */
			group0 {
				pinmux = < 0x10000000 >; /* in zephyr/boards/nxp/frdm_mcxn947/frdm_mcxn947-pinctrl.dtsi:238 */
				drive-strength = "low";  /* in zephyr/boards/nxp/frdm_mcxn947/frdm_mcxn947-pinctrl.dtsi:239 */
				slew-rate = "fast";      /* in zephyr/boards/nxp/frdm_mcxn947/frdm_mcxn947-pinctrl.dtsi:240 */
				bias-pull-up;            /* in zephyr/boards/nxp/frdm_mcxn947/frdm_mcxn947-pinctrl.dtsi:241 */
			};
		};

		/* node '/pinctrl/pinmux_flexcan0' defined in zephyr/boards/nxp/frdm_mcxn947/frdm_mcxn947-pinctrl.dtsi:245 */
		pinmux_flexcan0: pinmux_flexcan0 {
			phandle = < 0x1a >; /* in zephyr/boards/nxp/frdm_mcxn947/frdm_mcxn947.dtsi:277 */

			/* node '/pinctrl/pinmux_flexcan0/group0' defined in zephyr/boards/nxp/frdm_mcxn947/frdm_mcxn947-pinctrl.dtsi:246 */
			group0 {
				pinmux = < 0x12800b00 >,
				         < 0x12c00b00 >; /* in zephyr/boards/nxp/frdm_mcxn947/frdm_mcxn947-pinctrl.dtsi:247 */
				slew-rate = "fast";      /* in zephyr/boards/nxp/frdm_mcxn947/frdm_mcxn947-pinctrl.dtsi:249 */
				drive-strength = "low";  /* in zephyr/boards/nxp/frdm_mcxn947/frdm_mcxn947-pinctrl.dtsi:250 */
				input-enable;            /* in zephyr/boards/nxp/frdm_mcxn947/frdm_mcxn947-pinctrl.dtsi:251 */
			};
		};

		/* node '/pinctrl/pinmux_i3c1' defined in zephyr/boards/nxp/frdm_mcxn947/frdm_mcxn947-pinctrl.dtsi:255 */
		pinmux_i3c1: pinmux_i3c1 {
			phandle = < 0x1b >; /* in zephyr/boards/nxp/frdm_mcxn947/frdm_mcxn947.dtsi:272 */

			/* node '/pinctrl/pinmux_i3c1/group0' defined in zephyr/boards/nxp/frdm_mcxn947/frdm_mcxn947-pinctrl.dtsi:256 */
			group0 {
				pinmux = < 0x14000a00 >,
				         < 0x14400a00 >; /* in zephyr/boards/nxp/frdm_mcxn947/frdm_mcxn947-pinctrl.dtsi:257 */
				slew-rate = "fast";      /* in zephyr/boards/nxp/frdm_mcxn947/frdm_mcxn947-pinctrl.dtsi:259 */
				drive-strength = "low";  /* in zephyr/boards/nxp/frdm_mcxn947/frdm_mcxn947-pinctrl.dtsi:260 */
				input-enable;            /* in zephyr/boards/nxp/frdm_mcxn947/frdm_mcxn947-pinctrl.dtsi:261 */
				bias-pull-up;            /* in zephyr/boards/nxp/frdm_mcxn947/frdm_mcxn947-pinctrl.dtsi:262 */
			};

			/* node '/pinctrl/pinmux_i3c1/group1' defined in zephyr/boards/nxp/frdm_mcxn947/frdm_mcxn947-pinctrl.dtsi:264 */
			group1 {
				pinmux = < 0x12c00a00 >; /* in zephyr/boards/nxp/frdm_mcxn947/frdm_mcxn947-pinctrl.dtsi:265 */
				slew-rate = "fast";      /* in zephyr/boards/nxp/frdm_mcxn947/frdm_mcxn947-pinctrl.dtsi:266 */
				drive-strength = "low";  /* in zephyr/boards/nxp/frdm_mcxn947/frdm_mcxn947-pinctrl.dtsi:267 */
				input-enable;            /* in zephyr/boards/nxp/frdm_mcxn947/frdm_mcxn947-pinctrl.dtsi:268 */
			};
		};

		/* node '/pinctrl/pinmux_sctimer' defined in zephyr/boards/nxp/frdm_mcxn947/frdm_mcxn947-pinctrl.dtsi:272 */
		pinmux_sctimer: pinmux_sctimer {
			phandle = < 0x12 >; /* in zephyr/boards/nxp/frdm_mcxn947/frdm_mcxn947.dtsi:282 */

			/* node '/pinctrl/pinmux_sctimer/group0' defined in zephyr/boards/nxp/frdm_mcxn947/frdm_mcxn947-pinctrl.dtsi:273 */
			group0 {
				pinmux = < 0x20800400 >; /* in zephyr/boards/nxp/frdm_mcxn947/frdm_mcxn947-pinctrl.dtsi:274 */
				slew-rate = "fast";      /* in zephyr/boards/nxp/frdm_mcxn947/frdm_mcxn947-pinctrl.dtsi:275 */
				drive-strength = "low";  /* in zephyr/boards/nxp/frdm_mcxn947/frdm_mcxn947-pinctrl.dtsi:276 */
				input-enable;            /* in zephyr/boards/nxp/frdm_mcxn947/frdm_mcxn947-pinctrl.dtsi:277 */
			};
		};

		/* node '/pinctrl/pinmux_flexio_lcd' defined in zephyr/boards/nxp/frdm_mcxn947/frdm_mcxn947-pinctrl.dtsi:281 */
		pinmux_flexio_lcd: pinmux_flexio_lcd {
			phandle = < 0x1e >; /* in zephyr/boards/nxp/frdm_mcxn947/frdm_mcxn947.dtsi:262 */

			/* node '/pinctrl/pinmux_flexio_lcd/group0' defined in zephyr/boards/nxp/frdm_mcxn947/frdm_mcxn947-pinctrl.dtsi:282 */
			group0 {
				pinmux = < 0x22000600 >,
				         < 0x22400600 >,
				         < 0x22800600 >,
				         < 0x22c00600 >,
				         < 0x43000600 >,
				         < 0x43400600 >,
				         < 0x43800600 >,
				         < 0x43c00600 >,
				         < 0x44000600 >,
				         < 0x44400600 >,
				         < 0x44800600 >,
				         < 0x44c00600 >,
				         < 0x45000600 >,
				         < 0x45400600 >,
				         < 0x45800600 >,
				         < 0x45c00600 >,
				         < 0x1c00000 >,
				         < 0x3000000 >,
				         < 0x41c00000 >; /* in zephyr/boards/nxp/frdm_mcxn947/frdm_mcxn947-pinctrl.dtsi:283 */
				slew-rate = "fast";      /* in zephyr/boards/nxp/frdm_mcxn947/frdm_mcxn947-pinctrl.dtsi:302 */
				drive-strength = "low";  /* in zephyr/boards/nxp/frdm_mcxn947/frdm_mcxn947-pinctrl.dtsi:303 */
				input-enable;            /* in zephyr/boards/nxp/frdm_mcxn947/frdm_mcxn947-pinctrl.dtsi:304 */
			};

			/* node '/pinctrl/pinmux_flexio_lcd/group1' defined in zephyr/boards/nxp/frdm_mcxn947/frdm_mcxn947-pinctrl.dtsi:306 */
			group1 {
				pinmux = < 0x2000600 >; /* in zephyr/boards/nxp/frdm_mcxn947/frdm_mcxn947-pinctrl.dtsi:307 */
				slew-rate = "fast";     /* in zephyr/boards/nxp/frdm_mcxn947/frdm_mcxn947-pinctrl.dtsi:308 */
				drive-strength = "low"; /* in zephyr/boards/nxp/frdm_mcxn947/frdm_mcxn947-pinctrl.dtsi:309 */
				input-enable;           /* in zephyr/boards/nxp/frdm_mcxn947/frdm_mcxn947-pinctrl.dtsi:310 */
				bias-pull-up;           /* in zephyr/boards/nxp/frdm_mcxn947/frdm_mcxn947-pinctrl.dtsi:311 */
			};

			/* node '/pinctrl/pinmux_flexio_lcd/group2' defined in zephyr/boards/nxp/frdm_mcxn947/frdm_mcxn947-pinctrl.dtsi:313 */
			group2 {
				pinmux = < 0x2400600 >; /* in zephyr/boards/nxp/frdm_mcxn947/frdm_mcxn947-pinctrl.dtsi:314 */
				slew-rate = "slow";     /* in zephyr/boards/nxp/frdm_mcxn947/frdm_mcxn947-pinctrl.dtsi:315 */
				drive-strength = "low"; /* in zephyr/boards/nxp/frdm_mcxn947/frdm_mcxn947-pinctrl.dtsi:316 */
				input-enable;           /* in zephyr/boards/nxp/frdm_mcxn947/frdm_mcxn947-pinctrl.dtsi:317 */
				bias-pull-up;           /* in zephyr/boards/nxp/frdm_mcxn947/frdm_mcxn947-pinctrl.dtsi:318 */
			};
		};
	};

	/* node '/leds' defined in zephyr/boards/nxp/frdm_mcxn947/frdm_mcxn947.dtsi:23 */
	leds {
		compatible = "gpio-leds"; /* in zephyr/boards/nxp/frdm_mcxn947/frdm_mcxn947.dtsi:24 */

		/* node '/leds/led_1' defined in zephyr/boards/nxp/frdm_mcxn947/frdm_mcxn947.dtsi:25 */
		green_led: led_1 {
			gpios = < &gpio0 0x1b 0x1 >; /* in zephyr/boards/nxp/frdm_mcxn947/frdm_mcxn947.dtsi:26 */
			label = "Green LED";         /* in zephyr/boards/nxp/frdm_mcxn947/frdm_mcxn947.dtsi:27 */
			status = "okay";             /* in zephyr/boards/nxp/frdm_mcxn947/frdm_mcxn947_mcxn947_cpu0.dtsi:76 */
		};

		/* node '/leds/led_2' defined in zephyr/boards/nxp/frdm_mcxn947/frdm_mcxn947.dtsi:30 */
		blue_led: led_2 {
			gpios = < &gpio1 0x2 0x1 >; /* in zephyr/boards/nxp/frdm_mcxn947/frdm_mcxn947.dtsi:31 */
			label = "Blue LED";         /* in zephyr/boards/nxp/frdm_mcxn947/frdm_mcxn947.dtsi:32 */
			status = "disabled";        /* in zephyr/boards/nxp/frdm_mcxn947/frdm_mcxn947.dtsi:33 */
		};

		/* node '/leds/led_3' defined in zephyr/boards/nxp/frdm_mcxn947/frdm_mcxn947.dtsi:35 */
		red_led: led_3 {
			gpios = < &gpio0 0xa 0x1 >; /* in zephyr/boards/nxp/frdm_mcxn947/frdm_mcxn947.dtsi:36 */
			label = "Red LED";          /* in zephyr/boards/nxp/frdm_mcxn947/frdm_mcxn947.dtsi:37 */
			status = "okay";            /* in zephyr/boards/nxp/frdm_mcxn947/frdm_mcxn947_mcxn947_cpu0.dtsi:80 */
		};
	};

	/* node '/gpio_keys' defined in zephyr/boards/nxp/frdm_mcxn947/frdm_mcxn947.dtsi:42 */
	gpio_keys {
		compatible = "gpio-keys"; /* in zephyr/boards/nxp/frdm_mcxn947/frdm_mcxn947.dtsi:43 */

		/* node '/gpio_keys/button_0' defined in zephyr/boards/nxp/frdm_mcxn947/frdm_mcxn947.dtsi:44 */
		user_button_2: button_0 {
			label = "User SW2";           /* in zephyr/boards/nxp/frdm_mcxn947/frdm_mcxn947.dtsi:45 */
			gpios = < &gpio0 0x17 0x11 >; /* in zephyr/boards/nxp/frdm_mcxn947/frdm_mcxn947.dtsi:46 */
			zephyr,code = < 0xb >;        /* in zephyr/boards/nxp/frdm_mcxn947/frdm_mcxn947.dtsi:47 */
			status = "okay";              /* in zephyr/boards/nxp/frdm_mcxn947/frdm_mcxn947_mcxn947_cpu0.dtsi:84 */
		};

		/* node '/gpio_keys/button_1' defined in zephyr/boards/nxp/frdm_mcxn947/frdm_mcxn947.dtsi:50 */
		user_button_3: button_1 {
			label = "User SW3";          /* in zephyr/boards/nxp/frdm_mcxn947/frdm_mcxn947.dtsi:51 */
			gpios = < &gpio0 0x6 0x11 >; /* in zephyr/boards/nxp/frdm_mcxn947/frdm_mcxn947.dtsi:52 */
			zephyr,code = < 0x2 >;       /* in zephyr/boards/nxp/frdm_mcxn947/frdm_mcxn947.dtsi:53 */
			status = "disabled";         /* in zephyr/boards/nxp/frdm_mcxn947/frdm_mcxn947.dtsi:54 */
		};
	};

	/* node '/lcd-8080-connector' defined in zephyr/boards/nxp/frdm_mcxn947/frdm_mcxn947.dtsi:61 */
	nxp_lcd_8080_connector: lcd-8080-connector {
		compatible = "nxp,lcd-8080";               /* in zephyr/boards/nxp/frdm_mcxn947/frdm_mcxn947.dtsi:62 */
		#gpio-cells = < 0x2 >;                     /* in zephyr/boards/nxp/frdm_mcxn947/frdm_mcxn947.dtsi:63 */
		gpio-map-mask = < 0xffffffff 0xffffffc0 >; /* in zephyr/boards/nxp/frdm_mcxn947/frdm_mcxn947.dtsi:64 */
		gpio-map-pass-thru = < 0x0 0x3f >;         /* in zephyr/boards/nxp/frdm_mcxn947/frdm_mcxn947.dtsi:65 */
		gpio-map = < 0x9 0x0 &gpio4 0x6 0x0 >,
		           < 0xa 0x0 &gpio4 0x5 0x0 >,
		           < 0xb 0x0 &gpio4 0x7 0x0 >;     /* in zephyr/boards/nxp/frdm_mcxn947/frdm_mcxn947.dtsi:66 */
	};

	/* node '/dvp-20pin-connector' defined in zephyr/boards/nxp/frdm_mcxn947/frdm_mcxn947.dtsi:291 */
	dvp_20pin_connector: dvp-20pin-connector {
		compatible = "arducam,dvp-20pin-connector"; /* in zephyr/boards/nxp/frdm_mcxn947/frdm_mcxn947.dtsi:292 */
		#gpio-cells = < 0x2 >;                      /* in zephyr/boards/nxp/frdm_mcxn947/frdm_mcxn947.dtsi:293 */
		gpio-map-mask = < 0xffffffff 0xffffffc0 >;  /* in zephyr/boards/nxp/frdm_mcxn947/frdm_mcxn947.dtsi:294 */
		gpio-map-pass-thru = < 0x0 0x3f >;          /* in zephyr/boards/nxp/frdm_mcxn947/frdm_mcxn947.dtsi:295 */
		gpio-map = < 0x11 0x0 &gpio1 0x13 0x0 >,
		           < 0x12 0x0 &gpio1 0x12 0x0 >;    /* in zephyr/boards/nxp/frdm_mcxn947/frdm_mcxn947.dtsi:296 */
	};
};
